VERSION ""

NS_ :

BS_:

BU_: PowertrainControlModule AtmosphericSensor SafetyRestraintSystem2 Aftertreatment_2_GasOutlet Aftertreatment_2_GasIntake DieselParticulateFilterControl Turbocharger SafetyRestraintSystem1 CabDisplay2 Aftertreatment_1_GasOutlet Aftertreatment_1_GasIntake OnBoardDataLogger OffBoardDiagnosticTool2 OffBoardDiagnosticTool1 FileServer ParkingBrakeController SeatController2 FanDriveController SteeringColumnUnit CommunicationUnitRadio CommunicationUnitSatellite CommunicationUnitCellular PropulsionBatteryCharger ChassisController2 ChassisController1 EngineValveControl AuxiliaryHeater2 AuxiliaryHeater1 ClutchUnit RampControl InformationSystem1 SuspensionSystemController2 OilSensor VehicleDynamicStability ExhaustEmissionController TransmissionDisplay2 TransmissionDisplay1 ClimateControl2 WaterPumpController RearAxleSteeringController LightingOperatorControl SeatController1 IgnitionController2 IgnitionController1 TirePressureController CabController2 CabController1 PneumaticSystemController SuspensionSystemController1 HydraulicPumpController EnduranceBrakingSystem RetarderExhaustEngine2 OnBoardDiagnosticUnit HeadwayController RetarderExhaustEngine1 CabDisplay1 ManagementComputer VirtualTerminal OffVehicleGateway PowerTakeOffFront HitchControl AuxiliaryValveControl BodyController TractorTrailerBridge1 StarterSystem ElectricalSystem VehicleSecurity VehicleNavigation AerodynamicControl ElectricalChargingSystem ClimateControl1 TripRecorder InstrumentCluster SuspensionDriveAxle2 SuspensionDriveAxle1 SuspensionSteerAxle SteeringController FuelSystem CruiseControl RetarderDriveline RetarderEngine BrakesDriveAxle2 BrakesDriveAxle1 BrakesSystemController BrakesSteerAxle AxleDrive2 AxleDrive1 AxleSteering PowerTakeOff ShiftConsoleSecondary ShiftConsolePrimary Transmission2 Transmission1 Engine2 Engine1

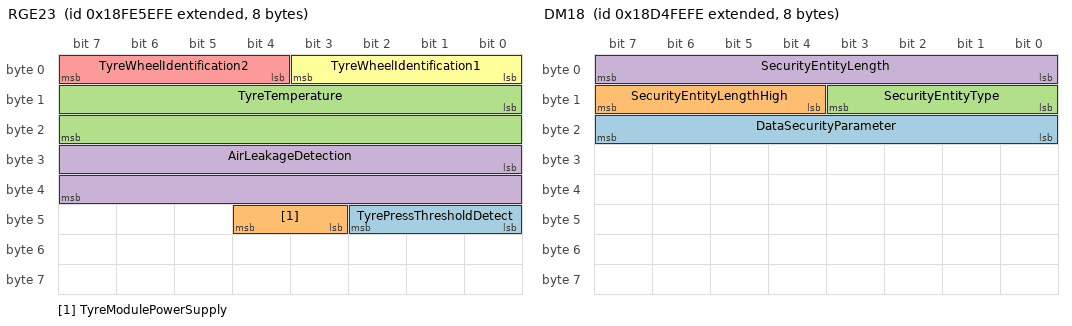
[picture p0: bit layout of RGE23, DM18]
BO_ 2566807294 RGE23: 8 Vector__XXX
 SG_ TyrePressThresholdDetect : 40|3@1+ (1,0) [0|7] "" Vector__XXX
 SG_ TyreModulePowerSupply : 43|2@1+ (1,0) [0|1] "" Vector__XXX
 SG_ TyreTemperature : 8|16@1+ (0.03125,-273) [-273|1735] "캜" Vector__XXX
 SG_ AirLeakageDetection : 24|16@1+ (0.1,0) [0|6425.5] "Pa/s" Vector__XXX
 SG_ TyreWheelIdentification2 : 4|4@1+ (1,0) [0|15] "" Vector__XXX
 SG_ TyreWheelIdentification1 : 0|4@1+ (1,0) [0|15] "" Vector__XXX

BO_ 2566764798 DM26: 8 Vector__XXX
 SG_ NMHCConvertingCatalystCompleted : 60|1@1+ (1,0) [0|1] "" Vector__XXX
 SG_ NMHCConvertingCatalystEnabled : 44|1@1+ (1,0) [0|1] "" Vector__XXX
 SG_ NOxConvertingCatalstAdsrbrCmpltd : 59|1@1+ (1,0) [0|1] "" Vector__XXX
 SG_ NOxConvertingCatalystAdsorberEna : 43|1@1+ (1,0) [0|1] "" Vector__XXX
 SG_ DieselParticulateFilterCompleted : 58|1@1+ (1,0) [0|1] "" Vector__XXX
 SG_ DieselParticulateFilterEnabled : 42|1@1+ (1,0) [0|1] "" Vector__XXX
 SG_ BoostPressureControlSystemComple : 57|1@1+ (1,0) [0|1] "" Vector__XXX
 SG_ BoostPressureControlSystemEnable : 41|1@1- (1,0) [0|0] "" Vector__XXX
 SG_ MisfireMonitoringComplete : 28|1@1+ (1,0) [0|1] "" Vector__XXX
 SG_ MisfireMonitoringEnabled : 24|1@1+ (1,0) [0|0] "" Vector__XXX
 SG_ FuelSystemMonitoringEnabled : 25|1@1+ (1,0) [0|1] "" Vector__XXX
 SG_ ComprehensiveComptMonComplete : 30|1@1+ (1,0) [0|1] "" Vector__XXX
 SG_ ComprehensiveCompMonEnabled : 26|1@1+ (1,0) [0|1] "" Vector__XXX
 SG_ SecondAirSystemMonComplete : 51|1@1+ (1,0) [0|1] "" Vector__XXX
 SG_ SecondAirSystemMonEnabled : 35|1@1+ (1,0) [0|1] "" Vector__XXX
 SG_ OxygenSensorMonComplete : 53|1@1+ (1,0) [0|1] "" Vector__XXX
 SG_ OxygenSensorMonEnabled : 37|1@1+ (1,0) [0|1] "" Vector__XXX
 SG_ OxygenSensorHeaterMonComplete : 54|1@1+ (1,0) [0|1] "" Vector__XXX
 SG_ OxygenSensorHeaterMonEnabled : 38|1@1+ (1,0) [0|1] "" Vector__XXX
 SG_ HeatedCatalystMonComplete : 49|1@1+ (1,0) [0|1] "" Vector__XXX
 SG_ HeatedCatalystMonEnabled : 33|1@1+ (1,0) [0|1] "" Vector__XXX
 SG_ EvaporativeSystemMonComplete : 50|1@1+ (1,0) [0|1] "" Vector__XXX
 SG_ EvaporativeSystemMonEnabled : 34|1@1+ (1,0) [0|1] "" Vector__XXX
 SG_ EGRSystemMonitoringComplete : 55|1@1+ (1,0) [0|1] "" Vector__XXX
 SG_ EGRSystemMonitoringEnabled : 39|1@1+ (1,0) [0|1] "" Vector__XXX
 SG_ ColdStartAidSystemMonComplete : 56|1@1+ (1,0) [0|1] "" Vector__XXX
 SG_ ColdStartAidSystemMonEnabled : 40|1@1+ (1,0) [0|1] "" Vector__XXX
 SG_ CatalystMonComplete : 48|1@1+ (1,0) [0|1] "" Vector__XXX
 SG_ CatalystMonEnabled : 32|1@1+ (1,0) [0|1] "" Vector__XXX
 SG_ ACSystemRefrigerantMonComplete : 52|1@1+ (1,0) [0|1] "" Vector__XXX
 SG_ ACSystemRefrigerantMonEnabled : 36|1@1+ (1,0) [0|1] "" Vector__XXX
 SG_ FuelSystemMonitoringComplete : 29|1@1+ (1,0) [0|1] "" Vector__XXX
 SG_ NumOfWarmUpsSinceDTCsCleared : 16|8@1+ (1,0) [0|250] "" Vector__XXX
 SG_ TimeSinceEngineStart : 0|16@1+ (1,0) [0|64255] "s" Vector__XXX

BO_ 2564095742 DM18: 8 Vector__XXX
 SG_ DataSecurityParameter : 16|8@1+ (1,0) [0|0] "" Vector__XXX
 SG_ SecurityEntityLengthHigh : 12|4@1+ (1,0) [0|255] "Byte" Vector__XXX
 SG_ SecurityEntityType : 8|4@1+ (1,0) [0|15] "" Vector__XXX
 SG_ SecurityEntityLength : 0|8@1+ (1,0) [0|4095] "" Vector__XXX

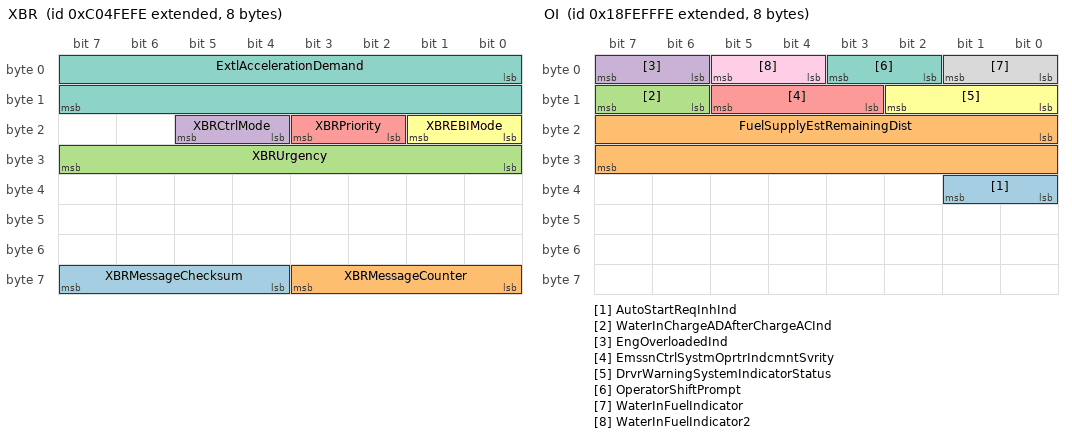
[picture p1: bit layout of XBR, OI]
BO_ 2349137662 XBR: 8 Vector__XXX
 SG_ XBRMessageChecksum : 60|4@1+ (1,0) [0|15] "" Vector__XXX
 SG_ XBRMessageCounter : 56|4@1+ (1,0) [0|15] "" Vector__XXX
 SG_ XBRUrgency : 24|8@1+ (0.4,0) [0|100] "%" Vector__XXX
 SG_ XBRCtrlMode : 20|2@1+ (1,0) [0|3] "" Vector__XXX
 SG_ XBRPriority : 18|2@1+ (1,0) [0|3] "" Vector__XXX
 SG_ XBREBIMode : 16|2@1+ (1,0) [0|3] "" Vector__XXX
 SG_ ExtlAccelerationDemand : 0|16@1+ (0.00048828125,-15.687) [-10|10] "m/s�" Vector__XXX

BO_ 2566848510 OI: 8 Vector__XXX
 SG_ AutoStartReqInhInd : 32|2@1+ (1,0) [0|3] "" Vector__XXX
 SG_ FuelSupplyEstRemainingDist : 16|16@1+ (1,0) [0|64255] "km" Vector__XXX
 SG_ WaterInChargeADAfterChargeACInd : 14|2@1+ (1,0) [0|3] "" Vector__XXX
 SG_ EngOverloadedInd : 6|2@1+ (1,0) [0|3] "" Vector__XXX
 SG_ EmssnCtrlSystmOprtrIndcmntSvrity : 11|3@1+ (1,0) [0|7] "" Vector__XXX
 SG_ DrvrWarningSystemIndicatorStatus : 8|3@1+ (1,0) [0|7] "" Vector__XXX
 SG_ OperatorShiftPrompt : 2|2@1+ (1,0) [0|3] "" Vector__XXX
 SG_ WaterInFuelIndicator : 0|2@1+ (1,0) [0|3] "" Vector__XXX
 SG_ WaterInFuelIndicator2 : 4|2@1+ (1,0) [0|3] "" Vector__XXX

BO_ 2566843134 VW: 8 Vector__XXX
 SG_ AxleLocation M : 0|8@1+ (1,0) [0|255] "" Vector__XXX
 SG_ CargoWeight_30 m48 : 40|16@1+ (2,0) [0|128510] "kg" Vector__XXX
 SG_ CargoWeight_20 m32 : 40|16@1+ (2,0) [0|128510] "kg" Vector__XXX
 SG_ CargoWeight_10 m16 : 40|16@1+ (2,0) [0|128510] "kg" Vector__XXX
 SG_ CargoWeight_00 m0 : 40|16@1+ (2,0) [0|128510] "kg" Vector__XXX
 SG_ TrailerWeight_30 m48 : 24|16@1+ (2,0) [0|128510] "kg" Vector__XXX
 SG_ TrailerWeight_20 m32 : 24|16@1+ (2,0) [0|128510] "kg" Vector__XXX
 SG_ TrailerWeight_10 m16 : 24|16@1+ (2,0) [0|128510] "kg" Vector__XXX
 SG_ TrailerWeight_00 m0 : 24|16@1+ (2,0) [0|128510] "kg" Vector__XXX
 SG_ AxleWeight_30 m48 : 8|16@1+ (0.5,0) [0|32127.5] "kg" Vector__XXX
 SG_ AxleWeight_20 m32 : 8|16@1+ (0.5,0) [0|32127.5] "kg" Vector__XXX
 SG_ AxleWeight_10 m16 : 8|16@1+ (0.5,0) [0|32127.5] "kg" Vector__XXX
 SG_ AxleWeight_00 m0 : 8|16@1+ (0.5,0) [0|32127.5] "kg" Vector__XXX

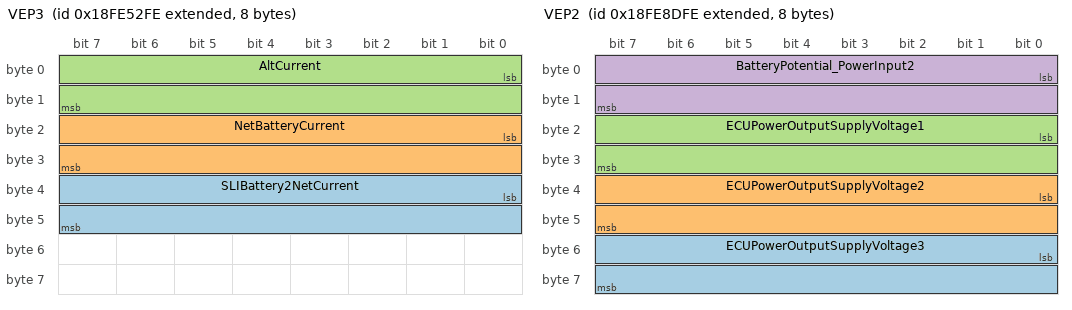
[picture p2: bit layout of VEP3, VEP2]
BO_ 2566804222 VEP3: 8 Vector__XXX
 SG_ SLIBattery2NetCurrent : 32|16@1+ (0.05,-1600) [-1600|1612.75] "A" Vector__XXX
 SG_ NetBatteryCurrent : 16|16@1+ (0.05,-1600) [-1600|1612.75] "A" Vector__XXX
 SG_ AltCurrent : 0|16@1+ (0.05,-1600) [-1600|1612.75] "A" Vector__XXX

BO_ 2566819326 VEP2: 8 Vector__XXX
 SG_ ECUPowerOutputSupplyVoltage3 : 48|16@1+ (0.05,0) [0|3212.75] "V" Vector__XXX
 SG_ ECUPowerOutputSupplyVoltage2 : 32|16@1+ (0.05,0) [0|3212.75] "V" Vector__XXX
 SG_ ECUPowerOutputSupplyVoltage1 : 16|16@1+ (0.05,0) [0|3212.75] "V" Vector__XXX
 SG_ BatteryPotential_PowerInput2 : 0|16@1+ (0.05,0) [0|3212.75] "V" Vector__XXX

BO_ 2566845438 VP1: 8 Vector__XXX
 SG_ Longitude : 32|32@1+ (1E-007,-210) [-210|211.1081215] "deg" Vector__XXX
 SG_ Latitude : 0|32@1+ (1E-007,-210) [-210|211.1081215] "deg" Vector__XXX

BO_ 2566843646 VI: 8 Vector__XXX
 SG_ VehicleIdentificationNumber : 0|8@1+ (1,0) [0|255] "" Vector__XXX

BO_ 2566842366 VH: 8 Vector__XXX
 SG_ TotalPowerTakeoffHours : 32|32@1+ (0.05,0) [0|210554060.75] "h" Vector__XXX
 SG_ TotalVehicleHours : 0|32@1+ (0.05,0) [0|210554060.75] "h" Vector__XXX

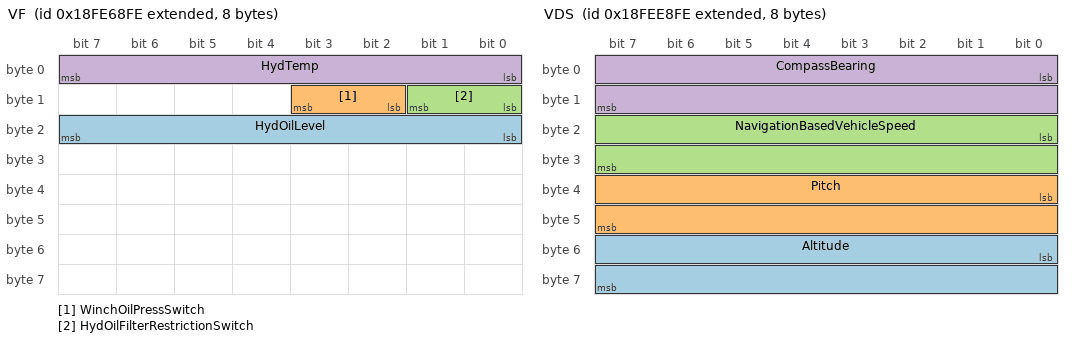
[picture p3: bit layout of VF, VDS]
BO_ 2566809854 VF: 8 Vector__XXX
 SG_ HydOilLevel : 16|8@1+ (0.4,0) [0|100] "%" Vector__XXX
 SG_ WinchOilPressSwitch : 10|2@1+ (1,0) [0|3] "" Vector__XXX
 SG_ HydOilFilterRestrictionSwitch : 8|2@1+ (1,0) [0|3] "" Vector__XXX
 SG_ HydTemp : 0|8@1+ (1,-40) [-40|210] "캜" Vector__XXX

BO_ 2566842622 VDS: 8 Vector__XXX
 SG_ Altitude : 48|16@1+ (0.125,-2500) [-2500|5531.875] "m" Vector__XXX
 SG_ Pitch : 32|16@1+ (0.0078125,-200) [-200|301.992] "deg" Vector__XXX
 SG_ NavigationBasedVehicleSpeed : 16|16@1+ (0.00390625,0) [0|250.996] "km/h" Vector__XXX
 SG_ CompassBearing : 0|16@1+ (0.0078125,0) [0|501.99] "deg" Vector__XXX

BO_ 2566832638 VDHR: 8 Vector__XXX
 SG_ HighResolutionTripDistance : 32|32@1+ (5,0) [0|21055406075] "m" Vector__XXX
 SG_ HghRsolutionTotalVehicleDistance : 0|32@1+ (5,0) [0|21055406075] "m" Vector__XXX

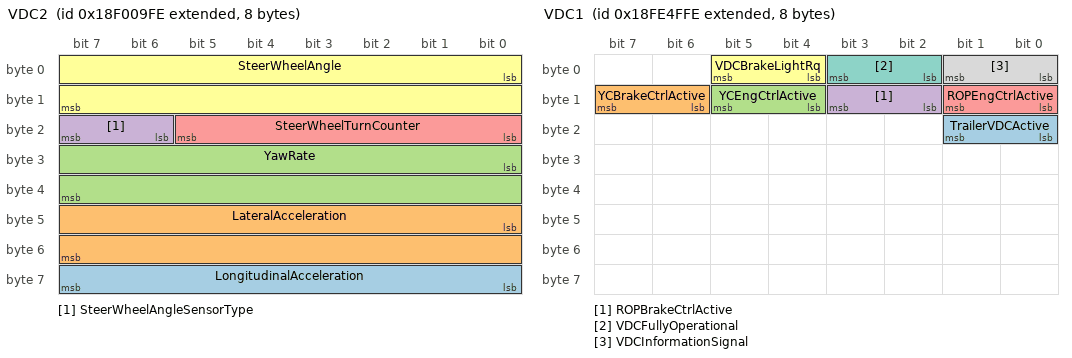
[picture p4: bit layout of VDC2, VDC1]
BO_ 2565868030 VDC2: 8 Vector__XXX
 SG_ LongitudinalAcceleration : 56|8@1+ (0.1,-12.5) [-12.5|12.5] "m/s�" Vector__XXX
 SG_ LateralAcceleration : 40|16@1+ (0.00048828125,-15.687) [-15.687|15.687] "m/s�" Vector__XXX
 SG_ YawRate : 24|16@1+ (0.0001220703125,-3.92) [-3.92|3.92] "rad/s" Vector__XXX
 SG_ SteerWheelAngleSensorType : 22|2@1+ (1,0) [0|3] "" Vector__XXX
 SG_ SteerWheelTurnCounter : 16|6@1+ (1,-32) [-10|10] "turns" Vector__XXX
 SG_ SteerWheelAngle : 0|16@1+ (0.0009765625,-31.374) [-31.374|31.374] "rad" Vector__XXX

BO_ 2566803454 VDC1: 8 Vector__XXX
 SG_ TrailerVDCActive : 16|2@1+ (1,0) [0|3] "" Vector__XXX
 SG_ YCBrakeCtrlActive : 14|2@1+ (1,0) [0|3] "" Vector__XXX
 SG_ YCEngCtrlActive : 12|2@1+ (1,0) [0|3] "" Vector__XXX
 SG_ ROPBrakeCtrlActive : 10|2@1+ (1,0) [0|3] "" Vector__XXX
 SG_ ROPEngCtrlActive : 8|2@1+ (1,0) [0|3] "" Vector__XXX
 SG_ VDCBrakeLightRq : 4|2@1+ (1,0) [0|3] "" Vector__XXX
 SG_ VDCFullyOperational : 2|2@1+ (1,0) [0|3] "" Vector__XXX
 SG_ VDCInformationSignal : 0|2@1+ (1,0) [0|3] "" Vector__XXX

BO_ 2566840574 VD: 8 Vector__XXX
 SG_ TotalVehicleDistance : 32|32@1+ (0.125,0) [0|526385151.875] "km" Vector__XXX
 SG_ TripDistance : 0|32@1+ (0.125,0) [0|526385151.875] "km" Vector__XXX

BO_ 2633938686 TVI: 8 Vector__XXX
 SG_ TripCruiseDistance : 16|32@1+ (0.125,0) [0|526385151.875] "km" Vector__XXX
 SG_ TripMaxVehicleSpeed : 0|16@1+ (0.00390625,0) [0|250.996] "km/h" Vector__XXX

BO_ 2633937150 TTI2: 20 Vector__XXX
 SG_ TripAirCompressorOnTime : 128|32@1+ (0.05,0) [0|210554060.75] "h" Vector__XXX
 SG_ TripIdleTime : 96|32@1+ (0.05,0) [0|210554060.75] "h" Vector__XXX
 SG_ TripEngRunningTime : 64|32@1+ (0.05,0) [0|210554060.75] "h" Vector__XXX
 SG_ TripCruiseTime : 0|32@1+ (0.05,0) [0|210554060.75] "h" Vector__XXX
 SG_ TripPTOGovernorTime : 32|32@1+ (0.05,0) [0|210554060.75] "h" Vector__XXX

BO_ 2633938174 TTI1: 16 Vector__XXX
 SG_ TripTimeInDerateByEng : 96|32@1+ (0.05,0) [0|210554060.75] "h" Vector__XXX
 SG_ TripTimeInGearDown : 64|32@1+ (0.05,0) [0|210554060.75] "h" Vector__XXX
 SG_ TripTimeInTopGear : 32|32@1+ (0.05,0) [0|210554060.75] "h" Vector__XXX
 SG_ TripTimeInVSL : 0|32@1+ (0.05,0) [0|210554060.75] "h" Vector__XXX

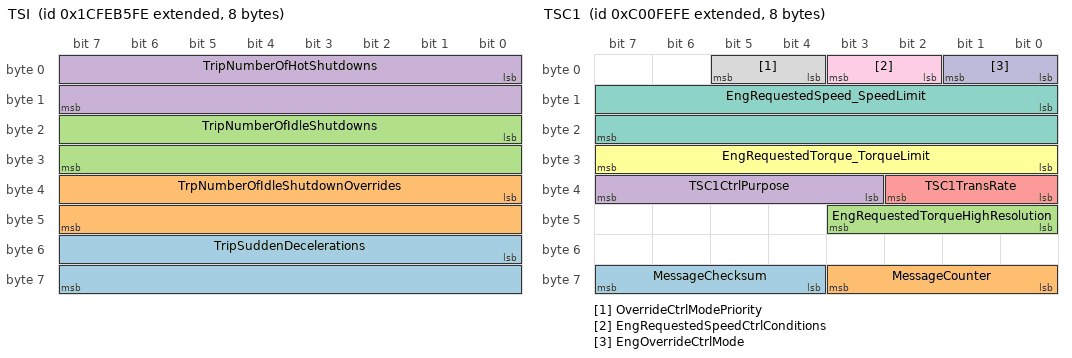
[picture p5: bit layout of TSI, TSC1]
BO_ 2633938430 TSI: 8 Vector__XXX
 SG_ TripSuddenDecelerations : 48|16@1+ (1,0) [0|64255] "" Vector__XXX
 SG_ TrpNumberOfIdleShutdownOverrides : 32|16@1+ (1,0) [0|64255] "" Vector__XXX
 SG_ TripNumberOfIdleShutdowns : 16|16@1+ (1,0) [0|64255] "" Vector__XXX
 SG_ TripNumberOfHotShutdowns : 0|16@1+ (1,0) [0|64255] "" Vector__XXX

BO_ 2348875518 TSC1: 8 Vector__XXX
 SG_ MessageChecksum : 60|4@1+ (1,0) [0|15] "" Vector__XXX
 SG_ MessageCounter : 56|4@1+ (1,0) [0|15] "" Vector__XXX
 SG_ EngRequestedTorqueHighResolution : 40|4@1+ (0.125,0) [0|0.875] "%" Vector__XXX
 SG_ TSC1CtrlPurpose : 35|5@1+ (1,0) [0|31] "" Vector__XXX
 SG_ TSC1TransRate : 32|3@1+ (1,0) [0|7] "" Vector__XXX
 SG_ EngRequestedTorque_TorqueLimit : 24|8@1+ (1,-125) [-125|125] "%" Vector__XXX
 SG_ EngRequestedSpeed_SpeedLimit : 8|16@1+ (0.125,0) [0|8031.875] "rpm" Vector__XXX
 SG_ OverrideCtrlModePriority : 4|2@1+ (1,0) [0|3] "" Vector__XXX
 SG_ EngRequestedSpeedCtrlConditions : 2|2@1+ (1,0) [0|3] "" Vector__XXX
 SG_ EngOverrideCtrlMode : 0|2@1+ (1,0) [0|3] "" Vector__XXX

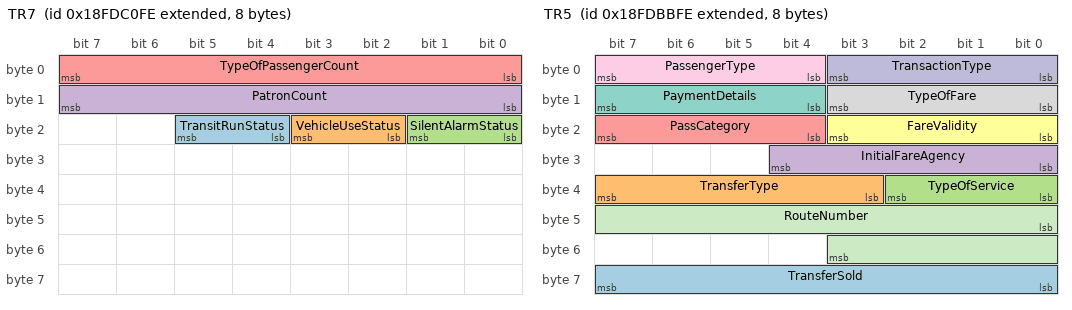
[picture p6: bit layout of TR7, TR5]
BO_ 2566766846 TR7: 8 Vector__XXX
 SG_ TransitRunStatus : 20|2@1+ (1,0) [0|3] "" Vector__XXX
 SG_ VehicleUseStatus : 18|2@1+ (1,0) [0|3] "" Vector__XXX
 SG_ SilentAlarmStatus : 16|2@1+ (1,0) [0|3] "" Vector__XXX
 SG_ PatronCount : 8|8@1+ (1,0) [0|250] "" Vector__XXX
 SG_ TypeOfPassengerCount : 0|8@1+ (1,0) [0|255] "" Vector__XXX

BO_ 2566765310 TR6: 8 Vector__XXX
 SG_ FareboxAlarmIdentifier : 8|7@1+ (1,0) [0|127] "" Vector__XXX
 SG_ FareboxEmergencyStatus : 0|2@1+ (1,0) [0|3] "" Vector__XXX

BO_ 2566765566 TR5: 8 Vector__XXX
 SG_ TransferSold : 56|8@1+ (1,0) [0|255] "" Vector__XXX
 SG_ TransferType : 35|5@1+ (1,0) [0|31] "" Vector__XXX
 SG_ TypeOfService : 32|3@1+ (1,0) [0|7] "" Vector__XXX
 SG_ InitialFareAgency : 24|5@1+ (1,0) [1|31] "" Vector__XXX
 SG_ PassCategory : 20|4@1+ (1,0) [0|15] "" Vector__XXX
 SG_ FareValidity : 16|4@1+ (1,0) [0|15] "" Vector__XXX
 SG_ PaymentDetails : 12|4@1+ (1,0) [0|15] "" Vector__XXX
 SG_ TypeOfFare : 8|4@1+ (1,0) [0|15] "" Vector__XXX
 SG_ PassengerType : 4|4@1+ (1,0) [0|15] "" Vector__XXX
 SG_ TransactionType : 0|4@1+ (1,0) [0|15] "" Vector__XXX
 SG_ RouteNumber : 40|12@1+ (1,0) [0|4095] "" Vector__XXX

BO_ 2566765822 TR4: 15 Vector__XXX
 SG_ DriversFareboxSecurityCode : 104|16@1+ (1,0) [0|65535] "" Vector__XXX
 SG_ AssignedBlock : 88|16@1+ (1,0) [0|65535] "" Vector__XXX
 SG_ AssignedRun : 72|16@1+ (1,0) [0|65535] "" Vector__XXX
 SG_ AssignedRoute : 56|16@1+ (1,0) [0|65535] "" Vector__XXX
 SG_ PatternNumber : 40|16@1+ (1,0) [0|65535] "" Vector__XXX
 SG_ TripNumber : 24|16@1+ (1,0) [0|65535] "" Vector__XXX
 SG_ FarePresets : 16|8@1+ (1,0) [0|255] "" Vector__XXX
 SG_ TripDirection : 8|4@1+ (1,0) [0|15] "" Vector__XXX
 SG_ TripStatus : 2|3@1+ (1,0) [0|7] "" Vector__XXX
 SG_ FareboxServiceStatus : 0|2@1+ (1,0) [0|3] "" Vector__XXX

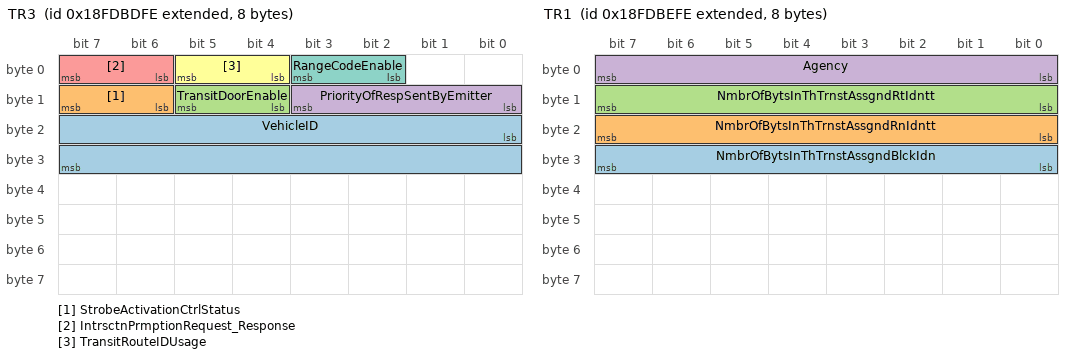
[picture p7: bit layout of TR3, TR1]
BO_ 2566766078 TR3: 8 Vector__XXX
 SG_ VehicleID : 16|16@1+ (1,0) [0|65534] "" Vector__XXX
 SG_ StrobeActivationCtrlStatus : 14|2@1+ (1,0) [0|3] "" Vector__XXX
 SG_ TransitDoorEnable : 12|2@1+ (1,0) [0|3] "" Vector__XXX
 SG_ PriorityOfRespSentByEmitter : 8|4@1+ (1,0) [0|15] "" Vector__XXX
 SG_ IntrsctnPrmptionRequest_Response : 6|2@1+ (1,0) [0|3] "" Vector__XXX
 SG_ TransitRouteIDUsage : 4|2@1+ (1,0) [0|3] "" Vector__XXX
 SG_ RangeCodeEnable : 2|2@1+ (1,0) [0|3] "" Vector__XXX

BO_ 2566766590 TR2: 8 Vector__XXX
 SG_ NmbrOfBytsInThMlpstIdntification : 0|8@1+ (1,0) [0|100] "bytes" Vector__XXX

BO_ 2566766334 TR1: 8 Vector__XXX
 SG_ NmbrOfBytsInThTrnstAssgndBlckIdn : 24|8@1+ (1,0) [1|100] "bytes" Vector__XXX
 SG_ NmbrOfBytsInThTrnstAssgndRnIdntt : 16|8@1+ (1,0) [1|100] "bytes" Vector__XXX
 SG_ NmbrOfBytsInThTrnstAssgndRtIdntt : 8|8@1+ (1,0) [1|100] "bytes" Vector__XXX
 SG_ Agency : 0|8@1+ (1,0) [0|255] "" Vector__XXX

BO_ 2561605374 TPRS: 8 Vector__XXX
 SG_ TireLocation M : 0|8@1+ (1,0) [0|255] "" Vector__XXX
 SG_ ReferenceTirePressSetting_33 m51 : 8|8@1+ (8,0) [0|2000] "kPa" Vector__XXX
 SG_ ReferenceTirePressSetting_32 m50 : 8|8@1+ (8,0) [0|2000] "kPa" Vector__XXX
 SG_ ReferenceTirePressSetting_31 m49 : 8|8@1+ (8,0) [0|2000] "kPa" Vector__XXX
 SG_ ReferenceTirePressSetting_30 m48 : 8|8@1+ (8,0) [0|2000] "kPa" Vector__XXX
 SG_ ReferenceTirePressSetting_23 m35 : 8|8@1+ (8,0) [0|2000] "kPa" Vector__XXX
 SG_ ReferenceTirePressSetting_22 m34 : 8|8@1+ (8,0) [0|2000] "kPa" Vector__XXX
 SG_ ReferenceTirePressSetting_21 m33 : 8|8@1+ (8,0) [0|2000] "kPa" Vector__XXX
 SG_ ReferenceTirePressSetting_20 m32 : 8|8@1+ (8,0) [0|2000] "kPa" Vector__XXX
 SG_ ReferenceTirePressSetting_13 m19 : 8|8@1+ (8,0) [0|2000] "kPa" Vector__XXX
 SG_ ReferenceTirePressSetting_12 m18 : 8|8@1+ (8,0) [0|2000] "kPa" Vector__XXX
 SG_ ReferenceTirePressSetting_11 m17 : 8|8@1+ (8,0) [0|2000] "kPa" Vector__XXX
 SG_ ReferenceTirePressSetting_10 m16 : 8|8@1+ (8,0) [0|2000] "kPa" Vector__XXX
 SG_ ReferenceTirePressSetting_01 m1 : 8|8@1+ (8,0) [0|2000] "kPa" Vector__XXX
 SG_ ReferenceTirePressSetting_00 m0 : 8|8@1+ (8,0) [0|2000] "kPa" Vector__XXX

BO_ 2566765054 TPRI: 8 Vector__XXX
 SG_ ReferenceTirePress_33 m51 : 8|8@1+ (8,0) [0|2000] "kPa" Vector__XXX
 SG_ ReferenceTirePress_32 m50 : 8|8@1+ (8,0) [0|2000] "kPa" Vector__XXX
 SG_ ReferenceTirePress_31 m49 : 8|8@1+ (8,0) [0|2000] "kPa" Vector__XXX
 SG_ ReferenceTirePress_30 m48 : 8|8@1+ (8,0) [0|2000] "kPa" Vector__XXX
 SG_ ReferenceTirePress_23 m35 : 8|8@1+ (8,0) [0|2000] "kPa" Vector__XXX
 SG_ ReferenceTirePress_22 m34 : 8|8@1+ (8,0) [0|2000] "kPa" Vector__XXX
 SG_ ReferenceTirePress_21 m33 : 8|8@1+ (8,0) [0|2000] "kPa" Vector__XXX
 SG_ ReferenceTirePress_20 m32 : 8|8@1+ (8,0) [0|2000] "kPa" Vector__XXX
 SG_ ReferenceTirePress_13 m19 : 8|8@1+ (8,0) [0|2000] "kPa" Vector__XXX
 SG_ ReferenceTirePress_12 m18 : 8|8@1+ (8,0) [0|2000] "kPa" Vector__XXX
 SG_ ReferenceTirePress_11 m17 : 8|8@1+ (8,0) [0|2000] "kPa" Vector__XXX
 SG_ ReferenceTirePress_10 m16 : 8|8@1+ (8,0) [0|2000] "kPa" Vector__XXX
 SG_ ReferenceTirePress_01 m1 : 8|8@1+ (8,0) [0|2000] "kPa" Vector__XXX
 SG_ ReferenceTirePress_00 m0 : 8|8@1+ (8,0) [0|2000] "kPa" Vector__XXX
 SG_ TireLocation M : 0|8@1+ (1,0) [0|255] "" Vector__XXX

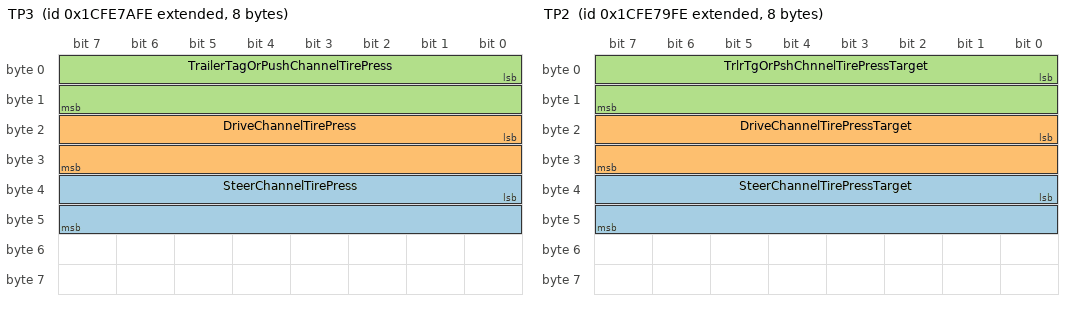
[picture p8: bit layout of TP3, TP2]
BO_ 2633923326 TP3: 8 Vector__XXX
 SG_ SteerChannelTirePress : 32|16@1+ (0.5,0) [0|32127.5] "kPa" Vector__XXX
 SG_ DriveChannelTirePress : 16|16@1+ (0.5,0) [0|32127.5] "kPa" Vector__XXX
 SG_ TrailerTagOrPushChannelTirePress : 0|16@1+ (0.5,0) [0|32127.5] "kPa" Vector__XXX

BO_ 2633923070 TP2: 8 Vector__XXX
 SG_ SteerChannelTirePressTarget : 32|16@1+ (0.5,0) [0|32127.5] "kPa" Vector__XXX
 SG_ DriveChannelTirePressTarget : 16|16@1+ (0.5,0) [0|32127.5] "kPa" Vector__XXX
 SG_ TrlrTgOrPshChnnelTirePressTarget : 0|16@1+ (0.5,0) [0|32127.5] "kPa" Vector__XXX

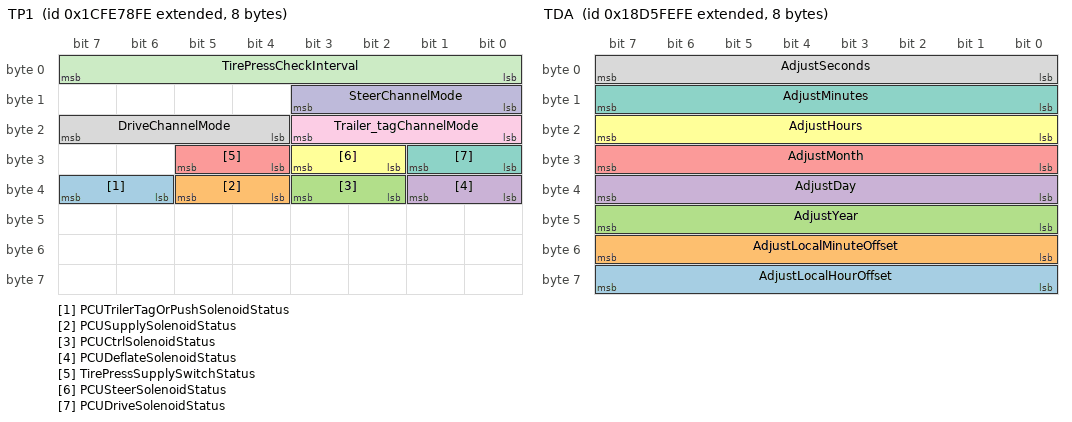
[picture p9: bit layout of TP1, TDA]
BO_ 2633922814 TP1: 8 Vector__XXX
 SG_ PCUTrilerTagOrPushSolenoidStatus : 38|2@1+ (1,0) [0|3] "" Vector__XXX
 SG_ PCUSupplySolenoidStatus : 36|2@1+ (1,0) [0|3] "" Vector__XXX
 SG_ PCUCtrlSolenoidStatus : 34|2@1+ (1,0) [0|3] "" Vector__XXX
 SG_ PCUDeflateSolenoidStatus : 32|2@1+ (1,0) [0|3] "" Vector__XXX
 SG_ TirePressSupplySwitchStatus : 28|2@1+ (1,0) [0|3] "" Vector__XXX
 SG_ PCUSteerSolenoidStatus : 26|2@1+ (1,0) [0|3] "" Vector__XXX
 SG_ PCUDriveSolenoidStatus : 24|2@1+ (1,0) [0|3] "" Vector__XXX
 SG_ DriveChannelMode : 20|4@1+ (1,0) [0|15] "" Vector__XXX
 SG_ Trailer_tagChannelMode : 16|4@1+ (1,0) [0|15] "" Vector__XXX
 SG_ SteerChannelMode : 8|4@1+ (1,0) [0|15] "" Vector__XXX
 SG_ TirePressCheckInterval : 0|8@1+ (1,0) [0|250] "min" Vector__XXX

BO_ 2566845694 TIRE1: 8 Vector__XXX
 SG_ ExTirePressSupport : 38|2@1+ (1,0) [0|3] "" Vector__XXX
 SG_ TirePressThresholdDetection_13 m19 : 61|3@1+ (1,0) [0|7] "" Vector__XXX
 SG_ TirePressThresholdDetection_12 m18 : 61|3@1+ (1,0) [0|7] "" Vector__XXX
 SG_ TirePressThresholdDetection_11 m17 : 61|3@1+ (1,0) [0|7] "" Vector__XXX
 SG_ TirePressThresholdDetection_10 m16 : 61|3@1+ (1,0) [0|7] "" Vector__XXX
 SG_ TirePressThresholdDetection_01 m1 : 61|3@1+ (1,0) [0|7] "" Vector__XXX
 SG_ TirePress_33 m51 : 8|8@1+ (4,0) [0|1000] "kPa" Vector__XXX
 SG_ TirePress_32 m50 : 8|8@1+ (4,0) [0|1000] "kPa" Vector__XXX
 SG_ TirePress_31 m49 : 8|8@1+ (4,0) [0|1000] "kPa" Vector__XXX
 SG_ TirePress_30 m48 : 8|8@1+ (4,0) [0|1000] "kPa" Vector__XXX
 SG_ TirePress_23 m35 : 8|8@1+ (4,0) [0|1000] "kPa" Vector__XXX
 SG_ TirePress_22 m34 : 8|8@1+ (4,0) [0|1000] "kPa" Vector__XXX
 SG_ TirePress_21 m33 : 8|8@1+ (4,0) [0|1000] "kPa" Vector__XXX
 SG_ TirePress_20 m32 : 8|8@1+ (4,0) [0|1000] "kPa" Vector__XXX
 SG_ TirePress_13 m19 : 8|8@1+ (4,0) [0|1000] "kPa" Vector__XXX
 SG_ TirePress_12 m18 : 8|8@1+ (4,0) [0|1000] "kPa" Vector__XXX
 SG_ TirePress_11 m17 : 8|8@1+ (4,0) [0|1000] "kPa" Vector__XXX
 SG_ TirePress_10 m16 : 8|8@1+ (4,0) [0|1000] "kPa" Vector__XXX
 SG_ TireAirLeakageRate_33 m51 : 40|16@1+ (0.1,0) [0|6425.5] "Pa/s" Vector__XXX
 SG_ TireAirLeakageRate_32 m50 : 40|16@1+ (0.1,0) [0|6425.5] "Pa/s" Vector__XXX
 SG_ TireAirLeakageRate_31 m49 : 40|16@1+ (0.1,0) [0|6425.5] "Pa/s" Vector__XXX
 SG_ TireAirLeakageRate_30 m48 : 40|16@1+ (0.1,0) [0|6425.5] "Pa/s" Vector__XXX
 SG_ TireAirLeakageRate_23 m35 : 40|16@1+ (0.1,0) [0|6425.5] "Pa/s" Vector__XXX
 SG_ TireAirLeakageRate_22 m34 : 40|16@1+ (0.1,0) [0|6425.5] "Pa/s" Vector__XXX
 SG_ TireAirLeakageRate_21 m33 : 40|16@1+ (0.1,0) [0|6425.5] "Pa/s" Vector__XXX
 SG_ TireAirLeakageRate_20 m32 : 40|16@1+ (0.1,0) [0|6425.5] "Pa/s" Vector__XXX
 SG_ TireAirLeakageRate_13 m19 : 40|16@1+ (0.1,0) [0|6425.5] "Pa/s" Vector__XXX
 SG_ TireAirLeakageRate_12 m18 : 40|16@1+ (0.1,0) [0|6425.5] "Pa/s" Vector__XXX
 SG_ TireAirLeakageRate_11 m17 : 40|16@1+ (0.1,0) [0|6425.5] "Pa/s" Vector__XXX
 SG_ TireAirLeakageRate_10 m16 : 40|16@1+ (0.1,0) [0|6425.5] "Pa/s" Vector__XXX
 SG_ TireAirLeakageRate_01 m1 : 40|16@1+ (0.1,0) [0|6425.5] "Pa/s" Vector__XXX
 SG_ TireAirLeakageRate_00 m0 : 40|16@1+ (0.1,0) [0|6425.5] "Pa/s" Vector__XXX
 SG_ CTIWheelSensorStatus_33 m51 : 32|2@1+ (1,0) [0|3] "" Vector__XXX
 SG_ CTIWheelSensorStatus_32 m50 : 32|2@1+ (1,0) [0|3] "" Vector__XXX
 SG_ CTIWheelSensorStatus_31 m49 : 32|2@1+ (1,0) [0|3] "" Vector__XXX
 SG_ CTIWheelSensorStatus_30 m48 : 32|2@1+ (1,0) [0|3] "" Vector__XXX
 SG_ CTIWheelSensorStatus_23 m35 : 32|2@1+ (1,0) [0|3] "" Vector__XXX
 SG_ CTIWheelSensorStatus_22 m34 : 32|2@1+ (1,0) [0|3] "" Vector__XXX
 SG_ CTIWheelSensorStatus_21 m33 : 32|2@1+ (1,0) [0|3] "" Vector__XXX
 SG_ CTIWheelSensorStatus_20 m32 : 32|2@1+ (1,0) [0|3] "" Vector__XXX
 SG_ CTIWheelSensorStatus_13 m19 : 32|2@1+ (1,0) [0|3] "" Vector__XXX
 SG_ CTIWheelSensorStatus_12 m18 : 32|2@1+ (1,0) [0|3] "" Vector__XXX
 SG_ CTIWheelSensorStatus_11 m17 : 32|2@1+ (1,0) [0|3] "" Vector__XXX
 SG_ CTIWheelSensorStatus_10 m16 : 32|2@1+ (1,0) [0|3] "" Vector__XXX
 SG_ CTIWheelSensorStatus_01 m1 : 32|2@1+ (1,0) [0|3] "" Vector__XXX
 SG_ CTIWheelEndElectricalFault_33 m51 : 36|2@1+ (1,0) [0|3] "" Vector__XXX
 SG_ CTIWheelEndElectricalFault_32 m50 : 36|2@1+ (1,0) [0|3] "" Vector__XXX
 SG_ CTIWheelEndElectricalFault_31 m49 : 36|2@1+ (1,0) [0|3] "" Vector__XXX
 SG_ CTIWheelEndElectricalFault_30 m48 : 36|2@1+ (1,0) [0|3] "" Vector__XXX
 SG_ CTIWheelEndElectricalFault_23 m35 : 36|2@1+ (1,0) [0|3] "" Vector__XXX
 SG_ CTIWheelEndElectricalFault_22 m34 : 36|2@1+ (1,0) [0|3] "" Vector__XXX
 SG_ CTIWheelEndElectricalFault_21 m33 : 36|2@1+ (1,0) [0|3] "" Vector__XXX
 SG_ CTIWheelEndElectricalFault_20 m32 : 36|2@1+ (1,0) [0|3] "" Vector__XXX
 SG_ CTIWheelEndElectricalFault_13 m19 : 36|2@1+ (1,0) [0|3] "" Vector__XXX
 SG_ CTIWheelEndElectricalFault_12 m18 : 36|2@1+ (1,0) [0|3] "" Vector__XXX
 SG_ CTIWheelEndElectricalFault_11 m17 : 36|2@1+ (1,0) [0|3] "" Vector__XXX
 SG_ CTIWheelEndElectricalFault_10 m16 : 36|2@1+ (1,0) [0|3] "" Vector__XXX
 SG_ CTIWheelEndElectricalFault_01 m1 : 36|2@1+ (1,0) [0|3] "" Vector__XXX
 SG_ CTITireStatus_33 m51 : 34|2@1+ (1,0) [0|3] "" Vector__XXX
 SG_ CTITireStatus_32 m50 : 34|2@1+ (1,0) [0|3] "" Vector__XXX
 SG_ CTITireStatus_31 m49 : 34|2@1+ (1,0) [0|3] "" Vector__XXX
 SG_ CTITireStatus_30 m48 : 34|2@1+ (1,0) [0|3] "" Vector__XXX
 SG_ CTITireStatus_23 m35 : 34|2@1+ (1,0) [0|3] "" Vector__XXX
 SG_ CTITireStatus_22 m34 : 34|2@1+ (1,0) [0|3] "" Vector__XXX
 SG_ CTITireStatus_21 m33 : 34|2@1+ (1,0) [0|3] "" Vector__XXX
 SG_ CTITireStatus_20 m32 : 34|2@1+ (1,0) [0|3] "" Vector__XXX
 SG_ CTITireStatus_13 m19 : 34|2@1+ (1,0) [0|3] "" Vector__XXX
 SG_ CTITireStatus_12 m18 : 34|2@1+ (1,0) [0|3] "" Vector__XXX
 SG_ CTITireStatus_11 m17 : 34|2@1+ (1,0) [0|3] "" Vector__XXX
 SG_ CTITireStatus_10 m16 : 34|2@1+ (1,0) [0|3] "" Vector__XXX
 SG_ CTITireStatus_01 m1 : 34|2@1+ (1,0) [0|3] "" Vector__XXX
 SG_ TireTemp_11 m17 : 16|16@1+ (0.03125,-273) [-273|1735] "캜" Vector__XXX
 SG_ TireTemp_33 m51 : 16|16@1+ (0.03125,-273) [-273|1735] "캜" Vector__XXX
 SG_ TireTemp_32 m50 : 16|16@1+ (0.03125,-273) [-273|1735] "캜" Vector__XXX
 SG_ TireTemp_31 m49 : 16|16@1+ (0.03125,-273) [-273|1735] "캜" Vector__XXX
 SG_ TireTemp_30 m48 : 16|16@1+ (0.03125,-273) [-273|1735] "캜" Vector__XXX
 SG_ TireTemp_23 m35 : 16|16@1+ (0.03125,-273) [-273|1735] "캜" Vector__XXX
 SG_ TireTemp_22 m34 : 16|16@1+ (0.03125,-273) [-273|1735] "캜" Vector__XXX
 SG_ TireTemp_21 m33 : 16|16@1+ (0.03125,-273) [-273|1735] "캜" Vector__XXX
 SG_ TireTemp_20 m32 : 16|16@1+ (0.03125,-273) [-273|1735] "캜" Vector__XXX
 SG_ TireTemp_13 m19 : 16|16@1+ (0.03125,-273) [-273|1735] "캜" Vector__XXX
 SG_ TireTemp_12 m18 : 16|16@1+ (0.03125,-273) [-273|1735] "캜" Vector__XXX
 SG_ TireTemp_10 m16 : 16|16@1+ (0.03125,-273) [-273|1735] "캜" Vector__XXX
 SG_ TireTemp_01 m1 : 16|16@1+ (0.03125,-273) [-273|1735] "캜" Vector__XXX
 SG_ TireTemp_00 m0 : 16|16@1+ (0.03125,-273) [-273|1735] "캜" Vector__XXX
 SG_ TirePressThresholdDetection_33 m51 : 61|3@1+ (1,0) [0|7] "" Vector__XXX
 SG_ TirePressThresholdDetection_32 m50 : 61|3@1+ (1,0) [0|7] "" Vector__XXX
 SG_ TirePressThresholdDetection_31 m49 : 61|3@1+ (1,0) [0|7] "" Vector__XXX
 SG_ TirePressThresholdDetection_30 m48 : 61|3@1+ (1,0) [0|7] "" Vector__XXX
 SG_ TirePressThresholdDetection_23 m35 : 61|3@1+ (1,0) [0|7] "" Vector__XXX
 SG_ TirePressThresholdDetection_22 m34 : 61|3@1+ (1,0) [0|7] "" Vector__XXX
 SG_ TirePressThresholdDetection_21 m33 : 61|3@1+ (1,0) [0|7] "" Vector__XXX
 SG_ TirePressThresholdDetection_20 m32 : 61|3@1+ (1,0) [0|7] "" Vector__XXX
 SG_ TirePressThresholdDetection_00 m0 : 61|3@1+ (1,0) [0|7] "" Vector__XXX
 SG_ TirePress_01 m1 : 8|8@1+ (4,0) [0|1000] "kPa" Vector__XXX
 SG_ TirePress_00 m0 : 8|8@1+ (4,0) [0|1000] "kPa" Vector__XXX
 SG_ CTIWheelSensorStatus_00 m0 : 32|2@1+ (1,0) [0|3] "" Vector__XXX
 SG_ CTIWheelEndElectricalFault_00 m0 : 36|2@1+ (1,0) [0|3] "" Vector__XXX
 SG_ CTITireStatus_00 m0 : 34|2@1+ (1,0) [0|3] "" Vector__XXX
 SG_ TireLocation M : 0|8@1+ (1,0) [0|255] "" Vector__XXX

BO_ 2633939966 TFI: 16 Vector__XXX
 SG_ TripFanOnTimeDueToTheA_CSystem : 96|32@1+ (0.05,0) [0|210554060.75] "h" Vector__XXX
 SG_ TripFanOnTimeDueToAManualSwitch : 64|32@1+ (0.05,0) [0|210554060.75] "h" Vector__XXX
 SG_ TripFanOnTimeDueToTheEngSystem : 32|32@1+ (0.05,0) [0|210554060.75] "h" Vector__XXX
 SG_ TripFanOnTime : 0|32@1+ (0.05,0) [0|210554060.75] "h" Vector__XXX

BO_ 2633939710 TDI: 12 Vector__XXX
 SG_ TripDistanceInTopGear : 64|32@1+ (0.125,0) [0|526385151.875] "km" Vector__XXX
 SG_ TripGearDownDistance : 32|32@1+ (0.125,0) [0|526385151.875] "km" Vector__XXX
 SG_ TripDistanceOnVSL : 0|32@1+ (0.125,0) [0|526385151.875] "km" Vector__XXX

BO_ 2564161278 TDA: 8 Vector__XXX
 SG_ AdjustLocalHourOffset : 56|8@1+ (1,-125) [-24|23] "h" Vector__XXX
 SG_ AdjustLocalMinuteOffset : 48|8@1+ (1,-125) [-59|59] "min" Vector__XXX
 SG_ AdjustYear : 40|8@1+ (1,1985) [1985|2235] "years" Vector__XXX
 SG_ AdjustDay : 32|8@1+ (0.25,0) [0.25|31.75] "days" Vector__XXX
 SG_ AdjustMonth : 24|8@1+ (1,0) [1|12] "months" Vector__XXX
 SG_ AdjustHours : 16|8@1+ (1,0) [0|23] "h" Vector__XXX
 SG_ AdjustMinutes : 8|8@1+ (1,0) [0|59] "min" Vector__XXX
 SG_ AdjustSeconds : 0|8@1+ (0.25,0) [0|59.75] "s" Vector__XXX

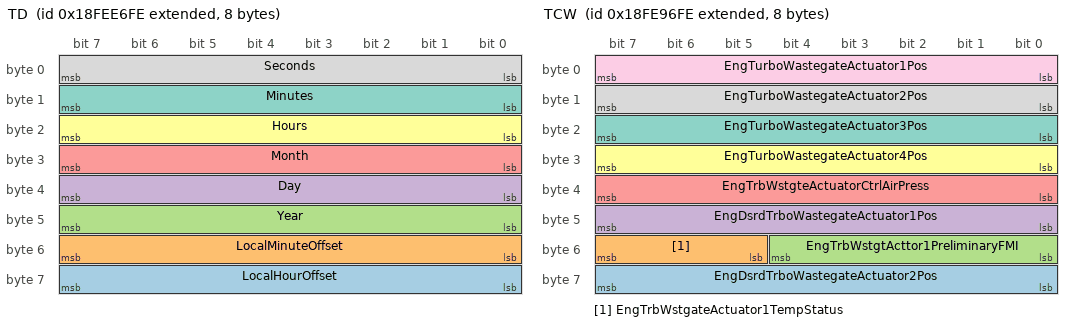
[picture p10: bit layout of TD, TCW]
BO_ 2566842110 TD: 8 Vector__XXX
 SG_ LocalHourOffset : 56|8@1+ (1,-125) [-23|23] "h" Vector__XXX
 SG_ LocalMinuteOffset : 48|8@1+ (1,-125) [-59|59] "min" Vector__XXX
 SG_ Year : 40|8@1+ (1,1985) [1985|2235] "years" Vector__XXX
 SG_ Day : 32|8@1+ (0.25,0) [0.25|31.75] "days" Vector__XXX
 SG_ Month : 24|8@1+ (1,0) [1|12] "months" Vector__XXX
 SG_ Hours : 16|8@1+ (1,0) [0|23] "h" Vector__XXX
 SG_ Minutes : 8|8@1+ (1,0) [0|59] "min" Vector__XXX
 SG_ Seconds : 0|8@1+ (0.25,0) [0|59.75] "s" Vector__XXX

BO_ 2566821630 TCW: 8 Vector__XXX
 SG_ EngDsrdTrboWastegateActuator2Pos : 56|8@1+ (0.4,0) [0|100] "%" Vector__XXX
 SG_ EngTrbWstgateActuator1TempStatus : 53|3@1+ (1,0) [0|7] "" Vector__XXX
 SG_ EngTrbWstgtActtor1PreliminaryFMI : 48|5@1+ (1,0) [0|31] "" Vector__XXX
 SG_ EngDsrdTrboWastegateActuator1Pos : 40|8@1+ (0.4,0) [0|100] "%" Vector__XXX
 SG_ EngTrbWstgteActuatorCtrlAirPress : 32|8@1+ (4,0) [0|1000] "kPa" Vector__XXX
 SG_ EngTurboWastegateActuator4Pos : 24|8@1+ (0.4,0) [0|100] "%" Vector__XXX
 SG_ EngTurboWastegateActuator3Pos : 16|8@1+ (0.4,0) [0|100] "%" Vector__XXX
 SG_ EngTurboWastegateActuator2Pos : 8|8@1+ (0.4,0) [0|100] "%" Vector__XXX
 SG_ EngTurboWastegateActuator1Pos : 0|8@1+ (0.4,0) [0|100] "%" Vector__XXX

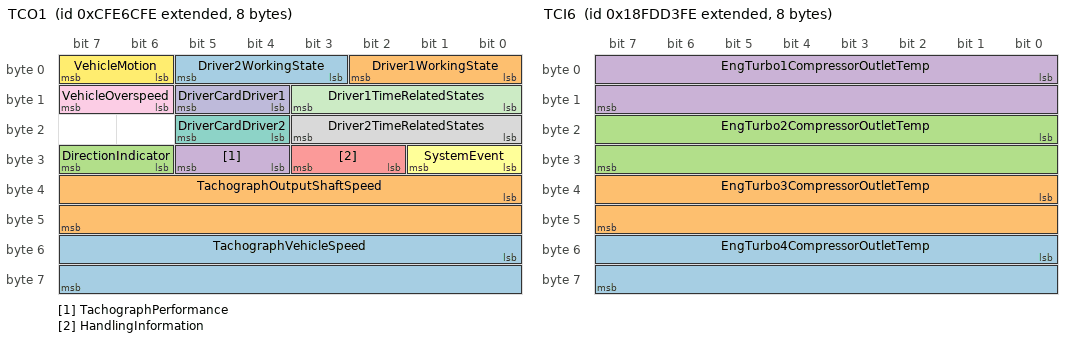
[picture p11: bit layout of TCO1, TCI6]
BO_ 2365484286 TCO1: 8 Vector__XXX
 SG_ TachographVehicleSpeed : 48|16@1+ (0.00390625,0) [0|250.996] "km/h" Vector__XXX
 SG_ TachographOutputShaftSpeed : 32|16@1+ (0.125,0) [0|8031.875] "rpm" Vector__XXX
 SG_ DirectionIndicator : 30|2@1+ (1,0) [0|3] "" Vector__XXX
 SG_ TachographPerformance : 28|2@1+ (1,0) [0|3] "" Vector__XXX
 SG_ HandlingInformation : 26|2@1+ (1,0) [0|3] "" Vector__XXX
 SG_ SystemEvent : 24|2@1+ (1,0) [0|3] "" Vector__XXX
 SG_ DriverCardDriver2 : 20|2@1+ (1,0) [0|3] "" Vector__XXX
 SG_ Driver2TimeRelatedStates : 16|4@1+ (1,0) [0|15] "" Vector__XXX
 SG_ VehicleOverspeed : 14|2@1+ (1,0) [0|3] "" Vector__XXX
 SG_ DriverCardDriver1 : 12|2@1+ (1,0) [0|3] "" Vector__XXX
 SG_ Driver1TimeRelatedStates : 8|4@1+ (1,0) [0|15] "" Vector__XXX
 SG_ VehicleMotion : 6|2@1+ (1,0) [0|3] "" Vector__XXX
 SG_ Driver2WorkingState : 3|3@1+ (1,0) [0|7] "" Vector__XXX
 SG_ Driver1WorkingState : 0|3@1+ (1,0) [0|7] "" Vector__XXX

BO_ 2566771710 TCI6: 8 Vector__XXX
 SG_ EngTurbo4CompressorOutletTemp : 48|16@1+ (0.03125,-273) [-273|1734.96875] "캜" Vector__XXX
 SG_ EngTurbo3CompressorOutletTemp : 32|16@1+ (0.03125,-273) [-273|1734.96875] "캜" Vector__XXX
 SG_ EngTurbo2CompressorOutletTemp : 16|16@1+ (0.03125,-273) [-273|1734.96875] "캜" Vector__XXX
 SG_ EngTurbo1CompressorOutletTemp : 0|16@1+ (0.03125,-273) [-273|1734.96875] "캜" Vector__XXX

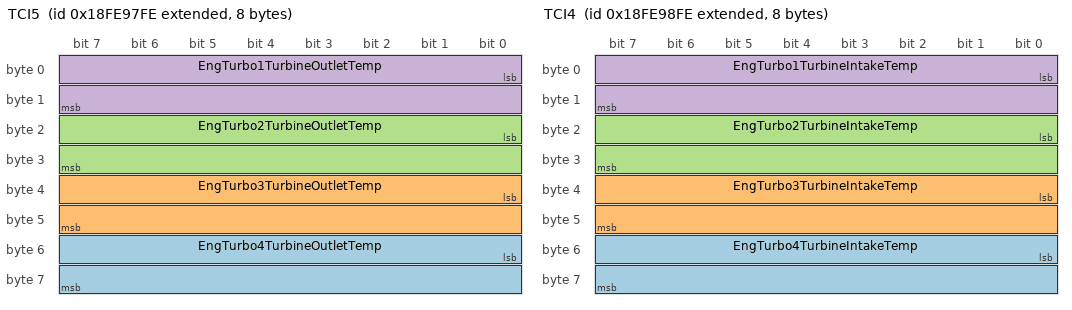
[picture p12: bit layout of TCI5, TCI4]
BO_ 2566821886 TCI5: 8 Vector__XXX
 SG_ EngTurbo4TurbineOutletTemp : 48|16@1+ (0.03125,-273) [-273|1734.96875] "캜" Vector__XXX
 SG_ EngTurbo3TurbineOutletTemp : 32|16@1+ (0.03125,-273) [-273|1734.96875] "캜" Vector__XXX
 SG_ EngTurbo2TurbineOutletTemp : 16|16@1+ (0.03125,-273) [-273|1734.96875] "캜" Vector__XXX
 SG_ EngTurbo1TurbineOutletTemp : 0|16@1+ (0.03125,-273) [-273|1734.96875] "캜" Vector__XXX

BO_ 2566822142 TCI4: 8 Vector__XXX
 SG_ EngTurbo4TurbineIntakeTemp : 48|16@1+ (0.03125,-273) [-273|1734.96875] "캜" Vector__XXX
 SG_ EngTurbo3TurbineIntakeTemp : 32|16@1+ (0.03125,-273) [-273|1734.96875] "캜" Vector__XXX
 SG_ EngTurbo2TurbineIntakeTemp : 16|16@1+ (0.03125,-273) [-273|1734.96875] "캜" Vector__XXX
 SG_ EngTurbo1TurbineIntakeTemp : 0|16@1+ (0.03125,-273) [-273|1734.96875] "캜" Vector__XXX

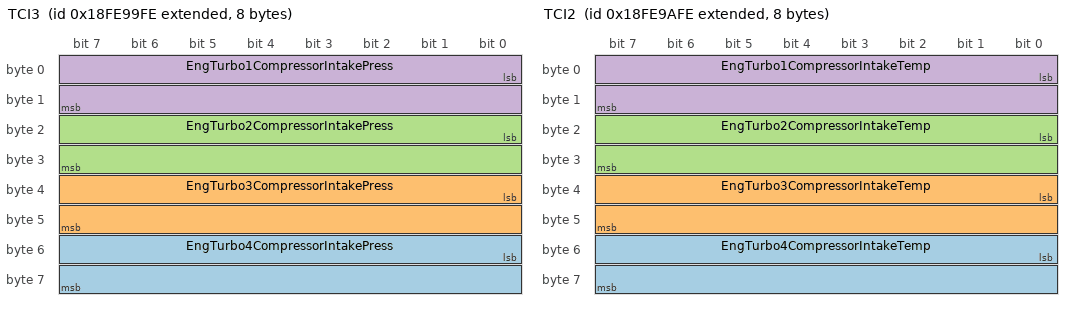
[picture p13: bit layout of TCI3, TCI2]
BO_ 2566822398 TCI3: 8 Vector__XXX
 SG_ EngTurbo4CompressorIntakePress : 48|16@1+ (0.0078125,-250) [-250|251.99] "kPa" Vector__XXX
 SG_ EngTurbo3CompressorIntakePress : 32|16@1+ (0.0078125,-250) [-250|251.99] "kPa" Vector__XXX
 SG_ EngTurbo2CompressorIntakePress : 16|16@1+ (0.0078125,-250) [-250|251.99] "kPa" Vector__XXX
 SG_ EngTurbo1CompressorIntakePress : 0|16@1+ (0.0078125,-250) [-250|251.99] "kPa" Vector__XXX

BO_ 2566822654 TCI2: 8 Vector__XXX
 SG_ EngTurbo4CompressorIntakeTemp : 48|16@1+ (0.03125,-273) [-273|1734.96875] "캜" Vector__XXX
 SG_ EngTurbo3CompressorIntakeTemp : 32|16@1+ (0.03125,-273) [-273|1734.96875] "캜" Vector__XXX
 SG_ EngTurbo2CompressorIntakeTemp : 16|16@1+ (0.03125,-273) [-273|1734.96875] "캜" Vector__XXX
 SG_ EngTurbo1CompressorIntakeTemp : 0|16@1+ (0.03125,-273) [-273|1734.96875] "캜" Vector__XXX

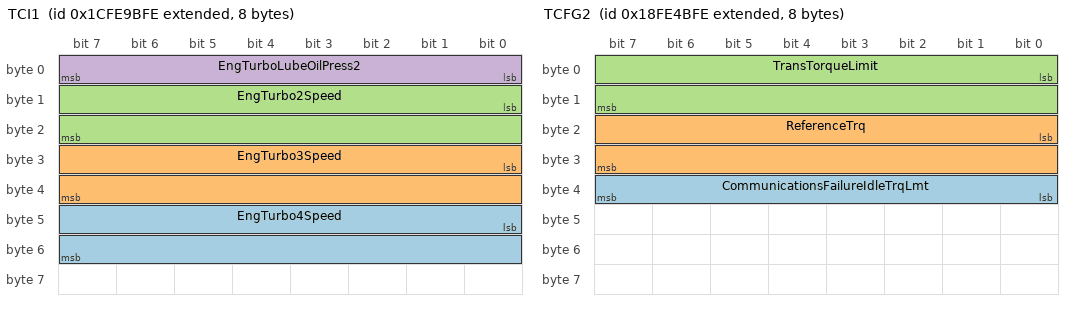
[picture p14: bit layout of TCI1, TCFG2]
BO_ 2633931774 TCI1: 8 Vector__XXX
 SG_ EngTurbo4Speed : 40|16@1+ (4,0) [0|257020] "rpm" Vector__XXX
 SG_ EngTurbo3Speed : 24|16@1+ (4,0) [0|257020] "rpm" Vector__XXX
 SG_ EngTurbo2Speed : 8|16@1+ (4,0) [0|257020] "rpm" Vector__XXX
 SG_ EngTurboLubeOilPress2 : 0|8@1+ (4,0) [0|1000] "kPa" Vector__XXX

BO_ 2566802430 TCFG2: 8 Vector__XXX
 SG_ CommunicationsFailureIdleTrqLmt : 32|8@1+ (1,-125) [0|125] "%" Vector__XXX
 SG_ ReferenceTrq : 16|16@1+ (1,0) [0|64255] "Nm" Vector__XXX
 SG_ TransTorqueLimit : 0|16@1+ (1,0) [0|64255] "Nm" Vector__XXX

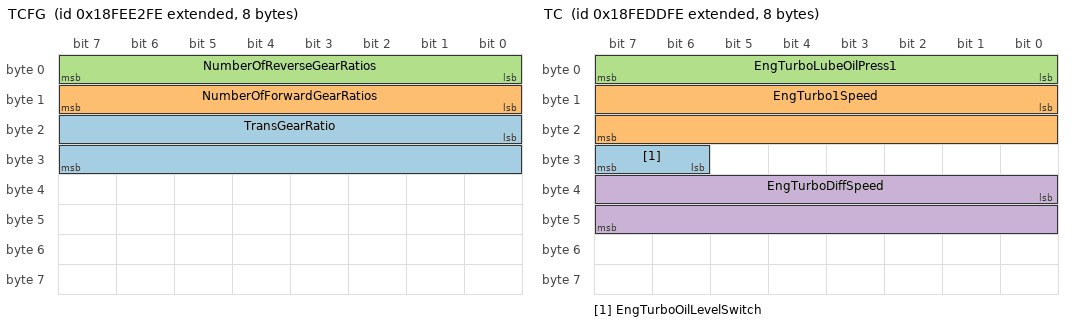
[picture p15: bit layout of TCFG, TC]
BO_ 2566841086 TCFG: 8 Vector__XXX
 SG_ TransGearRatio : 16|16@1+ (0.001,0) [0|64.255] "" Vector__XXX
 SG_ NumberOfForwardGearRatios : 8|8@1+ (1,0) [0|125] "" Vector__XXX
 SG_ NumberOfReverseGearRatios : 0|8@1+ (1,0) [0|125] "" Vector__XXX

BO_ 2348941054 TC1: 8 Vector__XXX
 SG_ AutoNeutralReq : 48|2@1+ (1,0) [0|3] "" Vector__XXX
 SG_ TransMode8 : 62|2@1+ (1,0) [0|3] "" Vector__XXX
 SG_ TransMode7 : 60|2@1+ (1,0) [0|3] "" Vector__XXX
 SG_ TransMode6 : 58|2@1+ (1,0) [0|3] "" Vector__XXX
 SG_ TransMode5 : 56|2@1+ (1,0) [0|3] "" Vector__XXX
 SG_ TrnsShftSlectorDisplayModeSwitch : 54|2@1+ (1,0) [0|3] "" Vector__XXX
 SG_ TransRequestedLaunchGear : 50|4@1+ (1,0) [0|15] "" Vector__XXX
 SG_ TransMode4 : 46|2@1+ (1,0) [0|3] "" Vector__XXX
 SG_ TransMode3 : 44|2@1+ (1,0) [0|3] "" Vector__XXX
 SG_ TransMode2 : 42|2@1+ (1,0) [0|3] "" Vector__XXX
 SG_ TransMode1 : 40|2@1+ (1,0) [0|3] "" Vector__XXX
 SG_ TransLoadReductionInhibitRq : 38|2@1+ (1,0) [0|3] "" Vector__XXX
 SG_ DisengageDiffLockRqCentralRear : 36|2@1+ (1,0) [0|3] "" Vector__XXX
 SG_ DisengageDiffLockRqCentralFront : 34|2@1+ (1,0) [0|3] "" Vector__XXX
 SG_ DisengageDiffLockRqCentral : 32|2@1+ (1,0) [0|3] "" Vector__XXX
 SG_ DisengageDiffLockRqRearAxle2 : 30|2@1+ (1,0) [0|3] "" Vector__XXX
 SG_ DisengageDiffLockRqRearAxle1 : 28|2@1+ (1,0) [0|3] "" Vector__XXX
 SG_ DisengageDiffLockRqFrontAxle2 : 26|2@1+ (1,0) [0|3] "" Vector__XXX
 SG_ DisengageDiffLockRqFrontAxle1 : 24|2@1+ (1,0) [0|3] "" Vector__XXX
 SG_ TransRequestedGear : 16|8@1+ (1,-125) [-64|64] "" Vector__XXX
 SG_ RequestedPercentClutchSlip : 8|8@1+ (0.4,0) [0|100] "%" Vector__XXX
 SG_ TransReverseGearShiftInhibitRq : 6|2@1+ (1,0) [0|3] "" Vector__XXX
 SG_ DisengageDrivelineRq : 4|2@1+ (1,0) [0|3] "" Vector__XXX
 SG_ TrnsTrqeConverterLockupDisableRq : 2|2@1+ (1,0) [0|3] "" Vector__XXX
 SG_ TransGearShiftInhibitRq : 0|2@1+ (1,0) [0|3] "" Vector__XXX

BO_ 2566839806 TC: 8 Vector__XXX
 SG_ EngTurboOilLevelSwitch : 30|2@1+ (1,0) [0|3] "" Vector__XXX
 SG_ EngTurbo1Speed : 8|16@1+ (4,0) [0|257020] "rpm" Vector__XXX
 SG_ EngTurboLubeOilPress1 : 0|8@1+ (4,0) [0|1000] "kPa" Vector__XXX
 SG_ EngTurboDiffSpeed : 32|16@1+ (4,0) [0|257020] "rpm" Vector__XXX

BO_ 2633911806 TAVG: 8 Vector__XXX
 SG_ EngTotalAverageFuelEconomy : 16|16@1+ (0.001953125,0) [0|125.498046875] "km/L" Vector__XXX
 SG_ EngTotalAverageFuelRate : 0|16@1+ (0.05,0) [0|3212.75] "l/h" Vector__XXX

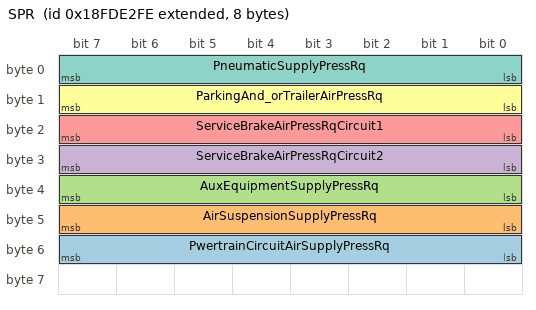
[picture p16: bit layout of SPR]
BO_ 2566775550 SPR: 8 Vector__XXX
 SG_ PwertrainCircuitAirSupplyPressRq : 48|8@1+ (8,0) [0|2000] "kPa" Vector__XXX
 SG_ AirSuspensionSupplyPressRq : 40|8@1+ (8,0) [0|2000] "kPa" Vector__XXX
 SG_ AuxEquipmentSupplyPressRq : 32|8@1+ (8,0) [0|2000] "kPa" Vector__XXX
 SG_ ServiceBrakeAirPressRqCircuit2 : 24|8@1+ (8,0) [0|2000] "kPa" Vector__XXX
 SG_ ServiceBrakeAirPressRqCircuit1 : 16|8@1+ (8,0) [0|2000] "kPa" Vector__XXX
 SG_ ParkingAnd_orTrailerAirPressRq : 8|8@1+ (8,0) [0|2000] "kPa" Vector__XXX
 SG_ PneumaticSupplyPressRq : 0|8@1+ (8,0) [0|2000] "kPa" Vector__XXX

BO_ 2566819838 SP2: 8 Vector__XXX
 SG_ EngExtlShutdownAirSupplyPress : 0|16@1+ (0.5,0) [0|32127.5] "kPa" Vector__XXX

BO_ 2566839038 SOFT: 8 Vector__XXX
 SG_ NmbrOfSftwreIdentificationFields : 0|8@1+ (1,0) [0|125] "steps" Vector__XXX
 SG_ SoftwareIdentification : 8|8@1+ (1,0) [0|255] "" Vector__XXX

BO_ 2566841598 SHUTDN: 8 Vector__XXX
 SG_ EngOilPressSw : 62|2@1+ (1,0) [0|3] "" Vector__XXX
 SG_ ClntLvlEngPrtctionShutdownStatus : 60|2@1+ (1,0) [0|3] "" Vector__XXX
 SG_ PTOShutdownHasShutdownEng : 58|2@1+ (1,0) [0|3] "" Vector__XXX
 SG_ EngAirShutoffStatus : 56|2@1+ (1,0) [0|3] "" Vector__XXX
 SG_ EngOverspeedTest : 54|2@1+ (1,0) [0|3] "" Vector__XXX
 SG_ EngAirShutoffCmdStatus : 52|2@1+ (1,0) [0|3] "" Vector__XXX
 SG_ EngAlarmOutputCmdStatus : 50|2@1+ (1,0) [0|3] "" Vector__XXX
 SG_ EngAlarmAcknowledge : 48|2@1+ (1,0) [0|3] "" Vector__XXX
 SG_ EngProtectionSystemConfig : 46|2@1+ (1,0) [0|3] "" Vector__XXX
 SG_ EngProtectionSystemTimerState : 38|2@1+ (1,0) [0|3] "" Vector__XXX
 SG_ EngProtectionSystemTimerOverride : 36|2@1+ (1,0) [0|3] "" Vector__XXX
 SG_ EngPrtctnSystmApprachingShutdown : 34|2@1+ (1,0) [0|3] "" Vector__XXX
 SG_ EngPrtectionSystemHasShutdownEng : 32|2@1+ (1,0) [0|3] "" Vector__XXX
 SG_ EngWaitToStartLamp : 24|2@1+ (1,0) [0|3] "" Vector__XXX
 SG_ RefrigerantHighPressSwitch : 20|2@1+ (1,0) [0|3] "" Vector__XXX
 SG_ RefrigerantLowPressSwitch : 18|2@1+ (1,0) [0|3] "" Vector__XXX
 SG_ A_CHighPressFanSwitch : 16|2@1+ (1,0) [0|3] "" Vector__XXX
 SG_ EngIdleShutdownTimerFunction : 14|2@1+ (1,0) [0|3] "" Vector__XXX
 SG_ EngIdleShutdownTimerState : 6|2@1+ (1,0) [0|3] "" Vector__XXX
 SG_ EngIdleShutdownTimerOverride : 4|2@1+ (1,0) [0|3] "" Vector__XXX
 SG_ EngIdleShutdownDriverAlertMode : 2|2@1+ (1,0) [0|3] "" Vector__XXX
 SG_ EngIdleShutdownHasShutdownEng : 0|2@1+ (1,0) [0|3] "" Vector__XXX

CM_ BO_ 2566807294 "Running Gear Equipment #2/3
Message to transmit data of the towed vehicle to the towing vehicle. See ISO 11992-2.";
CM_ SG_ 2566807294 TyrePressThresholdDetect "Signal indicating the pressure level of the tyre.";
CM_ SG_ 2566807294 TyreModulePowerSupply "Signal indicating the power supply of the tyre module is sufficient to achieve the specified performance of the module.";
CM_ SG_ 2566807294 TyreTemperature "The temperature measured by the tyre module.";
CM_ SG_ 2566807294 AirLeakageDetection "The pressure loss of a tyre.";
CM_ SG_ 2566807294 TyreWheelIdentification2 "First part of the identification number of the tyre or whee (number of axles).";
CM_ SG_ 2566807294 TyreWheelIdentification1 "First part of the identification number of the tyre or whee (position on each axle).";
CM_ BO_ 2566764798 "Diagnostic Readiness 3
This message conveys information useful in determining whether the OBD System has a defect or not.";
CM_ SG_ 2566764798 NumOfWarmUpsSinceDTCsCleared "Number of warm-up cycles since all DTCs were cleared (via an external test equipment or possibly, a battery disconnect).  A warm-up is defined in the OBD regulations to be sufficient vehicle operation such that coolant temperature rises by at least ...";
CM_ SG_ 2566764798 TimeSinceEngineStart "RUNTM shall increment while the engine is running.  It shall freeze if the engine stalls.  RUNTM shall be reset to zero during every control module power-up and when entering the key-on, engine off position.  RUNTM is limited to 65,535 seconds and ...";
CM_ BO_ 2564095742 "Data Security
The data security parameter group is used to send security entities of a given type and length. These entities are data produced by or used for applications of cryptography and supporting procedures to ensure data security.";
CM_ SG_ 2564095742 DataSecurityParameter "This Parameter is used to send the data for the Data Security message. There are presently four different items defined. The Data Security Parameter shall be sent least significant byte first.";
CM_ SG_ 2564095742 SecurityEntityType "This 4-bit parameter that indicates whether the data in the following Security Entity parameter is to be used as a Long Seed, Long Key, Session Key, or Certificate.";
CM_ SG_ 2564095742 SecurityEntityLength "This 12-bit parameter contains the length, in bytes, of the Data Security Parameter.";
CM_ BO_ 2349137662 "External Brake Request
Used for brake control by an external device. The receiver is the brake system controlling the axle and/or wheel brakes. This system has to process the demanded acceleration.  Note: This PGN shall not be used for external ...";
CM_ SG_ 2349137662 XBRMessageChecksum "The XBR message checksum is used to verify the signal path from the demanding device to the brake controller on electronic brake systems.  The support of this parameter is mandatory if PGN 1024 is supported as there is no means to indicate 뱊ot ...";
CM_ SG_ 2349137662 XBRMessageCounter "The XBR message counter is to verify the signal path from the demanding device to the brake controller on electronic brake systems..  The support of this parameter is mandatory.
Note:  The initial value of the 4 bit message counter for the first ...";
CM_ SG_ 2349137662 XBRUrgency "The idea of the urgency value is to adjust the endurance brake integration behavior in the EBS system according to the traffic situation.
On low urgency values (0%, e.g. downhill cruise control or preceding vehicle far ahead) the brake system shall ...";
CM_ SG_ 2349137662 XBRCtrlMode "The XBR Control Mode is used as an input to the brake system and defines how the external acceleration demand has to be realized.
00 - Override disabled - Disable any existing control commanded by the source of this command.
01 - Acceleration ...";
CM_ SG_ 2349137662 XBRPriority "The XBR Priority is used as an input to the brake system to manage the priority of overlapping external and internal requests.
00 - Highest priority - used for emergency situations, e.g. for future Collision Avoidance System.  This mode overrides ...";
CM_ SG_ 2349137662 XBREBIMode "The XBR EBI (Endurance Brake Integration) Mode is used as an input for the brake system to prescribe the use of endurance brakes like retarders or engine brakes.
00 - No Endurance Brake Integration allowed
The demanded acceleration must be ...";
CM_ SG_ 2349137662 ExtlAccelerationDemand "Parameter provided to the brake system from external sources. This is the acceleration which the brake system is expected to realize. It is specified as an absolute acceleration in reference to the road.  Positive values lead to increasing vehicle ...";
CM_ BO_ 2566848510 "Operator indicators";
CM_ SG_ 2566848510 AutoStartReqInhInd "State signal indicating an engine request for the Automatic Start Request Inhibit Indicator to be active or inactive. The start inhibit indicator can be of lamp or text form, located on (but not limited to) the shift console, instrument cluster, or ...";
CM_ SG_ 2566848510 FuelSupplyEstRemainingDist "Estimated remaining distance based on existing fuel supply.";
CM_ SG_ 2566848510 WaterInChargeADAfterChargeACInd "Signal which indicates the presence of water in charge air duct after charge air cooler.

00 - No
01 - Yes
10 - Error
11 - Not available";
CM_ SG_ 2566848510 EngOverloadedInd "Signal which indicates that the engine is overloaded.

00 - No
01 - Yes
10 - Error
11 - Not available";
CM_ SG_ 2566848510 EmssnCtrlSystmOprtrIndcmntSvrity "Severity status of the operator inducement system for anomalies with the emission control system, such as tampering, low diesel exhaust fluid (reagent) quality, diesel exhaust fluid (reagent) tank level, or EGR system errors.  Higher numerical ...";
CM_ SG_ 2566848510 DrvrWarningSystemIndicatorStatus "The desired illumination of the Euro VI defined driver warning system indicator for relevant malfunctions and diesel exhaust fluid (reagent) tank low level.  Used for Euro VI implementations.  See Euro VI implementing regulation Annex XIII, Section ...";
CM_ SG_ 2566848510 OperatorShiftPrompt "Command to activate an indicator that advises the operator to shift to a different gear.  Typically this would be used as part of a fuel economy improvement or drivability aid.
00 - indicator(s) inactive
01 - upshift indicator active
10 - ...";
CM_ SG_ 2566848510 WaterInFuelIndicator "Signal which indicates the presence of water in the fuel.

00 - No
01 - Yes
10 - Error
11 - Not available";
CM_ SG_ 2566848510 WaterInFuelIndicator2 "A second indicator of the presense of water in the fuel.  See also SPN 97.

00 - No
01 - Yes
10 - Error
11 - Not available";
CM_ BO_ 2566843134 "Vehicle Weight
NOTE뻉equest has to be responded to with as many messages as necessary to transmit all available information.";
CM_ SG_ 2566843134 AxleLocation "To identify to which of several similar devices (such as tires or fuel tanks) the information applies.
The low order 4 bits represent a position number, counting left to right when facing in the direction of normal vehicle travel (forward).
The ...";
CM_ SG_ 2566843134 CargoWeight_30 "The mass of freight carried.";
CM_ SG_ 2566843134 CargoWeight_20 "The mass of freight carried.";
CM_ SG_ 2566843134 CargoWeight_10 "The mass of freight carried.";
CM_ SG_ 2566843134 CargoWeight_00 "The mass of freight carried.";
CM_ SG_ 2566843134 TrailerWeight_30 "Total mass of freight-carrying vehicle designed to be pulled by truck, including the weight of the contents.";
CM_ SG_ 2566843134 TrailerWeight_20 "Total mass of freight-carrying vehicle designed to be pulled by truck, including the weight of the contents.";
CM_ SG_ 2566843134 TrailerWeight_10 "Total mass of freight-carrying vehicle designed to be pulled by truck, including the weight of the contents.";
CM_ SG_ 2566843134 TrailerWeight_00 "Total mass of freight-carrying vehicle designed to be pulled by truck, including the weight of the contents.";
CM_ SG_ 2566843134 AxleWeight_30 "Total mass imposed by the tires on the road surface at the specified axle.";
CM_ SG_ 2566843134 AxleWeight_20 "Total mass imposed by the tires on the road surface at the specified axle.";
CM_ SG_ 2566843134 AxleWeight_10 "Total mass imposed by the tires on the road surface at the specified axle.";
CM_ SG_ 2566843134 AxleWeight_00 "Total mass imposed by the tires on the road surface at the specified axle.";
CM_ BO_ 2566804222 "Vehicle Electrical Power 3
This contains high resolution/range parameters reported from the alternator or power generation components.";
CM_ SG_ 2566804222 SLIBattery2NetCurrent "Net flow of electrical current into/out of the second battery or second set of batteries used for starting the engine, for lighting, and for ignition (SLI).";
CM_ SG_ 2566804222 NetBatteryCurrent "Net flow of electrical current into/out of the first battery or first set of batteries used for starting the engine, for lighting, and for ignition (SLI).  If more than one battery is included in the first set of batteries and the net current for ...";
CM_ SG_ 2566804222 AltCurrent "This parameter indicates the amount of electrical current output from the alternator of the main vehicle.  Alternator Current (SPN 115) has a lower range and resolution.";
CM_ BO_ 2566819326 "Vehicle Electrical Power 2
Voltage data for the main vehicle Power Distribution system.";
CM_ SG_ 2566819326 ECUPowerOutputSupplyVoltage3 "The third power output from an ECU.";
CM_ SG_ 2566819326 ECUPowerOutputSupplyVoltage2 "The second power output from an ECU.";
CM_ SG_ 2566819326 ECUPowerOutputSupplyVoltage1 "The first power output from an ECU.";
CM_ SG_ 2566819326 BatteryPotential_PowerInput2 "This parameter measures the second source of battery potential as measured at the input of the ECU/actuator etc. coming from one or more batteries, irrespective of the distance between the component and the battery.  This SPN is also used when ECUs ...";
CM_ BO_ 2566845438 "Vehicle Position 1";
CM_ SG_ 2566845438 Longitude "Longitude position of the vehicle.";
CM_ SG_ 2566845438 Latitude "Latitude position of the vehicle.";
CM_ BO_ 2566843646 "Vehicle Identification
Byte: 1-n Vehicle Identification Number
Delimiter (ASCII �*�)";
CM_ SG_ 2566843646 VehicleIdentificationNumber "Vehicle Identification Number (VIN) as assigned by the vehicle manufacturer.

NOTE The ASCII character �*� is reserved as a delimiter.";
CM_ BO_ 2566842366 "Vehicle Hours";
CM_ SG_ 2566842366 TotalPowerTakeoffHours "Accumulated time of operation of power takeoff device.";
CM_ SG_ 2566842366 TotalVehicleHours "Accumulated time of operation of vehicle.";
CM_ BO_ 2566809854 "Vehicle Fluids";
CM_ SG_ 2566809854 HydOilLevel "This parameter indicates the level of the hydraulic fluid in tank as a ratio of current volume to total tank volume.  This parameter is intended for reporting the hydraulic fluid level in the system tank or reservoir.  This hydraulic fluid is for ...";
CM_ SG_ 2566809854 WinchOilPressSwitch "State of switch used to determine if Winch Oil Pressure is above desired minimum

00 NOT OK- Oil pressure is too low
01 OK - Oil pressure is above minimum
10 Error - Switch state cannot be determined
11 Not Available";
CM_ SG_ 2566809854 HydOilFilterRestrictionSwitch "This switch indicates whether hydraulic oil filter is clogged. This is not the transmission oil filter restriction switch, which is SPN 3359.

00 No restriction
01 Restriction exists on oil filter
10 Error
11 Not Available";
CM_ SG_ 2566809854 HydTemp "Temperature of hydraulic fluid.";
CM_ BO_ 2566842622 "Vehicle Direction/Speed";
CM_ SG_ 2566842622 Altitude "Altitude of the vehicle referenced to sea level at standard atmospheric pressure and temperature.";
CM_ SG_ 2566842622 Pitch "Pitch (rotation about the y-axis) of the vehicle as calculated by the navigation device(s).  The pitch angle for an angle of ascent is reported with a positive value. This parameter is defined according to a Z-Down axis system and the sign of the ...";
CM_ SG_ 2566842622 NavigationBasedVehicleSpeed "Speed of the vehicle as calculated from a device such as a Global Positioning System (GPS).";
CM_ SG_ 2566842622 CompassBearing "Present compass bearing of vehicle.";
CM_ BO_ 2566832638 "High Resolution Vehicle Distance";
CM_ SG_ 2566832638 HighResolutionTripDistance "Distance traveled during all or part of a journey.

NOTE - See SPN 244 for alternate resolution.";
CM_ SG_ 2566832638 HghRsolutionTotalVehicleDistance "Accumulated distance traveled by the vehicle during its operation.

NOTE - See SPN 245 for alternate resolution.";
CM_ BO_ 2565868030 "Vehicle Dynamic Stability Control 2
Contains information which relates to the vehicle's movement.";
CM_ SG_ 2565868030 LongitudinalAcceleration "Indicates the longitudinal acceleration of the vehicle. A positive longitudinal acceleration signal results when the vehicle speed increases, regardless of driving the vehicle forward or backward.  This parameter is applicable to vehicle speed ...";
CM_ SG_ 2565868030 LateralAcceleration "Indicates a lateral acceleration of the vehicle (the component of vehicle acceleration vector along the Y-axis). A positive lateral acceleration signal results when the vehicle is accelerated to the left.  This parameter is defined according to a ...";
CM_ SG_ 2565868030 YawRate "Indicates the rate of rotation about the vertical axis (i.e. the z-axis).  A positive yaw rate signal results when the vehicle turns counter-clockwise.   This parameter is defined according to a Z-Up axis system and the sign of the value is in ...";
CM_ SG_ 2565868030 SteerWheelAngleSensorType "Indicates whether the steering wheel angle sensor is capable of absolute measuring of the number of steering wheel turns or not (relative measuring to position at ignition on).
00 Relative measuring principle
01 Absolute measuring principle
10 ...";
CM_ SG_ 2565868030 SteerWheelTurnCounter "Indicates number of steering wheel turns, absolute position or relative position at ignition on. Positive values indicate left turns.";
CM_ SG_ 2565868030 SteerWheelAngle "The main operator`s steering wheel angle (on the steering column, not the actual wheel angle).  The vehicle being steered to the left (counterclockwise) results in a positive steering wheel angle.  This is the yaw angle of the steering wheel with ...";
CM_ BO_ 2566803454 "Vehicle Dynamic Stability Control 1
Contains information which relates to the VDC system status.";
CM_ SG_ 2566803454 TrailerVDCActive "The trailer-VDC (Vehicle Dynamic Control) is an electronic vehicle stability function within the (semi) trailer braking system. It acts to stabilize the (semi) trailer during dynamic maneuvers. VDC includes Roll Over Prevention (ROP) and/or Yaw ...";
CM_ SG_ 2566803454 YCBrakeCtrlActive "State signal which indicates that Yaw Control (YC) has activated brake control. Active means that YC actually controls wheel brake pressure at one or more wheels of the vehicle or vehicle combination. Within the physical limits, YC attempts to ...";
CM_ SG_ 2566803454 YCEngCtrlActive "State Signal which indicates that the Yaw Control (YC) has commanded engine control to be active. Within the physical limits, YC attempts to prevent yawing of the vehicle. Active means that YC actually tries to control the engine. This state signal ...";
CM_ SG_ 2566803454 ROPBrakeCtrlActive "State signal which indicates that Roll over Prevention (ROP) has activated brake control. Active means that ROP actually controls wheel brake pressure at one or more wheels of the vehicle or vehicle combination. Within the physical limits, ROP ...";
CM_ SG_ 2566803454 ROPEngCtrlActive "State Signal which indicates that the Roll Over Prevention (ROP) has commanded engine control to be active. Within the physical limits, ROP attempts to prevent rolling over of the vehicle. Active means that ROP actually tries to control the engine ...";
CM_ SG_ 2566803454 VDCBrakeLightRq "Indicates whether VDC requests to turn the vehicle brake lights on

00 Turn brake light not on
01 Turn brake light on
10 Reserved
11 Don't care/Take no action";
CM_ SG_ 2566803454 VDCFullyOperational "Signal that indicates whether VDC is fully operational or whether its functionality is reduced by a permanent or temporary (e.g. low voltage) defect, by intended action (e.g. disabled by a switch or during special diagnostic procedures), not ...";
CM_ SG_ 2566803454 VDCInformationSignal "This parameter commands the VDC information signal, for example a dash lamp.

00 Off
01 On
10 Reserved
11 Don't care/Take no action";
CM_ BO_ 2566840574 "Vehicle Distance";
CM_ SG_ 2566840574 TotalVehicleDistance "Accumulated distance traveled by vehicle during its operation.

NOTE See SPN 917 for alternate resolution.";
CM_ SG_ 2566840574 TripDistance "Distance traveled during all or part of a journey.

NOTE See SPN 918 for alternate resolution.";
CM_ BO_ 2633938686 "Trip Vehicle Speed/Cruise Distance Information";
CM_ SG_ 2633938686 TripCruiseDistance "Total distance that the engine has operated in the cruise hold state, excluding time in accelerator override, since the last trip reset.";
CM_ SG_ 2633938686 TripMaxVehicleSpeed "Maximum vehicle speed achieved while the engine speed is greater than zero and the accelerator pedal position (APS) is at a value greater than 0%, since the last trip reset.";
CM_ BO_ 2633937150 "Trip Time Information 2";
CM_ SG_ 2633937150 TripAirCompressorOnTime "Total time that the air compressor is on and compressing air since the last trip reset.";
CM_ SG_ 2633937150 TripIdleTime "Total time accumulated while the engine speed is greater than zero, both the PTO and remote PTO governors are inactive, and the vehicle speed is less than 2 km/h, since the last trip reset.
In marine applications, this parameter is defined as the ...";
CM_ SG_ 2633937150 TripEngRunningTime "Total time accumulated while the engine speed is greater than zero since the last trip reset.  Note that time with the ignition switch on but engine speed at zero is not included.";
CM_ SG_ 2633937150 TripCruiseTime "Total time accumulated while the engine is in the cruise hold state, excluding time in accelerator override, since the last trip reset.";
CM_ SG_ 2633937150 TripPTOGovernorTime "Total time accumulated while the engine is in the PTO or remote PTO governor hold state since the last trip reset.";
CM_ BO_ 2633938174 "Trip Time Information 1";
CM_ SG_ 2633938174 TripTimeInDerateByEng "Total time accumulated when the engine final fueling has been derated due to an engine protection algorithm, since the last reset.";
CM_ SG_ 2633938174 TripTimeInGearDown "Total time accumulated when the vehicle has operated in one gear down from the top gear for a calibrated minimum time, since the last trip reset.";
CM_ SG_ 2633938174 TripTimeInTopGear "Total time accumulated when the vehicle has operated in top gear for a calibrated minimum time, since the last trip reset.";
CM_ SG_ 2633938174 TripTimeInVSL "Total time accumulated when the engine has operated on the vehicle speed limiter (VSL) while not in the cruise hold state, since the last trip reset.  The engine torque mode is equal to road speed governor during this operation.";
CM_ BO_ 2633938430 "Trip Shutdown Information";
CM_ SG_ 2633938430 TripSuddenDecelerations "Total number of decelerations whenever the vehicle deceleration is more than XYZ km/h/sec (where XYZ is a calibratible threshold), since the last trip reset.  A lengthy deceleration shall be counted as one sudden deceleration.";
CM_ SG_ 2633938430 TrpNumberOfIdleShutdownOverrides "Total number of times an operator disables idle shutdown to prevent an engine shutdown, since the last trip reset.";
CM_ SG_ 2633938430 TripNumberOfIdleShutdowns "Total number of times the engine has been shutdown due to idling too long (at normal idle or fast idle) since the last trip reset.";
CM_ SG_ 2633938430 TripNumberOfHotShutdowns "Total number of hot shutdowns since the last trip reset.  A hot shutdown is based on operation at high load or high engine speed or for long operating periods without allowing the engine to cool sufficiently.";
CM_ BO_ 2348875518 "Torque/Speed Control 1
NOTE - Retarder may be disabled by commanding a torque limit of 0%.  Use of the limit mode allows the use of the retarder only up to the limit specified in the request.  This can be used to permit retarding of up to 50%, for ...";
CM_ SG_ 2348875518 MessageChecksum "The message checksum is used to verify the signal path from the transmitting device to the receiving device.
The message checksum is calculated using the first 7 data bytes, the message counter and the bytes of the message identifier. It is ...";
CM_ SG_ 2348875518 MessageCounter "The message counter is used to detect situations where the transmitting ECU malfunction repeats the same frame all the time.  The receiver of the information may use the counter parameter to detect this situation.  The transmitting device will ...";
CM_ SG_ 2348875518 EngRequestedTorqueHighResolution "This parameter displays an additional torque in percent of the reference engine torque.
When the MSB is set to 1, this parameter is not available.  When the MSB is set to 0, bits 1 to 3 indicate the desired torque with resolution of 0.125%/bit  ...";
CM_ SG_ 2348875518 TSC1CtrlPurpose "State signal which indicates which control mode the sending device is using to generate the TSC1 command.  Note that the modes are not in prioritized order. Not all modes may be relevant for a given device. Some devices may not implement all ...";
CM_ SG_ 2348875518 TSC1TransRate "This parameter indicates the transmission rate at which the sending device will transmit the TSC1 message.  The engine shall adjust its timeout for TSC1 messages accordingly. Variable TSC1 transmission rates shall only apply to messages sent to the ...";
CM_ SG_ 2348875518 EngRequestedTorque_TorqueLimit "Parameter provided to the engine or retarder in the torque/speed control message for controlling or limiting the output torque.
Requested torque to the engine is measured in indicated torque as a percentage of reference engine torque (see the ...";
CM_ SG_ 2348875518 EngRequestedSpeed_SpeedLimit "Parameter provided to the engine from external sources in the torque/speed control message.  This is the engine speed which the engine is expected to operate at if the speed control mode is active or the engine speed which the engine is not expected ...";
CM_ SG_ 2348875518 OverrideCtrlModePriority "This field is used as an input to the engine or retarder to determine the priority of the Override Control Mode received in the Torque/Speed Control message (see PGN 0).  The default is 11 (Low priority).  It is not required to use the same priority ...";
CM_ SG_ 2348875518 EngRequestedSpeedCtrlConditions "This mode tells the engine control system the governor characteristics that are desired during speed control.  The four characteristics defined are:
00 Transient Optimized for driveline disengaged and non-lockup conditions
01 Stability Optimized ...";
CM_ SG_ 2348875518 EngOverrideCtrlMode "The override control mode defines which sort of command is used:
00b - Override disabled - Disable any existing control commanded by the source of this command.
01b - Speed control - Govern speed to the included 밺esired speed� value.
10b - ...";
CM_ BO_ 2566766846 "Passenger Counter
Used to notify the transit link devices of real-time boarding and exiting passengers or to indicate the total number of passengers on vehicle referenced to the last transit stop.
Also transmits information on the use status of ...";
CM_ SG_ 2566766846 TransitRunStatus "Status of the run switch for the vehicle.

00 - Off
01- On
10 - Error condition
11 - Not available";
CM_ SG_ 2566766846 VehicleUseStatus "Used to indicate the proper or unauthorized use of the vehicle. The administrative control device or any device issuing the vehicle use status PID should be sensitive to the run switch status (SPN 3046) and any other locally defined criteria for ...";
CM_ SG_ 2566766846 SilentAlarmStatus "Used to report silent alarm push button status.

00 - Off
01 - On
10 - Error condition
11 - Not available";
CM_ SG_ 2566766846 PatronCount "Count of the number of passengers on a transit vehicle.  If the type of passenger count (SPN 3043) is 0, the patron count indicates the number of patrons currently on vehicle after the door has closed.  If the type of passenger count is 1 to 4,
the ...";
CM_ SG_ 2566766846 TypeOfPassengerCount "Used to notify transit link devices of the type of passenger counting system used in the vehicle.  Some passenger counting systems indicate real-time boarding and exiting data for other devices to accumulate. Other types of passenger counters report ...";
CM_ BO_ 2566765310 "Farebox Status
Used to report alarms of the fare collection unit.";
CM_ SG_ 2566765310 FareboxAlarmIdentifier "Indicates the nature of the farebox alarm condition.
0000000 = Voltage dropout
0000001 = Voltage restored
0000010 = Probe started
0000011 = Probe completed
0000100 = Cashbox removed
0000101 = Cashbox restored
0000110 = Cashbox door timeout
 ...";
CM_ SG_ 2566765310 FareboxEmergencyStatus "Indicates if a farebox emergency condition exists.

00 = Non-emergency condition
01 = Emergency condition
10 = Error Condition
11 = Not available";
CM_ BO_ 2566765566 "Farebox Point of Sale
Used to report stop level point of sale detail.";
CM_ SG_ 2566765566 TransferSold "Indicates that a transfer was sold or issued on this transaction including its type and/or restrictions. The final definitions of the transfer issued information shall be agreed by the operating agency and the farebox manufacturer.
Note:  A ...";
CM_ SG_ 2566765566 TransferType "The kind of transfer used

00000 = North
00001 = South
00010 = East
00011 = West
00100 = In
00101 = Out
00110-11111 = Agency defined";
CM_ SG_ 2566765566 TypeOfService "The type of service provided

000 = Local service
001 = Express service
010-111 = Agency defined";
CM_ SG_ 2566765566 InitialFareAgency "Identifies where the initial fare is paid

Note:  The definition of the agency numbering plan shall be agreed by the operating agency and the farebox manufacturer.  The value of 0 is reserved, the usable range is 1 to 31.";
CM_ SG_ 2566765566 PassCategory "Agency defined value indicating the category of the passenger associated with this fare";
CM_ SG_ 2566765566 FareValidity "Agency defined value indicating validity of this fare";
CM_ SG_ 2566765566 PaymentDetails "Payment details.

0000 = Not an upgrade
0001 = Cash
0010 = Token
0011 = Ticket
0100 = Pass
0101 = Card
0110-1010 = Reserved for assignment
1011-1111 = Agency defined";
CM_ SG_ 2566765566 TypeOfFare "Type of Fare

0000 = Cash/No detail
0001 = Token A
0010 = Token B
0011 = Ticket A
0100 = Ticket B
0101 = Pass A
0110 = Pass B
0111-1010 = Reserved for assignment
1011-1111 = Agency defined";
CM_ SG_ 2566765566 PassengerType "Enumerated value representing the type/class of passenger, as defined by the agency.";
CM_ SG_ 2566765566 TransactionType "Enumerated value representing the type of transaction completed

0000 = Cash
0001 = Token
0010 = Ticket
0011 = Pass
0100 = Card
0101 = Permit
0110 = Transfer
0111 = Free
1000-1011 = Reserved for assignment
1100-1111 = Agency defined";
CM_ SG_ 2566765566 RouteNumber "The route number issuing the transfer.";
CM_ BO_ 2566765822 "Farebox Service Detail
Used to identify service, assignments, and fare preset detail of the fare collection unit.";
CM_ SG_ 2566765822 DriversFareboxSecurityCode "Security code for the farebox, numerical only.

Note:  0 = Farebox is in reporting status
           1 - 65535 = security code";
CM_ SG_ 2566765822 AssignedBlock "The agency defined block number for this trip";
CM_ SG_ 2566765822 AssignedRun "The agency defined run number for this trip";
CM_ SG_ 2566765822 AssignedRoute "The identity number assigned to this route.

Note:  This is the numerical value for the route as opposed to the \"Transit Assigned Route Identity\" (SPN 3074) which is variable length ASCII or the \"Route number\" (SPN 3169) which is 12 bit numeric.";
CM_ SG_ 2566765822 PatternNumber "The agency defined pattern number for this trip";
CM_ SG_ 2566765822 TripNumber "The identity number assigned to this trip.";
CM_ SG_ 2566765822 FarePresets "Fare Presets

00000000 to 00001111 = Agency defined
00010000 to 11111111 = Reserved for assignment";
CM_ SG_ 2566765822 TripDirection "The general direction of travel for this trip.

0000 = North
0001 = South
0010 = East
0011 = West
0100 = In
0101 = Out
0110-1111 = Agency defined";
CM_ SG_ 2566765822 TripStatus "Trip Status

000 = Undefined
001 = Trip start
010 = Trip end
011 = Undefined
100 = Undefined
101 = Layover start
110 = Layover end
111 = Undefined";
CM_ SG_ 2566765822 FareboxServiceStatus "Indicates if the farebox is in or out of service.

00 = Farebox out of service
01 = Farebox in service
10 = Error Condition
11 = Not available";
CM_ BO_ 2566766078 "Signal Preemption
Status and configuration of the device used for intersection preemption.";
CM_ SG_ 2566766078 VehicleID "Numerical designation of the vehicle.   65535 is used to represent the vehicle ID is not available.";
CM_ SG_ 2566766078 StrobeActivationCtrlStatus "Strobe activation control status

00 - Deactivate strobe
01 - Activate strobe
10 - Error condition
11 - Not available

Note: Strobe will flash if not overridden by transit door status, strobe is working, and emitter is in the normal mode.";
CM_ SG_ 2566766078 TransitDoorEnable "Transit door enable

00 - Ignore transit door status
01 - Transit door status will override strobe activation
10 - Error condition
11 - Not available";
CM_ SG_ 2566766078 PriorityOfRespSentByEmitter "Priority of response sent by emitter
0000               - Reserved
0001               - Low priority
0010               - Probe priority
0011               - High priority
0100 to 1000 - Reserved
1001               - Priority set by hardware ...";
CM_ SG_ 2566766078 IntrsctnPrmptionRequest_Response "Status of the intersection signal preemption

00 - Message is a request directed to the emitter
01 - Message is a response from the emitter
10 - Error condition
11 - Not available";
CM_ SG_ 2566766078 TransitRouteIDUsage "Transit route ID usage

00 - Transit route ID not used for interleaved data
01 - Transit route ID used for interleaved data (if range code not enabled)
10 - Error condition
11 - Not available";
CM_ SG_ 2566766078 RangeCodeEnable "Range code enable

00 - Range code not used for interleaved data
01 - Range code used for interleaved data
10 - Error condition
11 - Not available";
CM_ BO_ 2566766590 "Transit Milepost
Identification of a transit route milepost";
CM_ SG_ 2566766590 NmbrOfBytsInThMlpstIdntification "Number of bytes in the Milepost Identification.  This parameter identifies the length, in bytes, of the data in SPN 509 (Milepost Identification).";
CM_ BO_ 2566766334 "Transit Route
The current route assigned to this transit vehicle. The transit route information may be entered into different devices by different authorities (fare collection, radio log, unit control panel, etc.).";
CM_ SG_ 2566766334 NmbrOfBytsInThTrnstAssgndBlckIdn "Number of bytes in the Transit Assigned Block Identity.  This parameter identifies the length, in bytes, of the data in SPN 3076 (Transit Assigned Block Identity).";
CM_ SG_ 2566766334 NmbrOfBytsInThTrnstAssgndRnIdntt "Number of bytes in the Transit Assigned Run Identity.  This parameter identifies the length, in bytes, of the data in SPN 3075 (Transit Assigned Run Identity).";
CM_ SG_ 2566766334 NmbrOfBytsInThTrnstAssgndRtIdntt "Number of bytes in the Transit Assigned Route Identity.  This parameter identifies the length, in bytes, of the data in SPN 3074 (Transit Assigned Route Identity).";
CM_ SG_ 2566766334 Agency "The identity of the agency involved in this transaction";
CM_ BO_ 2561605374 "Tire Pressure Reference Setting
For setting the tire pressure reference values.

This message is the setpoint for the PGN 64953 Tire Pressure reference information message.";
CM_ SG_ 2561605374 TireLocation "Identifies which tire is associated with the parametric data in this PGN.
The low order 4 bits represent a position number, counting left to right when facing in the direction of normal vehicle travel (forward).
The high order 4 bits represent a ...";
CM_ BO_ 2566765054 "Tire Pressure Reference Information
Information on actual tire pressure reference value for monitoring.
NOTE뻄essage has to repeated as necessary to transmit all available information.  This method of location identification requires individual ...";
CM_ SG_ 2566765054 TireLocation "Identifies which tire is associated with the parametric data in this PGN.
The low order 4 bits represent a position number, counting left to right when facing in the direction of normal vehicle travel (forward).
The high order 4 bits represent a ...";
CM_ BO_ 2633923326 "Tire Pressure Control Unit Current Pressures";
CM_ SG_ 2633923326 SteerChannelTirePress "The latest gage pressure reading of the steer group of tires, as opposed to the pressure in each tire.";
CM_ SG_ 2633923326 DriveChannelTirePress "The latest gage pressure reading of the drive group of tires, as opposed to the pressure in each tire.";
CM_ SG_ 2633923326 TrailerTagOrPushChannelTirePress "The latest gage pressure reading of the trailer, tag, or push group of tires, as opposed to the pressure in each tire.";
CM_ BO_ 2633923070 "Tire Pressure Control Unit Target Pressures";
CM_ SG_ 2633923070 SteerChannelTirePressTarget "The tire pressure control system뭩 target gage pressure for the steer group of tires.";
CM_ SG_ 2633923070 DriveChannelTirePressTarget "The tire pressure control system뭩 target gage pressure for the drive group of tires.";
CM_ SG_ 2633923070 TrlrTgOrPshChnnelTirePressTarget "The tire pressure control system뭩 target gage pressure for the trailer, tag, or push group of tires.";
CM_ BO_ 2633922814 "Tire Pressure Control Unit Mode and Status";
CM_ SG_ 2633922814 PCUTrilerTagOrPushSolenoidStatus "Current state of the trailer, tag, or push solenoid used to implement a tire pressure control system in its pneumatic control unit (PCU).

00 - Off
01 - On
10 - Error
11 - Not available";
CM_ SG_ 2633922814 PCUSupplySolenoidStatus "Current state of the supply solenoid used to implement a tire pressure control system in its pneumatic control unit (PCU).

00 - Off
01 - On
10 - Error
11 - Not available";
CM_ SG_ 2633922814 PCUCtrlSolenoidStatus "Current state of the control solenoid used to implement a tire pressure control system in its pneumatic control unit (PCU).

00 - Off
01 - On
10 - Error
11 - Not available";
CM_ SG_ 2633922814 PCUDeflateSolenoidStatus "Current state of the deflate solenoid used to implement a tire pressure control system in its pneumatic control unit (PCU).

00 - Off
01 - On
10 - Error
11 - Not available";
CM_ SG_ 2633922814 TirePressSupplySwitchStatus "Current state of an open/closed type switch used to determine if adequate pressure exists for system implementation.

00 - Off
01 - On
10 - Error
11 - Not available";
CM_ SG_ 2633922814 PCUSteerSolenoidStatus "Current state of the steer solenoid used to implement a tire pressure control system in its pneumatic control unit (PCU).

00 - Off
01 - On
10 - Error
11 - Not available";
CM_ SG_ 2633922814 PCUDriveSolenoidStatus "Current state of the drive solenoid used to implement a tire pressure control system in its pneumatic control unit (PCU).

00 - Off
01 - On
10 - Error
11 - Not available";
CM_ SG_ 2633922814 DriveChannelMode "Indicates the functional mode of trailer/tag channel of the tire pressure control system.
0000 Maintain
0001 Inflate
0010 Deflate
0011 Confirm
0100 Inflate Wait - System will inflate when conditions allow
0101 Deflate Wait - System will ...";
CM_ SG_ 2633922814 Trailer_tagChannelMode "Indicates the functional mode of trailer/tag channel of the tire pressure control system.
0000 Maintain
0001 Inflate
0010 Deflate
0011 Confirm
0100 Inflate Wait - System will inflate when conditions allow
0101 Deflate Wait - System will ...";
CM_ SG_ 2633922814 SteerChannelMode "Indicates the functional mode of steer channel of the tire pressure control system.
0000 Maintain
0001 Inflate
0010 Deflate
0011 Confirm
0100 Inflate Wait - System will inflate when conditions allow
0101 Deflate Wait - System will deflate when ...";
CM_ SG_ 2633922814 TirePressCheckInterval "The interval at which the system will check the tire pressures (e.g., 5, 10, 15 min.).

NOTE - A value of 0 indicates continuous (real time) pressure readings.";
CM_ BO_ 2566845694 "Tire Condition Message 1
Tire Condition Message
NOTE � Multiple instances of this message will be required to transmit data for all tire locations.  When reporting data for multiple tire locations, each successive message, which provides data for ...";
CM_ SG_ 2566845694 ExTirePressSupport "Defines the choice of using the tire pressure (PGN 65268) or Extended Tire Pressure (PGN 64578). The state value '01' indicates the extended tire pressure SPN is used for the pressure data. Any other value indicates the extended tire pressure SPN is ...";
CM_ SG_ 2566845694 TirePressThresholdDetection_13 "Signal indicating the pressure level of the tire.";
CM_ SG_ 2566845694 TirePressThresholdDetection_12 "Signal indicating the pressure level of the tire.";
CM_ SG_ 2566845694 TirePressThresholdDetection_11 "Signal indicating the pressure level of the tire.";
CM_ SG_ 2566845694 TirePressThresholdDetection_10 "Signal indicating the pressure level of the tire.";
CM_ SG_ 2566845694 TirePressThresholdDetection_01 "Signal indicating the pressure level of the tire.";
CM_ SG_ 2566845694 TirePress_33 "Pressure at which air is contained in cavity formed by tire and rim.";
CM_ SG_ 2566845694 TirePress_32 "Pressure at which air is contained in cavity formed by tire and rim.";
CM_ SG_ 2566845694 TirePress_31 "Pressure at which air is contained in cavity formed by tire and rim.";
CM_ SG_ 2566845694 TirePress_30 "Pressure at which air is contained in cavity formed by tire and rim.";
CM_ SG_ 2566845694 TirePress_23 "Pressure at which air is contained in cavity formed by tire and rim.";
CM_ SG_ 2566845694 TirePress_22 "Pressure at which air is contained in cavity formed by tire and rim.";
CM_ SG_ 2566845694 TirePress_21 "Pressure at which air is contained in cavity formed by tire and rim.";
CM_ SG_ 2566845694 TirePress_20 "Pressure at which air is contained in cavity formed by tire and rim.";
CM_ SG_ 2566845694 TirePress_13 "Pressure at which air is contained in cavity formed by tire and rim.";
CM_ SG_ 2566845694 TirePress_12 "Pressure at which air is contained in cavity formed by tire and rim.";
CM_ SG_ 2566845694 TirePress_11 "Pressure at which air is contained in cavity formed by tire and rim.";
CM_ SG_ 2566845694 TirePress_10 "Pressure at which air is contained in cavity formed by tire and rim.";
CM_ SG_ 2566845694 TireAirLeakageRate_33 "The pressure loss rate of a tire.";
CM_ SG_ 2566845694 TireAirLeakageRate_32 "The pressure loss rate of a tire.";
CM_ SG_ 2566845694 TireAirLeakageRate_31 "The pressure loss rate of a tire.";
CM_ SG_ 2566845694 TireAirLeakageRate_30 "The pressure loss rate of a tire.";
CM_ SG_ 2566845694 TireAirLeakageRate_23 "The pressure loss rate of a tire.";
CM_ SG_ 2566845694 TireAirLeakageRate_22 "The pressure loss rate of a tire.";
CM_ SG_ 2566845694 TireAirLeakageRate_21 "The pressure loss rate of a tire.";
CM_ SG_ 2566845694 TireAirLeakageRate_20 "The pressure loss rate of a tire.";
CM_ SG_ 2566845694 TireAirLeakageRate_13 "The pressure loss rate of a tire.";
CM_ SG_ 2566845694 TireAirLeakageRate_12 "The pressure loss rate of a tire.";
CM_ SG_ 2566845694 TireAirLeakageRate_11 "The pressure loss rate of a tire.";
CM_ SG_ 2566845694 TireAirLeakageRate_10 "The pressure loss rate of a tire.";
CM_ SG_ 2566845694 TireAirLeakageRate_01 "The pressure loss rate of a tire.";
CM_ SG_ 2566845694 TireAirLeakageRate_00 "The pressure loss rate of a tire.";
CM_ SG_ 2566845694 CTIWheelSensorStatus_33 "Indicates whether the wheel is being monitored by the CTI controller.";
CM_ SG_ 2566845694 CTIWheelSensorStatus_32 "Indicates whether the wheel is being monitored by the CTI controller.";
CM_ SG_ 2566845694 CTIWheelSensorStatus_31 "Indicates whether the wheel is being monitored by the CTI controller.";
CM_ SG_ 2566845694 CTIWheelSensorStatus_30 "Indicates whether the wheel is being monitored by the CTI controller.";
CM_ SG_ 2566845694 CTIWheelSensorStatus_23 "Indicates whether the wheel is being monitored by the CTI controller.";
CM_ SG_ 2566845694 CTIWheelSensorStatus_22 "Indicates whether the wheel is being monitored by the CTI controller.";
CM_ SG_ 2566845694 CTIWheelSensorStatus_21 "Indicates whether the wheel is being monitored by the CTI controller.";
CM_ SG_ 2566845694 CTIWheelSensorStatus_20 "Indicates whether the wheel is being monitored by the CTI controller.";
CM_ SG_ 2566845694 CTIWheelSensorStatus_13 "Indicates whether the wheel is being monitored by the CTI controller.";
CM_ SG_ 2566845694 CTIWheelSensorStatus_12 "Indicates whether the wheel is being monitored by the CTI controller.";
CM_ SG_ 2566845694 CTIWheelSensorStatus_11 "Indicates whether the wheel is being monitored by the CTI controller.";
CM_ SG_ 2566845694 CTIWheelSensorStatus_10 "Indicates whether the wheel is being monitored by the CTI controller.";
CM_ SG_ 2566845694 CTIWheelSensorStatus_01 "Indicates whether the wheel is being monitored by the CTI controller.";
CM_ SG_ 2566845694 CTIWheelEndElectricalFault_33 "Indicates the status of electrical fault on CTI wheel interface.";
CM_ SG_ 2566845694 CTIWheelEndElectricalFault_32 "Indicates the status of electrical fault on CTI wheel interface.";
CM_ SG_ 2566845694 CTIWheelEndElectricalFault_31 "Indicates the status of electrical fault on CTI wheel interface.";
CM_ SG_ 2566845694 CTIWheelEndElectricalFault_30 "Indicates the status of electrical fault on CTI wheel interface.";
CM_ SG_ 2566845694 CTIWheelEndElectricalFault_23 "Indicates the status of electrical fault on CTI wheel interface.";
CM_ SG_ 2566845694 CTIWheelEndElectricalFault_22 "Indicates the status of electrical fault on CTI wheel interface.";
CM_ SG_ 2566845694 CTIWheelEndElectricalFault_21 "Indicates the status of electrical fault on CTI wheel interface.";
CM_ SG_ 2566845694 CTIWheelEndElectricalFault_20 "Indicates the status of electrical fault on CTI wheel interface.";
CM_ SG_ 2566845694 CTIWheelEndElectricalFault_13 "Indicates the status of electrical fault on CTI wheel interface.";
CM_ SG_ 2566845694 CTIWheelEndElectricalFault_12 "Indicates the status of electrical fault on CTI wheel interface.";
CM_ SG_ 2566845694 CTIWheelEndElectricalFault_11 "Indicates the status of electrical fault on CTI wheel interface.";
CM_ SG_ 2566845694 CTIWheelEndElectricalFault_10 "Indicates the status of electrical fault on CTI wheel interface.";
CM_ SG_ 2566845694 CTIWheelEndElectricalFault_01 "Indicates the status of electrical fault on CTI wheel interface.";
CM_ SG_ 2566845694 CTITireStatus_33 "Indicates the status of the tire.";
CM_ SG_ 2566845694 CTITireStatus_32 "Indicates the status of the tire.";
CM_ SG_ 2566845694 CTITireStatus_31 "Indicates the status of the tire.";
CM_ SG_ 2566845694 CTITireStatus_30 "Indicates the status of the tire.";
CM_ SG_ 2566845694 CTITireStatus_23 "Indicates the status of the tire.";
CM_ SG_ 2566845694 CTITireStatus_22 "Indicates the status of the tire.";
CM_ SG_ 2566845694 CTITireStatus_21 "Indicates the status of the tire.";
CM_ SG_ 2566845694 CTITireStatus_20 "Indicates the status of the tire.";
CM_ SG_ 2566845694 CTITireStatus_13 "Indicates the status of the tire.";
CM_ SG_ 2566845694 CTITireStatus_12 "Indicates the status of the tire.";
CM_ SG_ 2566845694 CTITireStatus_11 "Indicates the status of the tire.";
CM_ SG_ 2566845694 CTITireStatus_10 "Indicates the status of the tire.";
CM_ SG_ 2566845694 CTITireStatus_01 "Indicates the status of the tire.";
CM_ SG_ 2566845694 TireTemp_11 "Temperature at the surface of the tire sidewall.";
CM_ SG_ 2566845694 TireTemp_33 "Temperature at the surface of the tire sidewall.";
CM_ SG_ 2566845694 TireTemp_32 "Temperature at the surface of the tire sidewall.";
CM_ SG_ 2566845694 TireTemp_31 "Temperature at the surface of the tire sidewall.";
CM_ SG_ 2566845694 TireTemp_30 "Temperature at the surface of the tire sidewall.";
CM_ SG_ 2566845694 TireTemp_23 "Temperature at the surface of the tire sidewall.";
CM_ SG_ 2566845694 TireTemp_22 "Temperature at the surface of the tire sidewall.";
CM_ SG_ 2566845694 TireTemp_21 "Temperature at the surface of the tire sidewall.";
CM_ SG_ 2566845694 TireTemp_20 "Temperature at the surface of the tire sidewall.";
CM_ SG_ 2566845694 TireTemp_13 "Temperature at the surface of the tire sidewall.";
CM_ SG_ 2566845694 TireTemp_12 "Temperature at the surface of the tire sidewall.";
CM_ SG_ 2566845694 TireTemp_10 "Temperature at the surface of the tire sidewall.";
CM_ SG_ 2566845694 TireTemp_01 "Temperature at the surface of the tire sidewall.";
CM_ SG_ 2566845694 TireTemp_00 "Temperature at the surface of the tire sidewall.";
CM_ SG_ 2566845694 TirePressThresholdDetection_33 "Signal indicating the pressure level of the tire.";
CM_ SG_ 2566845694 TirePressThresholdDetection_32 "Signal indicating the pressure level of the tire.";
CM_ SG_ 2566845694 TirePressThresholdDetection_31 "Signal indicating the pressure level of the tire.";
CM_ SG_ 2566845694 TirePressThresholdDetection_30 "Signal indicating the pressure level of the tire.";
CM_ SG_ 2566845694 TirePressThresholdDetection_23 "Signal indicating the pressure level of the tire.";
CM_ SG_ 2566845694 TirePressThresholdDetection_22 "Signal indicating the pressure level of the tire.";
CM_ SG_ 2566845694 TirePressThresholdDetection_21 "Signal indicating the pressure level of the tire.";
CM_ SG_ 2566845694 TirePressThresholdDetection_20 "Signal indicating the pressure level of the tire.";
CM_ SG_ 2566845694 TirePressThresholdDetection_00 "Signal indicating the pressure level of the tire.";
CM_ SG_ 2566845694 TirePress_01 "Pressure at which air is contained in cavity formed by tire and rim.";
CM_ SG_ 2566845694 TirePress_00 "Pressure at which air is contained in cavity formed by tire and rim.";
CM_ SG_ 2566845694 CTIWheelSensorStatus_00 "Indicates whether the wheel is being monitored by the CTI controller.";
CM_ SG_ 2566845694 CTIWheelEndElectricalFault_00 "Indicates the status of electrical fault on CTI wheel interface.";
CM_ SG_ 2566845694 CTITireStatus_00 "Indicates the status of the tire.";
CM_ SG_ 2566845694 TireLocation "Identifies which tire is associated with the parametric data in this PGN.
The low order 4 bits represent a position number, counting left to right when facing in the direction of normal vehicle travel (forward).
The high order 4 bits represent a ...";
CM_ BO_ 2633939966 "Trip Fan Information";
CM_ SG_ 2633939966 TripFanOnTimeDueToTheA_CSystem "Total time the fan has been on due to the A/C system since the last trip reset.  For the time to be accumulated against the A/C system, it is necessary that it be the first to request the fan activation or it be the only system requesting fan ...";
CM_ SG_ 2633939966 TripFanOnTimeDueToAManualSwitch "Total time the fan has been on due to manual activation by the operator (i.e., excluding time on due to automatic triggers) since the last trip reset.  For the time to be accumulated against the manual switch, it is necessary that it be the first to ...";
CM_ SG_ 2633939966 TripFanOnTimeDueToTheEngSystem "Total time the fan has been on due to engine triggers (i.e., excluding time on due to an operator manual switch or A/C system) since the last trip reset.  For the time to be accumulated against the engine system, it is necessary that it be the first ...";
CM_ SG_ 2633939966 TripFanOnTime "Total time the fan has been on (due to an automatic trigger or manual trigger) since the last trip reset.  The fan could be requested to be on by the engine system, a manual switch, and/or the A/C system.  Whichever system requests the fan ...";
CM_ BO_ 2633939710 "Trip Distance Information";
CM_ SG_ 2633939710 TripDistanceInTopGear "Total distance accumulated while the vehicle has operated in top gear for a calibrated minimum time since the last trip reset.";
CM_ SG_ 2633939710 TripGearDownDistance "Total distance accumulated while the vehicle has operated in the gear which is one gear down from top gear and exceeds a calibrated minimum time (typically the time to shift the transmission) since the last trip reset.";
CM_ SG_ 2633939710 TripDistanceOnVSL "Total distance accumulated while the engine torque mode is road speed governing since the last trip reset.";
CM_ BO_ 2564161278 "Time/Date Adjust";
CM_ SG_ 2564161278 AdjustLocalHourOffset "The hour component for setting the offset between the UTC (Universal Time Coordinate) time and date and a the local time zone time and date.  This is the number of minutes to add to UTC, a.k.a. GMT, time and date to convert to the time and date in ...";
CM_ SG_ 2564161278 AdjustLocalMinuteOffset "The minute component for setting the offset between the UTC (Universal Time Coordinate) time and date and a the local time zone time and date.  This is the number of minutes to add to UTC, a.k.a. GMT, time and date to convert to the time and date in ...";
CM_ SG_ 2564161278 AdjustYear "The year component for setting the current calendar date.  This should be reported as the year component of the current date according to the calendar date standard indicated with the Local Hour Offset parameter (SPN 1602).  The calendar date should ...";
CM_ SG_ 2564161278 AdjustDay "The day component for setting the current calendar date.  This should be reported as the day component of the current date according to the calendar date standard indicated with the Local Hour Offset parameter (SPN 1602).  The calendar date should ...";
CM_ SG_ 2564161278 AdjustMonth "The month component for setting the current calendar date.  This should be reported as the month component of the current date according to the calendar date standard indicated with the Local Hour Offset parameter (SPN 1602).  The calendar date ...";
CM_ SG_ 2564161278 AdjustHours "The hours component for setting the current time of day.  This should be reported as the hours component of the current time according to the time of day standard indicated with the Local Hour Offset parameter (SPN 1602).  The time of day should be ...";
CM_ SG_ 2564161278 AdjustMinutes "The minutes component for setting the current time of day.  This should be reported as the minutes component of the current time according to the time of day standard indicated with the Local Hour Offset parameter (SPN 1602).  The time of day should ...";
CM_ SG_ 2564161278 AdjustSeconds "The seconds component for setting the current time of day.  This should be reported as the seconds component of the current time according to the time of day standard indicated with the Local Hour Offset parameter (SPN 1602).  The time of day should ...";
CM_ BO_ 2566842110 "Time/Date";
CM_ SG_ 2566842110 LocalHourOffset "The hour component of the offset between the UTC (Universal Time Coordinate) time and date and a local time zone time and date.  This is the number of hours to add to UTC, a.k.a. GMT, time and date to convert to the time and date in the local time ...";
CM_ SG_ 2566842110 LocalMinuteOffset "The minute component of the offset between the UTC time and date and a local time zone time and date.  This is the number of minutes to add to UTC (Universal Time Coordinate) time and date to convert to the time and date in the local time zone  ...";
CM_ SG_ 2566842110 Year "The year component of the current calendar date.  This should be reported as the year component of the current date at UTC (Universal Time Coordinate), a.k.a. GMT; however, it may be reported as the year component of the current date at a local time ...";
CM_ SG_ 2566842110 Day "The day component of the current calendar date.  This should be reported as the day component of the current date at UTC (Universal Time Coordinate), a.k.a. GMT; however, it may be reported as the day component of the current date at a local time ...";
CM_ SG_ 2566842110 Month "The month component of the current calendar date.  This should be reported as the month component of the current date at UTC (Universal Time Coordinate), a.k.a. GMT; however, it may be reported as the month component of the current date at a local ...";
CM_ SG_ 2566842110 Hours "The hour component of the current time of day.  This should be reported as the hour component of the current time at UTC (Universal Time Coordinate), a.k.a. GMT; however, it may be reported as the hour component of the current time at a local time ...";
CM_ SG_ 2566842110 Minutes "The minutes component of the current time of day.  This should be reported as the minutes component of the current time at UTC (Universal Time Coordinate), a.k.a. GMT; however, it may be reported as the minutes component of the current time at a ...";
CM_ SG_ 2566842110 Seconds "The seconds component of the current time of day.  This should be reported as the seconds component of the current time at UTC (Universal Time Coordinate), a.k.a. GMT; however, it may be reported as the seconds component of the current time at a ...";
CM_ BO_ 2566821630 "Turbocharger Wastegate";
CM_ SG_ 2566821630 EngDsrdTrboWastegateActuator2Pos "The Requested Valve position of the Turbocharger Wastegate Valve 2, commanded by the engine ECU. A value of 0% represents fully closed and a value of 100% represents fully open.

This is the position that the device is attempting to achieve.";
CM_ SG_ 2566821630 EngTrbWstgateActuator1TempStatus "Used to identify the status of the Engine Turbocharger Wastegate Actuator 1 drive circuitry temperature.  Temperature excursions may affect the torque output.
000 - High Most severe
001 - High Least severe
010 - In Range
011 - Low Least severe
 ...";
CM_ SG_ 2566821630 EngTrbWstgtActtor1PreliminaryFMI "Used to identify the applicable J1939-73 FMI detected in the Engine Turbocharger Wastegate Actuator 1 by the manufacturers software.  When there is multiple failures, the most severe is transmitted
A value of 31 is sent to indicate that no failure ...";
CM_ SG_ 2566821630 EngDsrdTrboWastegateActuator1Pos "The Requested Valve position of the Turbocharger Wastegate Valve 1, commanded by the engine ECU. A value of 0% represents fully closed and a value of 100% represents fully open.

This is the position that the device is attempting to achieve.";
CM_ SG_ 2566821630 EngTrbWstgteActuatorCtrlAirPress "Gage pressure of the air used to control the actuator which opens and closes the wastegate valve.";
CM_ SG_ 2566821630 EngTurboWastegateActuator4Pos "Position of the wastegate drive.  A value of 0% represents fully closed and a value of 100% represents fully open.";
CM_ SG_ 2566821630 EngTurboWastegateActuator3Pos "Position of the wastegate drive.  A value of 0% represents fully closed and a value of 100% represents fully open.";
CM_ SG_ 2566821630 EngTurboWastegateActuator2Pos "Position of the wastegate drive.  A value of 0% represents fully closed and a value of 100% represents fully open.";
CM_ SG_ 2566821630 EngTurboWastegateActuator1Pos "Position of the wastegate drive.  A value of 0% represents fully closed and a value of 100% represents fully open.";
CM_ BO_ 2365484286 "Tachograph";
CM_ SG_ 2365484286 TachographVehicleSpeed "Speed of the vehicle registered by the tachograph.";
CM_ SG_ 2365484286 TachographOutputShaftSpeed "Calculated speed of the transmission output shaft.";
CM_ SG_ 2365484286 DirectionIndicator "Indicates the direction of the vehicle.

00 - Forward
01 - Reverse
10 - Error
11 - Not available";
CM_ SG_ 2365484286 TachographPerformance "Indicates the tachograph performance; including electronic or mechanical analysis, instrument analysis, speed sensor analysis, mass storage analysis, and printer analysis.
00 - Normal performance
01 - Performance analysis
10 - Error
11 - Not ...";
CM_ SG_ 2365484286 HandlingInformation "Indicates that handling information is present.  Information could include 뱊o printer paper�, 뱊o driver card�, etc.

00 - No handling information
01 - Handling information
10 - Error
11 - Not available";
CM_ SG_ 2365484286 SystemEvent "Indicates that a tachograph event has occurred.  This may include power supply interruption, interruption of the speed sensor, incorrect data on the driver card, driving without a driver card, illegal removal of a driver card, insertion of a driver ...";
CM_ SG_ 2365484286 DriverCardDriver2 "Indicates the presence of a driver card

00 - Driver card not present
01 - Driver card present
10 - Error
11 - Not available";
CM_ SG_ 2365484286 Driver2TimeRelatedStates "Indicates if the driver approaches or exceeds working time limits (or other limits).
0000 Normal/No limits reached
0001 Limit #1 - 15 min before 4 � h
0010 Limit #2 - 4 � h reached
0011 Limit #3 - 15 min before 9 h
0100 Limit #4 - 9 h reached
 ...";
CM_ SG_ 2365484286 VehicleOverspeed "Indicates whether the vehicle is exceeding the legal speed limit set in the tachograph.

00 No overspeed
01 Overspeed
10 Error
11 Not available";
CM_ SG_ 2365484286 DriverCardDriver1 "Indicates the presence of a driver card

00 - Driver card not present
01 - Driver card present
10 - Error
11 - Not available";
CM_ SG_ 2365484286 Driver1TimeRelatedStates "Indicates if the driver approaches or exceeds working time limits (or other limits).
0000 Normal/No limits reached
0001 Limit #1 - 15 min before 4 � h
0010 Limit #2 - 4 � h reached
0011 Limit #3 - 15 min before 9 h
0100 Limit #4 - 9 h reached
 ...";
CM_ SG_ 2365484286 VehicleMotion "Indicates whether motion of the vehicle is detected or not.

00 Vehicle motion not detected
01 Vehicle motion detected
10 - Error
11 - Not available";
CM_ SG_ 2365484286 Driver2WorkingState "State of work of the driver.  

000 Rest - sleeping
001 Driver available - short break
010 Work - loading, unloading, working in an office
011 Drive - behind wheel 
100-101 Reserved
110 Error
111 Not available";
CM_ SG_ 2365484286 Driver1WorkingState "State of work of the driver.  

000 Rest - sleeping
001 Driver available - short break
010 Work - loading, unloading, working in an office
011 Drive - behind wheel 
100-101 Reserved
110 Error
111 Not available";
CM_ BO_ 2566771710 "Turbocharger Information 6";
CM_ SG_ 2566771710 EngTurbo4CompressorOutletTemp "Temperature of the air or air/fuel mixture exiting the turbocharger 4 compressor outlet.";
CM_ SG_ 2566771710 EngTurbo3CompressorOutletTemp "Temperature of the air or air/fuel mixture exiting the turbocharger 3 compressor outlet.";
CM_ SG_ 2566771710 EngTurbo2CompressorOutletTemp "Temperature of the air or air/fuel mixture exiting the turbocharger 2 compressor outlet.";
CM_ SG_ 2566771710 EngTurbo1CompressorOutletTemp "Temperature of the air or air/fuel mixture exiting the turbocharger 1 compressor outlet";
CM_ BO_ 2566821886 "Turbocharger Information 5";
CM_ SG_ 2566821886 EngTurbo4TurbineOutletTemp "Temperature of the combustion by-products exiting the turbine side of the turbocharger.";
CM_ SG_ 2566821886 EngTurbo3TurbineOutletTemp "Temperature of the combustion by-products exiting the turbine side of the turbocharger.";
CM_ SG_ 2566821886 EngTurbo2TurbineOutletTemp "Temperature of the combustion by-products exiting the turbine side of the turbocharger.";
CM_ SG_ 2566821886 EngTurbo1TurbineOutletTemp "Temperature of the combustion by-products exiting the turbine side of the turbocharger.";
CM_ BO_ 2566822142 "Turbocharger Information 4";
CM_ SG_ 2566822142 EngTurbo4TurbineIntakeTemp "Temperature of the combustion by-products entering the turbine side of the turbocharger.";
CM_ SG_ 2566822142 EngTurbo3TurbineIntakeTemp "Temperature of the combustion by-products entering the turbine side of the turbocharger.";
CM_ SG_ 2566822142 EngTurbo2TurbineIntakeTemp "Temperature of the combustion by-products entering the turbine side of the turbocharger.";
CM_ SG_ 2566822142 EngTurbo1TurbineIntakeTemp "Temperature of the combustion by-products entering the turbine side of the turbocharger.";
CM_ BO_ 2566822398 "Turbocharger Information 3";
CM_ SG_ 2566822398 EngTurbo4CompressorIntakePress "Gage pressure of the air entering the compressor side of the turbocharger.";
CM_ SG_ 2566822398 EngTurbo3CompressorIntakePress "Gage pressure of the air entering the compressor side of the turbocharger.";
CM_ SG_ 2566822398 EngTurbo2CompressorIntakePress "Gage pressure of the air entering the compressor side of the turbocharger.";
CM_ SG_ 2566822398 EngTurbo1CompressorIntakePress "Gage pressure of the air entering the compressor side of the turbocharger.";
CM_ BO_ 2566822654 "Turbocharger Information 2";
CM_ SG_ 2566822654 EngTurbo4CompressorIntakeTemp "Temperature of the air entering the compressor side of the turbocharger.";
CM_ SG_ 2566822654 EngTurbo3CompressorIntakeTemp "Temperature of the air entering the compressor side of the turbocharger.";
CM_ SG_ 2566822654 EngTurbo2CompressorIntakeTemp "Temperature of the air entering the compressor side of the turbocharger.";
CM_ SG_ 2566822654 EngTurbo1CompressorIntakeTemp "Temperature of the air entering the compressor side of the turbocharger.";
CM_ BO_ 2633931774 "Turbocharger Information 1";
CM_ SG_ 2633931774 EngTurbo4Speed "Rotational velocity of rotor in the turbocharger.";
CM_ SG_ 2633931774 EngTurbo3Speed "Rotational velocity of rotor in the turbocharger.";
CM_ SG_ 2633931774 EngTurbo2Speed "Rotational velocity of rotor in the turbocharger.";
CM_ SG_ 2633931774 EngTurboLubeOilPress2 "Gage pressure of oil in turbocharger lubrication system.";
CM_ BO_ 2566802430 "Transmission Configuration 2
Contains transmission configuration information.";
CM_ SG_ 2566802430 CommunicationsFailureIdleTrqLmt "This parameter is provided to the engine from the transmission as an idle governor torque limit to be invoked by the engine in the event that CAN communication with the transmission is lost.
The data is transmitted in indicated torque as a percent ...";
CM_ SG_ 2566802430 ReferenceTrq "This parameter is the 100% reference value for all defined transmission output torque parameters.  For a given vehicle application, it is only defined once and doesn't change.";
CM_ SG_ 2566802430 TransTorqueLimit "Parameter provided to the engine from the transmission as a torque limit to be invoked by the engine in the event that J1939 communication with the transmission is lost.
The intention is to protect transmissions that use a continuous torque limit ...";
CM_ BO_ 2566841086 "Transmission Configuration
Total message length depends on total number of forward and reverse gear ratios.
NOTE:  The first gear ratio transmitted in bytes 3,4 will be the highest reverse gear ratio.  Additional 2-byte gear ratios will follow:
 ...";
CM_ SG_ 2566841086 TransGearRatio "The transmission configuration describes the number of forward gears, the number of reverse gears, and the ratio of each gear with the following resolution.";
CM_ SG_ 2566841086 NumberOfForwardGearRatios "Number of forward gear ratios in the transmission, provided as part of the configuration.";
CM_ SG_ 2566841086 NumberOfReverseGearRatios "Number of reverse gear ratios in the transmission, provided as part of the transmission configuration.";
CM_ BO_ 2348941054 "Transmission Control 1
Messages that are requesting control over the receiving device are transmitted at high rate only during the time when the control is active, but may be optionally sent at a slow rate as a \"heartbeat.\"";
CM_ SG_ 2348941054 AutoNeutralReq "This parameter conveys a vehicle system desire to override the operator뭩 current shift selector request (e.g. Drive, Reverse) and shift the transmission into Neutral. 밠anual Return� indicates this parameter has the ability to initiate a ...";
CM_ SG_ 2348941054 TransMode8 "Indicates whether transmission mode 8 is enabled. Modes are manufacturer specific and are not necessarily mutually exclusive. See also SPN 4253.

00  Disable
01  Enable
10  Reserved
11  Take no action";
CM_ SG_ 2348941054 TransMode7 "Indicates whether transmission mode 7 is enabled. Modes are manufacturer specific and are not necessarily mutually exclusive. See also SPN 4252.

00  Disable
01  Enable
10  Reserved
11  Take no action";
CM_ SG_ 2348941054 TransMode6 "Indicates whether transmission mode 6 is enabled. Modes are manufacturer specific and are not necessarily mutually exclusive. See also SPN 4251.

00  Disable
01  Enable
10  Reserved
11  Take no action";
CM_ SG_ 2348941054 TransMode5 "Indicates whether transmission mode 5 is enabled. Modes are manufacturer specific and are not necessarily mutually exclusive. See also SPN 4250.

00  Disable
01  Enable
10  Reserved
11  Take no action";
CM_ SG_ 2348941054 TrnsShftSlectorDisplayModeSwitch "Status of the operator뭩 switch used to 몋oggle� through multiple display modes of a shift selector display.
When a shift selector display is capable of displaying more than just range information, this switch is toggled by the operator to move ...";
CM_ SG_ 2348941054 TransRequestedLaunchGear "Initial gear for the transmission to start out in when the vehicle is launched from a standing stop, as specified by the vehicle operator or vehicle system.  Automatic transmissions typically default to starting out in 1st gear.  However, in ...";
CM_ SG_ 2348941054 TransMode4 "Indicates whether transmission mode 4 is enabled.  Modes are manufacturer specific and are not necessarily mutually exclusive.  See also SPN 2539.

00 Disable
01 Enable
10 Reserved
11 Take no action";
CM_ SG_ 2348941054 TransMode3 "Indicates whether transmission mode 3 is enabled.  Modes are manufacturer specific and are not necessarily mutually exclusive.  See also SPN 2538.

00 Disable
01 Enable
10 Reserved
11 Take no action";
CM_ SG_ 2348941054 TransMode2 "Indicates whether transmission mode 2 is enabled.  Modes are manufacturer specific and are not necessarily mutually exclusive.  See also SPN 2537.

00 Disable
01 Enable
10 Reserved
11 Take no action";
CM_ SG_ 2348941054 TransMode1 "Indicates whether transmission mode 1 is enabled.  Modes are manufacturer specific and are not necessarily mutually exclusive.  See also SPN 2536.

00 Disable
01 Enable
10 Reserved
11 Take no action";
CM_ SG_ 2348941054 TransLoadReductionInhibitRq "Request signal to the transmission to inhibit activation of load reduction functions.
Automatic transmissions may incorporate functions designed to reduce engine load during certain operating conditions (vehicle standstill at bus stop, traffic ...";
CM_ SG_ 2348941054 DisengageDiffLockRqCentralRear "Command signal used to disengage the various differential locks, e.g., to allow an undistributed individual wheel control by ABS.  The differential locks are located as defined in Figure SPN564_A.
00 Engage differential lock
01 Disengage ...";
CM_ SG_ 2348941054 DisengageDiffLockRqCentralFront "Command signal used to disengage the various differential locks, e.g., to allow an undistributed individual wheel control by ABS.  The differential locks are located as defined in Figure SPN564_A.
00 Engage differential lock
01 Disengage ...";
CM_ SG_ 2348941054 DisengageDiffLockRqCentral "Command signal used to disengage the various differential locks, e.g., to allow an undistributed individual wheel control by ABS.  The differential locks are located as defined in Figure SPN564_A.
00 Engage differential lock
01 Disengage ...";
CM_ SG_ 2348941054 DisengageDiffLockRqRearAxle2 "Command signal used to disengage the various differential locks, e.g., to allow an undistributed individual wheel control by ABS.  The differential locks are located as defined in Figure SPN564_A.
00 Engage differential lock
01 Disengage ...";
CM_ SG_ 2348941054 DisengageDiffLockRqRearAxle1 "Command signal used to disengage the various differential locks, e.g., to allow an undistributed individual wheel control by ABS.  The differential locks are located as defined in Figure SPN564_A.
00 Engage differential lock
01 Disengage ...";
CM_ SG_ 2348941054 DisengageDiffLockRqFrontAxle2 "Command signal used to disengage the various differential locks, e.g., to allow an undistributed individual wheel control by ABS.  The differential locks are located as defined in Figure SPN564_A.
00 Engage differential lock
01 Disengage ...";
CM_ SG_ 2348941054 DisengageDiffLockRqFrontAxle1 "Command signal used to disengage the various differential locks, e.g., to allow an undistributed individual wheel control by ABS.  The differential locks are located as defined in Figure SPN564_A.
00 Engage differential lock
01 Disengage ...";
CM_ SG_ 2348941054 TransRequestedGear "Gear requested by the operator, ABS, or engine.
Negative values are reverse gears, positive values are forward gears, zero is neutral, parameter specific indicators are listed below.
Parameter specific values for this parameter are as follows:
 ...";
CM_ SG_ 2348941054 RequestedPercentClutchSlip "Parameter which represents the percent clutch slip requested by a device.";
CM_ SG_ 2348941054 TransReverseGearShiftInhibitRq "Allows devices external to the normal transmission shift selector system to request the transmission to inhibit shifts into any Reverse gear and force the transmission into Neutral if it is currently in Reverse or attempting to shift to Reverse ...";
CM_ SG_ 2348941054 DisengageDrivelineRq "Command signal used to simply disengage the driveline, e.g., to prevent engine drag torque from causing high wheel slip on slippery surfaces.
00 Allow driveline engagement
01 Disengage driveline
10 Reserved
11 Take no action
Note:  If this ...";
CM_ SG_ 2348941054 TrnsTrqeConverterLockupDisableRq "Command signal to override normal transmission control of the torque converter lockup clutch. This command may be used to control lockup as needed for different operating modes or environmental conditions. For example, the torque converter lockup ...";
CM_ SG_ 2348941054 TransGearShiftInhibitRq "Command signal to inhibit gear shifts.

00 Gear shifts are allowed  (disable function)
01 Gear shifts are inhibited  (enable function)
10 Reserved
11 Take no action  (leave function as is)";
CM_ BO_ 2566839806 "Turbocharger";
CM_ SG_ 2566839806 EngTurboOilLevelSwitch "Switch signal which indicates the presence of oil at the turbocharger

     00 = No oil present at turbocharger
     01 = Oil present at turbocharger
     10 = Error
     11 = Not available";
CM_ SG_ 2566839806 EngTurbo1Speed "Rotational velocity of rotor in the turbocharger.";
CM_ SG_ 2566839806 EngTurboLubeOilPress1 "Gage pressure of oil in turbocharger lubrication system.";
CM_ SG_ 2566839806 EngTurboDiffSpeed "The difference between turbocharger speeds on engine systems with 2 or more turbochargers. If there are are more than 2 turbochargers, it will be the difference between the fastest and the slowest turbocharger speed.";
CM_ BO_ 2633911806 "Total Averaged Information
Averages of information accumulated over the life of the engine";
CM_ SG_ 2633911806 EngTotalAverageFuelEconomy "Average fuel economy, equal to total vehicle distance divided by total fuel used, over the life of the engine";
CM_ SG_ 2633911806 EngTotalAverageFuelRate "Average fuel rate, equal to total fuel used divided by total engine hours, over the life of the engine";
CM_ BO_ 2566775550 "Supply Pressure Demand
Used for controlling the supply pressure.  Often used to raise the pressure of a supply pressure circuit in situations where more pneumatic energy is needed.

This message is the setpoint for the PGN 65198 message.";
CM_ SG_ 2566775550 PwertrainCircuitAirSupplyPressRq "Command signal to influence the air pressure in the powertrain circuit.  This parameter is the setpoint for the parameter SPN 6305.";
CM_ SG_ 2566775550 AirSuspensionSupplyPressRq "Command signal to influence the pneumatic pressure in the circuit for the electronically controlled air suspension system.   This parameter is the setpoint for the parameter SPN 1090.";
CM_ SG_ 2566775550 AuxEquipmentSupplyPressRq "Command signal to influence the pneumatic pressure in the auxiliary circuit.   This parameter is the setpoint for the parameter SPN 1089.";
CM_ SG_ 2566775550 ServiceBrakeAirPressRqCircuit2 "Command signal to influence the pneumatic pressure in the service brake circuit or reservoir #2.  This parameter is the setpoint for the parameter SPN 1088.";
CM_ SG_ 2566775550 ServiceBrakeAirPressRqCircuit1 "Command signal to influence the pneumatic pressure in the service brake circuit or reservoir #1.  This parameter is the setpoint for the parameter SPN 1087.";
CM_ SG_ 2566775550 ParkingAnd_orTrailerAirPressRq "Command signal to influence the pneumatic pressure in the circuit or reservoir for the parking brake and/or the trailer supply.  This parameter is the setpoint for the parameter SPN 1086.";
CM_ SG_ 2566775550 PneumaticSupplyPressRq "Command signal to influence the pneumatic pressure in the main reservoir.  This parameter is the setpoint for the parameter SPN 46.";
CM_ BO_ 2566819838 "Supply Pressure 2";
CM_ SG_ 2566819838 EngExtlShutdownAirSupplyPress "Pressure of the air used to shut off the fuel supply to the engine.";
CM_ BO_ 2566839038 "Software Identification
Byte: 1 Number of software identification fields
2-n Software identification(s)
Delimiter (ASCII �*�)
NOTE- The software identification field is variable in length and may contain up to 125 software identification ...";
CM_ SG_ 2566839038 NmbrOfSftwreIdentificationFields "Number of software identification designators represented in the software identification parameter group.";
CM_ SG_ 2566839038 SoftwareIdentification "Software identification of an electronic module.  As an example, this parameter may be represented with ASCII characters MMDDYYaa where MM is the month, DD is the day, YY is the year, and aa is the revision number.
NOTE The ASCII character �*� is ...";
CM_ BO_ 2566841598 "Shutdown";
CM_ SG_ 2566841598 EngOilPressSw "Measured engine oil pressure with respect to the pre-set threshold.

00 = OK (Engine Oil Pressure Above Min Threshold)
01 = Not OK (Engine Oil Pressure Below Min Threshold)
10 = Error (Switch State Cannot Be Determined)
11 = Not Available";
CM_ SG_ 2566841598 ClntLvlEngPrtctionShutdownStatus "Parameter which indicates the configuration of the coolant level engine protection shutdown.
00 - Disabled - calibration does not allow engine protection due to low coolant level or the override is currently active
01 - Enabled - calibration ...";
CM_ SG_ 2566841598 PTOShutdownHasShutdownEng "Status signal which identifies whether or not the engine has been shutdown by the PTO shutdown system.

00 - No
01 - Yes
10 - Error
11 - Not available";
CM_ SG_ 2566841598 EngAirShutoffStatus "State signal which indicates the actual measured position of the Air Shutoff.
00 - Air flow allowed to engine
01 - Air flow restricted
10 - Error
11 - Not Available
Note:   This parameter, in conjunction with SPN 2813 - \"Engine Air Shutoff ...";
CM_ SG_ 2566841598 EngOverspeedTest "The engine overspeed test signal as measured by the reporting ECM.  Engine Overspeed Test is a mechanism to simulate engine overspeed situations, while operating the engine within the engine's safe operating range.
State signal which indicates when ...";
CM_ SG_ 2566841598 EngAirShutoffCmdStatus "State signal which indicates when the Air Shutoff  driver output is being driven. Disabled means controller wants air flowing to the engine. Status of the airflow  shutoff as being commanded by the ECU.
00 Air Shutoff Disabled, not attempting to ...";
CM_ SG_ 2566841598 EngAlarmOutputCmdStatus "State signal which indicates when the Alarm driver output is being driven. Not active means the Controller has no alarm level conditions.
00 Engine Alarm Output Command Not Active
01 Engine Alarm Output Command Active
10 Reserved
11 Not ...";
CM_ SG_ 2566841598 EngAlarmAcknowledge "The Engine Alarm Acknowledge Input signal as measured by the reporting ECU.  The Engine Alarm Acknowledge is a mechanism for external acknowledgement of the SPN 2814,  Engine Alarm Output Command.
00 Engine Alarm Acknowledge  Not Active
01 Engine ...";
CM_ SG_ 2566841598 EngProtectionSystemConfig "Parameter which indicates the configuration of the engine shutdown system.

00 - Disabled in calibration
01 - Enabled in calibration
10 - Error
11 - Not available";
CM_ SG_ 2566841598 EngProtectionSystemTimerState "Status signal which indicates the current mode of the engine protection system timer system.  See Figure SPN1107_A.

00 - Inactive
01 - Active
10 - Error
11 - Not available";
CM_ SG_ 2566841598 EngProtectionSystemTimerOverride "Status signal which indicates the status of the override feature of the engine protection system timer. See Figure SPN1107_A.

00 - Inactive
01 - Active
10 - Error
11 - Not available";
CM_ SG_ 2566841598 EngPrtctnSystmApprachingShutdown "Status signal which indicates that engine shutdown is imminent.  This engine protection signal can be a result of different systems failing, i.e., engine overheating. See Figure SPN1107_A.
00 - Not approaching
01 - Approaching
10 - Error
11 - ...";
CM_ SG_ 2566841598 EngPrtectionSystemHasShutdownEng "Status signal which indicates whether or not the engine protection system has shutdown the engine.  See Figure SPN1107_A.

00 - No
01 - Yes
10 - Error
11 - Not available";
CM_ SG_ 2566841598 EngWaitToStartLamp "Lamp signal which indicates that the engine is too cold to start and the operator should wait until the signal becomes inactive (turns off).  See SPN 5416 for the lamp operating condition.

00 - Off
01 - On
10 - Error
11 - Not available";
CM_ SG_ 2566841598 RefrigerantHighPressSwitch "Switch signal which indicates the position of the high pressure switch in the coolant circuit of an air conditioning system.  When the switch is enabled, the pressure inside the circuit is too high and the compressor clutch may be disengaged.
00 - ...";
CM_ SG_ 2566841598 RefrigerantLowPressSwitch "Switch signal which indicates the position of the low pressure switch in the coolant circuit of an air conditioning system.  When the switch is enabled, the pressure inside the circuit is too low and the compressor clutch may be disengaged.
00 - ...";
CM_ SG_ 2566841598 A_CHighPressFanSwitch "Switch signal which indicates that the pressure in the coolant circuit of an air conditioning system is high and the fan may be engaged.

00 - Pressure normal
01 - Pressure high, fan may be engaged
10 - Error
11 - Not available";
CM_ SG_ 2566841598 EngIdleShutdownTimerFunction "Parameter which indicates the configuration of the idle shutdown timer system.

00 - Disabled in calibration
01 - Enabled in calibration
10 - Error
11 - Not available";
CM_ SG_ 2566841598 EngIdleShutdownTimerState "Status signal which indicates the current mode of operation of the idle shutdown timer system.  See Figure SPN590_A.

00 - Inactive
01 - Active
10 - Error
11 - Not available";
CM_ SG_ 2566841598 EngIdleShutdownTimerOverride "Status signal which indicates the status of the override feature of the idle shutdown timer system.  See Figure SPN590_A.

00 - Inactive
01 - Active
10 - Error
11 - Not available";
CM_ SG_ 2566841598 EngIdleShutdownDriverAlertMode "Status signal which indicates the status of the driver alert mode of the idle shutdown timer system.  While the driver alert mode is active, the idle shutdown timer may be overridden.  See Figure SPN590_A.
00 - Inactive
01 - Active
10 - Error
11 ...";
CM_ SG_ 2566841598 EngIdleShutdownHasShutdownEng "Status signal which identifies whether or not the engine has been shutdown by the idle shutdown timer system.  See Figure SPN590_A.

00 - No
01 - Yes
10 - Error
11 - Not available";
BA_DEF_ SG_  "SigType" ENUM  "Default","Range","RangeSigned","ASCII","Discrete","Control","ReferencePGN","DTC","StringDelimiter","StringLength","StringLengthControl","MessageCounter","MessageChecksum";
BA_DEF_ SG_  "GenSigStartValue" INT 0 2147483647;
BA_DEF_ SG_  "GenSigSendType" ENUM  "Cyclic","OnWrite","OnWriteWithRepetition","OnChange","OnChangeWithRepetition","IfActive","IfActiveWithRepetition","NoSigSendType";
BA_DEF_ SG_  "GenSigILSupport" ENUM  "No","Yes";
BA_DEF_ SG_  "GenSigEVName" STRING ;
BA_DEF_ SG_  "SPN" INT 0 524287;
BA_DEF_ BO_  "TpJ1939VarDlc" ENUM  "No","Yes";
BA_DEF_ BO_  "GenMsgStartDelayTime" INT 0 100000;
BA_DEF_ BO_  "GenMsgILSupport" ENUM  "No","Yes";
BA_DEF_ BO_  "GenMsgDelayTime" INT 0 1000;
BA_DEF_ BO_  "GenMsgRequestable" INT 0 1;
BA_DEF_ BO_  "GenMsgSendType" ENUM  "cyclic","NotUsed","NotUsed","NotUsed","NotUsed","NotUsed","NotUsed","IfActive","noMsgSendType";
BA_DEF_ BO_  "VFrameFormat" ENUM  "StandardCAN","ExtendedCAN","reserved","J1939PG";
BA_DEF_ BO_  "GenMsgCycleTime" INT 0 3600000;
BA_DEF_ SG_  "SystemSignalLongSymbol" STRING ;
BA_DEF_DEF_  "SigType" "Default";
BA_DEF_DEF_  "GenSigStartValue" 0;
BA_DEF_DEF_  "GenSigSendType" "NoSigSendType";
BA_DEF_DEF_  "GenSigILSupport" "Yes";
BA_DEF_DEF_  "GenSigEVName" "Env@Nodename_@Signame";
BA_DEF_DEF_  "SPN" 0;
BA_DEF_DEF_  "TpJ1939VarDlc" "No";
BA_DEF_DEF_  "GenMsgStartDelayTime" 0;
BA_DEF_DEF_  "GenMsgILSupport" "Yes";
BA_DEF_DEF_  "GenMsgDelayTime" 0;
BA_DEF_DEF_  "GenMsgRequestable" 1;
BA_DEF_DEF_  "GenMsgSendType" "noMsgSendType";
BA_DEF_DEF_  "VFrameFormat" "J1939PG";
BA_DEF_DEF_  "GenMsgCycleTime" 0;
BA_DEF_DEF_  "SystemSignalLongSymbol" "";
BA_ "GenMsgCycleTime" BO_ 2566807294 1000;
BA_ "GenMsgSendType" BO_ 2566807294 0;
BA_ "TpJ1939VarDlc" BO_ 2564095742 1;
BA_ "GenMsgCycleTime" BO_ 2349137662 20;
BA_ "GenMsgCycleTime" BO_ 2566848510 10000;
BA_ "GenMsgSendType" BO_ 2566848510 0;
BA_ "GenMsgDelayTime" BO_ 2566848510 1000;
BA_ "GenMsgCycleTime" BO_ 2566804222 100;
BA_ "GenMsgSendType" BO_ 2566804222 0;
BA_ "GenMsgCycleTime" BO_ 2566819326 1000;
BA_ "GenMsgSendType" BO_ 2566819326 0;
BA_ "GenMsgCycleTime" BO_ 2566845438 1000;
BA_ "GenMsgSendType" BO_ 2566845438 0;
BA_ "TpJ1939VarDlc" BO_ 2566843646 1;
BA_ "GenMsgCycleTime" BO_ 2566809854 1000;
BA_ "GenMsgSendType" BO_ 2566809854 0;
BA_ "GenMsgCycleTime" BO_ 2566842622 1000;
BA_ "GenMsgSendType" BO_ 2566842622 0;
BA_ "GenMsgCycleTime" BO_ 2566832638 1000;
BA_ "GenMsgSendType" BO_ 2566832638 0;
BA_ "GenMsgCycleTime" BO_ 2565868030 10;
BA_ "GenMsgSendType" BO_ 2565868030 0;
BA_ "GenMsgCycleTime" BO_ 2566803454 100;
BA_ "GenMsgSendType" BO_ 2566803454 0;
BA_ "GenMsgCycleTime" BO_ 2566840574 100;
BA_ "GenMsgSendType" BO_ 2566840574 0;
BA_ "GenMsgCycleTime" BO_ 2348875518 10;
BA_ "GenMsgSendType" BO_ 2348875518 0;
BA_ "GenMsgCycleTime" BO_ 2566845694 10000;
BA_ "GenMsgSendType" BO_ 2566845694 0;
BA_ "GenMsgCycleTime" BO_ 2566821630 100;
BA_ "GenMsgSendType" BO_ 2566821630 0;
BA_ "GenMsgCycleTime" BO_ 2365484286 50;
BA_ "GenMsgSendType" BO_ 2365484286 0;
BA_ "GenMsgCycleTime" BO_ 2566771710 1000;
BA_ "GenMsgSendType" BO_ 2566771710 0;
BA_ "GenMsgCycleTime" BO_ 2566821886 1000;
BA_ "GenMsgSendType" BO_ 2566821886 0;
BA_ "GenMsgCycleTime" BO_ 2566822142 1000;
BA_ "GenMsgSendType" BO_ 2566822142 0;
BA_ "GenMsgCycleTime" BO_ 2566822398 1000;
BA_ "GenMsgSendType" BO_ 2566822398 0;
BA_ "GenMsgCycleTime" BO_ 2566822654 1000;
BA_ "GenMsgSendType" BO_ 2566822654 0;
BA_ "GenMsgCycleTime" BO_ 2633931774 1000;
BA_ "GenMsgSendType" BO_ 2633931774 0;
BA_ "GenMsgCycleTime" BO_ 2566802430 5000;
BA_ "GenMsgSendType" BO_ 2566802430 0;
BA_ "GenMsgCycleTime" BO_ 2348941054 50;
BA_ "GenMsgSendType" BO_ 2348941054 0;
BA_ "GenMsgCycleTime" BO_ 2566839806 1000;
BA_ "GenMsgSendType" BO_ 2566839806 0;
BA_ "GenMsgCycleTime" BO_ 2566775550 1000;
BA_ "GenMsgCycleTime" BO_ 2566819838 1000;
BA_ "GenMsgSendType" BO_ 2566819838 0;
BA_ "TpJ1939VarDlc" BO_ 2566839038 1;
BA_ "GenMsgCycleTime" BO_ 2566841598 1000;
BA_ "GenMsgSendType" BO_ 2566841598 0;
BA_ "SigType" SG_ 2566807294 TyreModulePowerSupply 4;
BA_ "SystemSignalLongSymbol" SG_ 2566764798 NOxConvertingCatalystAdsorberEna "NOxConvertingCatalystAdsorberEnabled";
BA_ "SystemSignalLongSymbol" SG_ 2566764798 BoostPressureControlSystemComple "BoostPressureControlSystemCompleted";
BA_ "SystemSignalLongSymbol" SG_ 2566764798 BoostPressureControlSystemEnable "BoostPressureControlSystemEnabled";
BA_ "SPN" SG_ 2566764798 NumOfWarmUpsSinceDTCsCleared 3302;
BA_ "SigType" SG_ 2566764798 NumOfWarmUpsSinceDTCsCleared 1;
BA_ "SPN" SG_ 2566764798 TimeSinceEngineStart 3301;
BA_ "SigType" SG_ 2566764798 TimeSinceEngineStart 1;
BA_ "SPN" SG_ 2564095742 DataSecurityParameter 1597;
BA_ "SPN" SG_ 2564095742 SecurityEntityType 1479;
BA_ "SPN" SG_ 2564095742 SecurityEntityLength 1596;
BA_ "SPN" SG_ 2349137662 XBRMessageChecksum 3188;
BA_ "SigType" SG_ 2349137662 XBRMessageChecksum 12;
BA_ "SPN" SG_ 2349137662 XBRMessageCounter 3189;
BA_ "SigType" SG_ 2349137662 XBRMessageCounter 11;
BA_ "SPN" SG_ 2349137662 XBRUrgency 4099;
BA_ "SigType" SG_ 2349137662 XBRUrgency 1;
BA_ "SPN" SG_ 2349137662 XBRCtrlMode 2916;
BA_ "SigType" SG_ 2349137662 XBRCtrlMode 5;
BA_ "SPN" SG_ 2349137662 XBRPriority 2915;
BA_ "SigType" SG_ 2349137662 XBRPriority 5;
BA_ "SPN" SG_ 2349137662 XBREBIMode 2914;
BA_ "SigType" SG_ 2349137662 XBREBIMode 5;
BA_ "SPN" SG_ 2349137662 ExtlAccelerationDemand 2920;
BA_ "GenSigStartValue" SG_ 2349137662 ExtlAccelerationDemand 11647;
BA_ "SigType" SG_ 2349137662 ExtlAccelerationDemand 1;
BA_ "SPN" SG_ 2566848510 AutoStartReqInhInd 9373;
BA_ "SigType" SG_ 2566848510 AutoStartReqInhInd 5;
BA_ "SPN" SG_ 2566848510 FuelSupplyEstRemainingDist 8428;
BA_ "SigType" SG_ 2566848510 FuelSupplyEstRemainingDist 1;
BA_ "SPN" SG_ 2566848510 WaterInChargeADAfterChargeACInd 8611;
BA_ "SigType" SG_ 2566848510 WaterInChargeADAfterChargeACInd 4;
BA_ "SPN" SG_ 2566848510 EngOverloadedInd 8612;
BA_ "SigType" SG_ 2566848510 EngOverloadedInd 5;
BA_ "SPN" SG_ 2566848510 EmssnCtrlSystmOprtrIndcmntSvrity 5826;
BA_ "SPN" SG_ 2566848510 DrvrWarningSystemIndicatorStatus 5825;
BA_ "SPN" SG_ 2566848510 OperatorShiftPrompt 5675;
BA_ "SigType" SG_ 2566848510 OperatorShiftPrompt 5;
BA_ "SPN" SG_ 2566848510 WaterInFuelIndicator 97;
BA_ "SigType" SG_ 2566848510 WaterInFuelIndicator 4;
BA_ "SPN" SG_ 2566848510 WaterInFuelIndicator2 6301;
BA_ "SigType" SG_ 2566848510 WaterInFuelIndicator2 4;
BA_ "SPN" SG_ 2566843134 AxleLocation 928;
BA_ "SPN" SG_ 2566843134 CargoWeight_30 522230;
BA_ "SigType" SG_ 2566843134 CargoWeight_30 1;
BA_ "SPN" SG_ 2566843134 CargoWeight_20 522220;
BA_ "SigType" SG_ 2566843134 CargoWeight_20 1;
BA_ "SPN" SG_ 2566843134 CargoWeight_10 522210;
BA_ "SigType" SG_ 2566843134 CargoWeight_10 1;
BA_ "SPN" SG_ 2566843134 CargoWeight_00 522200;
BA_ "SigType" SG_ 2566843134 CargoWeight_00 1;
BA_ "SPN" SG_ 2566843134 TrailerWeight_30 522130;
BA_ "SigType" SG_ 2566843134 TrailerWeight_30 1;
BA_ "SPN" SG_ 2566843134 TrailerWeight_20 522120;
BA_ "SigType" SG_ 2566843134 TrailerWeight_20 1;
BA_ "SPN" SG_ 2566843134 TrailerWeight_10 522110;
BA_ "SigType" SG_ 2566843134 TrailerWeight_10 1;
BA_ "SPN" SG_ 2566843134 TrailerWeight_00 522100;
BA_ "SigType" SG_ 2566843134 TrailerWeight_00 1;
BA_ "SPN" SG_ 2566843134 AxleWeight_30 522030;
BA_ "SigType" SG_ 2566843134 AxleWeight_30 1;
BA_ "SPN" SG_ 2566843134 AxleWeight_20 522020;
BA_ "SigType" SG_ 2566843134 AxleWeight_20 1;
BA_ "SPN" SG_ 2566843134 AxleWeight_10 522010;
BA_ "SigType" SG_ 2566843134 AxleWeight_10 1;
BA_ "SPN" SG_ 2566843134 AxleWeight_00 522000;
BA_ "SigType" SG_ 2566843134 AxleWeight_00 1;
BA_ "SPN" SG_ 2566804222 SLIBattery2NetCurrent 7498;
BA_ "SigType" SG_ 2566804222 SLIBattery2NetCurrent 1;
BA_ "SPN" SG_ 2566804222 NetBatteryCurrent 2579;
BA_ "SigType" SG_ 2566804222 NetBatteryCurrent 1;
BA_ "SPN" SG_ 2566804222 AltCurrent 1795;
BA_ "SigType" SG_ 2566804222 AltCurrent 1;
BA_ "SPN" SG_ 2566819326 ECUPowerOutputSupplyVoltage3 3599;
BA_ "SigType" SG_ 2566819326 ECUPowerOutputSupplyVoltage3 1;
BA_ "SPN" SG_ 2566819326 ECUPowerOutputSupplyVoltage2 3598;
BA_ "SigType" SG_ 2566819326 ECUPowerOutputSupplyVoltage2 1;
BA_ "SPN" SG_ 2566819326 ECUPowerOutputSupplyVoltage1 3597;
BA_ "SigType" SG_ 2566819326 ECUPowerOutputSupplyVoltage1 1;
BA_ "SPN" SG_ 2566819326 BatteryPotential_PowerInput2 444;
BA_ "SigType" SG_ 2566819326 BatteryPotential_PowerInput2 1;
BA_ "SPN" SG_ 2566845438 Longitude 585;
BA_ "SigType" SG_ 2566845438 Longitude 1;
BA_ "SPN" SG_ 2566845438 Latitude 584;
BA_ "SigType" SG_ 2566845438 Latitude 1;
BA_ "SPN" SG_ 2566843646 VehicleIdentificationNumber 237;
BA_ "SigType" SG_ 2566843646 VehicleIdentificationNumber 8;
BA_ "SPN" SG_ 2566842366 TotalPowerTakeoffHours 248;
BA_ "SigType" SG_ 2566842366 TotalPowerTakeoffHours 1;
BA_ "SPN" SG_ 2566842366 TotalVehicleHours 246;
BA_ "SigType" SG_ 2566842366 TotalVehicleHours 1;
BA_ "SPN" SG_ 2566809854 HydOilLevel 2602;
BA_ "SigType" SG_ 2566809854 HydOilLevel 1;
BA_ "SPN" SG_ 2566809854 WinchOilPressSwitch 1857;
BA_ "SigType" SG_ 2566809854 WinchOilPressSwitch 4;
BA_ "SPN" SG_ 2566809854 HydOilFilterRestrictionSwitch 1713;
BA_ "SigType" SG_ 2566809854 HydOilFilterRestrictionSwitch 4;
BA_ "SPN" SG_ 2566809854 HydTemp 1638;
BA_ "SigType" SG_ 2566809854 HydTemp 1;
BA_ "SPN" SG_ 2566842622 Altitude 580;
BA_ "SigType" SG_ 2566842622 Altitude 1;
BA_ "SPN" SG_ 2566842622 Pitch 583;
BA_ "SigType" SG_ 2566842622 Pitch 1;
BA_ "SPN" SG_ 2566842622 NavigationBasedVehicleSpeed 517;
BA_ "SigType" SG_ 2566842622 NavigationBasedVehicleSpeed 1;
BA_ "SPN" SG_ 2566842622 CompassBearing 165;
BA_ "SigType" SG_ 2566842622 CompassBearing 1;
BA_ "SPN" SG_ 2566832638 HighResolutionTripDistance 918;
BA_ "SigType" SG_ 2566832638 HighResolutionTripDistance 1;
BA_ "SPN" SG_ 2566832638 HghRsolutionTotalVehicleDistance 917;
BA_ "SigType" SG_ 2566832638 HghRsolutionTotalVehicleDistance 1;
BA_ "SPN" SG_ 2565868030 LongitudinalAcceleration 1810;
BA_ "SigType" SG_ 2565868030 LongitudinalAcceleration 1;
BA_ "SPN" SG_ 2565868030 LateralAcceleration 1809;
BA_ "SigType" SG_ 2565868030 LateralAcceleration 1;
BA_ "SPN" SG_ 2565868030 YawRate 1808;
BA_ "SigType" SG_ 2565868030 YawRate 1;
BA_ "SPN" SG_ 2565868030 SteerWheelAngleSensorType 1812;
BA_ "SigType" SG_ 2565868030 SteerWheelAngleSensorType 5;
BA_ "SPN" SG_ 2565868030 SteerWheelTurnCounter 1811;
BA_ "GenSigStartValue" SG_ 2565868030 SteerWheelTurnCounter 22;
BA_ "SPN" SG_ 2565868030 SteerWheelAngle 1807;
BA_ "SigType" SG_ 2565868030 SteerWheelAngle 1;
BA_ "SPN" SG_ 2566803454 TrailerVDCActive 5624;
BA_ "SigType" SG_ 2566803454 TrailerVDCActive 5;
BA_ "SPN" SG_ 2566803454 YCBrakeCtrlActive 1819;
BA_ "SigType" SG_ 2566803454 YCBrakeCtrlActive 5;
BA_ "SPN" SG_ 2566803454 YCEngCtrlActive 1817;
BA_ "SigType" SG_ 2566803454 YCEngCtrlActive 5;
BA_ "SPN" SG_ 2566803454 ROPBrakeCtrlActive 1818;
BA_ "SigType" SG_ 2566803454 ROPBrakeCtrlActive 5;
BA_ "SPN" SG_ 2566803454 ROPEngCtrlActive 1816;
BA_ "SigType" SG_ 2566803454 ROPEngCtrlActive 5;
BA_ "SPN" SG_ 2566803454 VDCBrakeLightRq 1815;
BA_ "SigType" SG_ 2566803454 VDCBrakeLightRq 5;
BA_ "SPN" SG_ 2566803454 VDCFullyOperational 1814;
BA_ "SigType" SG_ 2566803454 VDCFullyOperational 5;
BA_ "SPN" SG_ 2566803454 VDCInformationSignal 1813;
BA_ "SigType" SG_ 2566803454 VDCInformationSignal 5;
BA_ "SPN" SG_ 2566840574 TotalVehicleDistance 245;
BA_ "SigType" SG_ 2566840574 TotalVehicleDistance 1;
BA_ "SPN" SG_ 2566840574 TripDistance 244;
BA_ "SigType" SG_ 2566840574 TripDistance 1;
BA_ "SPN" SG_ 2633938686 TripCruiseDistance 1019;
BA_ "SigType" SG_ 2633938686 TripCruiseDistance 1;
BA_ "SPN" SG_ 2633938686 TripMaxVehicleSpeed 1018;
BA_ "SigType" SG_ 2633938686 TripMaxVehicleSpeed 1;
BA_ "SPN" SG_ 2633937150 TripAirCompressorOnTime 1038;
BA_ "SigType" SG_ 2633937150 TripAirCompressorOnTime 1;
BA_ "SPN" SG_ 2633937150 TripIdleTime 1037;
BA_ "SigType" SG_ 2633937150 TripIdleTime 1;
BA_ "SPN" SG_ 2633937150 TripEngRunningTime 1036;
BA_ "SigType" SG_ 2633937150 TripEngRunningTime 1;
BA_ "SPN" SG_ 2633937150 TripCruiseTime 1034;
BA_ "SigType" SG_ 2633937150 TripCruiseTime 1;
BA_ "SPN" SG_ 2633937150 TripPTOGovernorTime 1035;
BA_ "SigType" SG_ 2633937150 TripPTOGovernorTime 1;
BA_ "SPN" SG_ 2633938174 TripTimeInDerateByEng 1027;
BA_ "SigType" SG_ 2633938174 TripTimeInDerateByEng 1;
BA_ "SPN" SG_ 2633938174 TripTimeInGearDown 1026;
BA_ "SigType" SG_ 2633938174 TripTimeInGearDown 1;
BA_ "SPN" SG_ 2633938174 TripTimeInTopGear 1025;
BA_ "SigType" SG_ 2633938174 TripTimeInTopGear 1;
BA_ "SPN" SG_ 2633938174 TripTimeInVSL 1024;
BA_ "SigType" SG_ 2633938174 TripTimeInVSL 1;
BA_ "SPN" SG_ 2633938430 TripSuddenDecelerations 1023;
BA_ "SigType" SG_ 2633938430 TripSuddenDecelerations 1;
BA_ "SPN" SG_ 2633938430 TrpNumberOfIdleShutdownOverrides 1022;
BA_ "SigType" SG_ 2633938430 TrpNumberOfIdleShutdownOverrides 1;
BA_ "SPN" SG_ 2633938430 TripNumberOfIdleShutdowns 1021;
BA_ "SigType" SG_ 2633938430 TripNumberOfIdleShutdowns 1;
BA_ "SPN" SG_ 2633938430 TripNumberOfHotShutdowns 1020;
BA_ "SigType" SG_ 2633938430 TripNumberOfHotShutdowns 1;
BA_ "SPN" SG_ 2348875518 MessageChecksum 4207;
BA_ "SigType" SG_ 2348875518 MessageChecksum 12;
BA_ "SPN" SG_ 2348875518 MessageCounter 4206;
BA_ "SigType" SG_ 2348875518 MessageCounter 11;
BA_ "SPN" SG_ 2348875518 EngRequestedTorqueHighResolution 4191;
BA_ "SPN" SG_ 2348875518 TSC1CtrlPurpose 3350;
BA_ "SPN" SG_ 2348875518 TSC1TransRate 3349;
BA_ "SPN" SG_ 2348875518 EngRequestedTorque_TorqueLimit 518;
BA_ "SigType" SG_ 2348875518 EngRequestedTorque_TorqueLimit 1;
BA_ "SPN" SG_ 2348875518 EngRequestedSpeed_SpeedLimit 898;
BA_ "SigType" SG_ 2348875518 EngRequestedSpeed_SpeedLimit 1;
BA_ "SPN" SG_ 2348875518 OverrideCtrlModePriority 897;
BA_ "SigType" SG_ 2348875518 OverrideCtrlModePriority 5;
BA_ "SPN" SG_ 2348875518 EngRequestedSpeedCtrlConditions 696;
BA_ "SigType" SG_ 2348875518 EngRequestedSpeedCtrlConditions 5;
BA_ "SPN" SG_ 2348875518 EngOverrideCtrlMode 695;
BA_ "SigType" SG_ 2348875518 EngOverrideCtrlMode 5;
BA_ "SPN" SG_ 2566766846 TransitRunStatus 3046;
BA_ "SigType" SG_ 2566766846 TransitRunStatus 5;
BA_ "SPN" SG_ 2566766846 VehicleUseStatus 3045;
BA_ "SigType" SG_ 2566766846 VehicleUseStatus 5;
BA_ "SPN" SG_ 2566766846 SilentAlarmStatus 3044;
BA_ "SigType" SG_ 2566766846 SilentAlarmStatus 5;
BA_ "SPN" SG_ 2566766846 PatronCount 3047;
BA_ "SigType" SG_ 2566766846 PatronCount 1;
BA_ "SPN" SG_ 2566766846 TypeOfPassengerCount 3043;
BA_ "SPN" SG_ 2566765310 FareboxAlarmIdentifier 3181;
BA_ "SPN" SG_ 2566765310 FareboxEmergencyStatus 3179;
BA_ "SigType" SG_ 2566765310 FareboxEmergencyStatus 4;
BA_ "SPN" SG_ 2566765566 TransferSold 3168;
BA_ "SPN" SG_ 2566765566 TransferType 3173;
BA_ "SPN" SG_ 2566765566 TypeOfService 3172;
BA_ "SPN" SG_ 2566765566 InitialFareAgency 3167;
BA_ "GenSigStartValue" SG_ 2566765566 InitialFareAgency 1;
BA_ "SPN" SG_ 2566765566 PassCategory 3166;
BA_ "SPN" SG_ 2566765566 FareValidity 3165;
BA_ "SPN" SG_ 2566765566 PaymentDetails 3177;
BA_ "SPN" SG_ 2566765566 TypeOfFare 3176;
BA_ "SPN" SG_ 2566765566 PassengerType 3171;
BA_ "SPN" SG_ 2566765566 TransactionType 3170;
BA_ "SPN" SG_ 2566765566 RouteNumber 3169;
BA_ "SPN" SG_ 2566765822 DriversFareboxSecurityCode 3164;
BA_ "SPN" SG_ 2566765822 AssignedBlock 3163;
BA_ "SPN" SG_ 2566765822 AssignedRun 3162;
BA_ "SPN" SG_ 2566765822 AssignedRoute 3160;
BA_ "SPN" SG_ 2566765822 PatternNumber 3161;
BA_ "SPN" SG_ 2566765822 TripNumber 3159;
BA_ "SPN" SG_ 2566765822 FarePresets 3175;
BA_ "SPN" SG_ 2566765822 TripDirection 3174;
BA_ "SPN" SG_ 2566765822 TripStatus 3180;
BA_ "SPN" SG_ 2566765822 FareboxServiceStatus 3178;
BA_ "SigType" SG_ 2566765822 FareboxServiceStatus 4;
BA_ "SPN" SG_ 2566766078 VehicleID 3085;
BA_ "SigType" SG_ 2566766078 VehicleID 1;
BA_ "SPN" SG_ 2566766078 StrobeActivationCtrlStatus 3082;
BA_ "SigType" SG_ 2566766078 StrobeActivationCtrlStatus 4;
BA_ "SPN" SG_ 2566766078 TransitDoorEnable 3083;
BA_ "SigType" SG_ 2566766078 TransitDoorEnable 4;
BA_ "SPN" SG_ 2566766078 PriorityOfRespSentByEmitter 3084;
BA_ "SPN" SG_ 2566766078 IntrsctnPrmptionRequest_Response 3079;
BA_ "SigType" SG_ 2566766078 IntrsctnPrmptionRequest_Response 4;
BA_ "SPN" SG_ 2566766078 TransitRouteIDUsage 3080;
BA_ "SigType" SG_ 2566766078 TransitRouteIDUsage 4;
BA_ "SPN" SG_ 2566766078 RangeCodeEnable 3081;
BA_ "SigType" SG_ 2566766078 RangeCodeEnable 4;
BA_ "SPN" SG_ 2566766590 NmbrOfBytsInThMlpstIdntification 3070;
BA_ "SigType" SG_ 2566766590 NmbrOfBytsInThMlpstIdntification 1;
BA_ "SPN" SG_ 2566766334 NmbrOfBytsInThTrnstAssgndBlckIdn 3073;
BA_ "GenSigStartValue" SG_ 2566766334 NmbrOfBytsInThTrnstAssgndBlckIdn 1;
BA_ "SigType" SG_ 2566766334 NmbrOfBytsInThTrnstAssgndBlckIdn 1;
BA_ "SPN" SG_ 2566766334 NmbrOfBytsInThTrnstAssgndRnIdntt 3072;
BA_ "GenSigStartValue" SG_ 2566766334 NmbrOfBytsInThTrnstAssgndRnIdntt 1;
BA_ "SigType" SG_ 2566766334 NmbrOfBytsInThTrnstAssgndRnIdntt 1;
BA_ "SPN" SG_ 2566766334 NmbrOfBytsInThTrnstAssgndRtIdntt 3071;
BA_ "GenSigStartValue" SG_ 2566766334 NmbrOfBytsInThTrnstAssgndRtIdntt 1;
BA_ "SigType" SG_ 2566766334 NmbrOfBytsInThTrnstAssgndRtIdntt 1;
BA_ "SPN" SG_ 2566766334 Agency 3078;
BA_ "SPN" SG_ 2561605374 TireLocation 3192;
BA_ "SPN" SG_ 2561605374 ReferenceTirePressSetting_33 521833;
BA_ "SigType" SG_ 2561605374 ReferenceTirePressSetting_33 1;
BA_ "SPN" SG_ 2561605374 ReferenceTirePressSetting_32 521832;
BA_ "SigType" SG_ 2561605374 ReferenceTirePressSetting_32 1;
BA_ "SPN" SG_ 2561605374 ReferenceTirePressSetting_31 521831;
BA_ "SigType" SG_ 2561605374 ReferenceTirePressSetting_31 1;
BA_ "SPN" SG_ 2561605374 ReferenceTirePressSetting_30 521830;
BA_ "SigType" SG_ 2561605374 ReferenceTirePressSetting_30 1;
BA_ "SPN" SG_ 2561605374 ReferenceTirePressSetting_23 521823;
BA_ "SigType" SG_ 2561605374 ReferenceTirePressSetting_23 1;
BA_ "SPN" SG_ 2561605374 ReferenceTirePressSetting_22 521822;
BA_ "SigType" SG_ 2561605374 ReferenceTirePressSetting_22 1;
BA_ "SPN" SG_ 2561605374 ReferenceTirePressSetting_21 521821;
BA_ "SigType" SG_ 2561605374 ReferenceTirePressSetting_21 1;
BA_ "SPN" SG_ 2561605374 ReferenceTirePressSetting_20 521820;
BA_ "SigType" SG_ 2561605374 ReferenceTirePressSetting_20 1;
BA_ "SPN" SG_ 2561605374 ReferenceTirePressSetting_13 521813;
BA_ "SigType" SG_ 2561605374 ReferenceTirePressSetting_13 1;
BA_ "SPN" SG_ 2561605374 ReferenceTirePressSetting_12 521812;
BA_ "SigType" SG_ 2561605374 ReferenceTirePressSetting_12 1;
BA_ "SPN" SG_ 2561605374 ReferenceTirePressSetting_11 521811;
BA_ "SigType" SG_ 2561605374 ReferenceTirePressSetting_11 1;
BA_ "SPN" SG_ 2561605374 ReferenceTirePressSetting_10 521810;
BA_ "SigType" SG_ 2561605374 ReferenceTirePressSetting_10 1;
BA_ "SPN" SG_ 2561605374 ReferenceTirePressSetting_01 521801;
BA_ "SigType" SG_ 2561605374 ReferenceTirePressSetting_01 1;
BA_ "SPN" SG_ 2561605374 ReferenceTirePressSetting_00 521800;
BA_ "SigType" SG_ 2561605374 ReferenceTirePressSetting_00 1;
BA_ "SPN" SG_ 2566765054 ReferenceTirePress_33 521933;
BA_ "SigType" SG_ 2566765054 ReferenceTirePress_33 1;
BA_ "SPN" SG_ 2566765054 ReferenceTirePress_32 521932;
BA_ "SigType" SG_ 2566765054 ReferenceTirePress_32 1;
BA_ "SPN" SG_ 2566765054 ReferenceTirePress_31 521931;
BA_ "SigType" SG_ 2566765054 ReferenceTirePress_31 1;
BA_ "SPN" SG_ 2566765054 ReferenceTirePress_30 521930;
BA_ "SigType" SG_ 2566765054 ReferenceTirePress_30 1;
BA_ "SPN" SG_ 2566765054 ReferenceTirePress_23 521923;
BA_ "SigType" SG_ 2566765054 ReferenceTirePress_23 1;
BA_ "SPN" SG_ 2566765054 ReferenceTirePress_22 521922;
BA_ "SigType" SG_ 2566765054 ReferenceTirePress_22 1;
BA_ "SPN" SG_ 2566765054 ReferenceTirePress_21 521921;
BA_ "SigType" SG_ 2566765054 ReferenceTirePress_21 1;
BA_ "SPN" SG_ 2566765054 ReferenceTirePress_20 521920;
BA_ "SigType" SG_ 2566765054 ReferenceTirePress_20 1;
BA_ "SPN" SG_ 2566765054 ReferenceTirePress_13 521913;
BA_ "SigType" SG_ 2566765054 ReferenceTirePress_13 1;
BA_ "SPN" SG_ 2566765054 ReferenceTirePress_12 521912;
BA_ "SigType" SG_ 2566765054 ReferenceTirePress_12 1;
BA_ "SPN" SG_ 2566765054 ReferenceTirePress_11 521911;
BA_ "SigType" SG_ 2566765054 ReferenceTirePress_11 1;
BA_ "SPN" SG_ 2566765054 ReferenceTirePress_10 521910;
BA_ "SigType" SG_ 2566765054 ReferenceTirePress_10 1;
BA_ "SPN" SG_ 2566765054 ReferenceTirePress_01 521901;
BA_ "SigType" SG_ 2566765054 ReferenceTirePress_01 1;
BA_ "SPN" SG_ 2566765054 ReferenceTirePress_00 521900;
BA_ "SigType" SG_ 2566765054 ReferenceTirePress_00 1;
BA_ "SPN" SG_ 2566765054 TireLocation 3190;
BA_ "SPN" SG_ 2633923326 SteerChannelTirePress 146;
BA_ "SigType" SG_ 2633923326 SteerChannelTirePress 1;
BA_ "SPN" SG_ 2633923326 DriveChannelTirePress 145;
BA_ "SigType" SG_ 2633923326 DriveChannelTirePress 1;
BA_ "SPN" SG_ 2633923326 TrailerTagOrPushChannelTirePress 144;
BA_ "SigType" SG_ 2633923326 TrailerTagOrPushChannelTirePress 1;
BA_ "SPN" SG_ 2633923070 SteerChannelTirePressTarget 143;
BA_ "SigType" SG_ 2633923070 SteerChannelTirePressTarget 1;
BA_ "SPN" SG_ 2633923070 DriveChannelTirePressTarget 142;
BA_ "SigType" SG_ 2633923070 DriveChannelTirePressTarget 1;
BA_ "SPN" SG_ 2633923070 TrlrTgOrPshChnnelTirePressTarget 141;
BA_ "SigType" SG_ 2633923070 TrlrTgOrPshChnnelTirePressTarget 1;
BA_ "SPN" SG_ 2633922814 PCUTrilerTagOrPushSolenoidStatus 1475;
BA_ "SigType" SG_ 2633922814 PCUTrilerTagOrPushSolenoidStatus 5;
BA_ "SPN" SG_ 2633922814 PCUSupplySolenoidStatus 1474;
BA_ "SigType" SG_ 2633922814 PCUSupplySolenoidStatus 5;
BA_ "SPN" SG_ 2633922814 PCUCtrlSolenoidStatus 1473;
BA_ "SigType" SG_ 2633922814 PCUCtrlSolenoidStatus 5;
BA_ "SPN" SG_ 2633922814 PCUDeflateSolenoidStatus 1472;
BA_ "SigType" SG_ 2633922814 PCUDeflateSolenoidStatus 5;
BA_ "SPN" SG_ 2633922814 TirePressSupplySwitchStatus 1471;
BA_ "SigType" SG_ 2633922814 TirePressSupplySwitchStatus 5;
BA_ "SPN" SG_ 2633922814 PCUSteerSolenoidStatus 1470;
BA_ "SigType" SG_ 2633922814 PCUSteerSolenoidStatus 5;
BA_ "SPN" SG_ 2633922814 PCUDriveSolenoidStatus 1469;
BA_ "SigType" SG_ 2633922814 PCUDriveSolenoidStatus 5;
BA_ "SPN" SG_ 2633922814 DriveChannelMode 1468;
BA_ "SPN" SG_ 2633922814 Trailer_tagChannelMode 1467;
BA_ "SPN" SG_ 2633922814 SteerChannelMode 1466;
BA_ "SPN" SG_ 2633922814 TirePressCheckInterval 39;
BA_ "SigType" SG_ 2633922814 TirePressCheckInterval 1;
BA_ "SPN" SG_ 2566845694 ExTirePressSupport 6990;
BA_ "SigType" SG_ 2566845694 ExTirePressSupport 4;
BA_ "SPN" SG_ 2566845694 TirePressThresholdDetection_13 521613;
BA_ "SPN" SG_ 2566845694 TirePressThresholdDetection_12 521612;
BA_ "SPN" SG_ 2566845694 TirePressThresholdDetection_11 521611;
BA_ "SPN" SG_ 2566845694 TirePressThresholdDetection_10 521610;
BA_ "SPN" SG_ 2566845694 TirePressThresholdDetection_01 521601;
BA_ "SPN" SG_ 2566845694 TirePress_33 521033;
BA_ "SigType" SG_ 2566845694 TirePress_33 1;
BA_ "SPN" SG_ 2566845694 TirePress_32 521032;
BA_ "SigType" SG_ 2566845694 TirePress_32 1;
BA_ "SPN" SG_ 2566845694 TirePress_31 521031;
BA_ "SigType" SG_ 2566845694 TirePress_31 1;
BA_ "SPN" SG_ 2566845694 TirePress_30 521030;
BA_ "SigType" SG_ 2566845694 TirePress_30 1;
BA_ "SPN" SG_ 2566845694 TirePress_23 521023;
BA_ "SigType" SG_ 2566845694 TirePress_23 1;
BA_ "SPN" SG_ 2566845694 TirePress_22 521022;
BA_ "SigType" SG_ 2566845694 TirePress_22 1;
BA_ "SPN" SG_ 2566845694 TirePress_21 521021;
BA_ "SigType" SG_ 2566845694 TirePress_21 1;
BA_ "SPN" SG_ 2566845694 TirePress_20 521020;
BA_ "SigType" SG_ 2566845694 TirePress_20 1;
BA_ "SPN" SG_ 2566845694 TirePress_13 521013;
BA_ "SigType" SG_ 2566845694 TirePress_13 1;
BA_ "SPN" SG_ 2566845694 TirePress_12 521012;
BA_ "SigType" SG_ 2566845694 TirePress_12 1;
BA_ "SPN" SG_ 2566845694 TirePress_11 521011;
BA_ "SigType" SG_ 2566845694 TirePress_11 1;
BA_ "SPN" SG_ 2566845694 TirePress_10 521010;
BA_ "SigType" SG_ 2566845694 TirePress_10 1;
BA_ "SPN" SG_ 2566845694 TireAirLeakageRate_33 521533;
BA_ "SigType" SG_ 2566845694 TireAirLeakageRate_33 1;
BA_ "SPN" SG_ 2566845694 TireAirLeakageRate_32 521532;
BA_ "SigType" SG_ 2566845694 TireAirLeakageRate_32 1;
BA_ "SPN" SG_ 2566845694 TireAirLeakageRate_31 521531;
BA_ "SigType" SG_ 2566845694 TireAirLeakageRate_31 1;
BA_ "SPN" SG_ 2566845694 TireAirLeakageRate_30 521530;
BA_ "SigType" SG_ 2566845694 TireAirLeakageRate_30 1;
BA_ "SPN" SG_ 2566845694 TireAirLeakageRate_23 521523;
BA_ "SigType" SG_ 2566845694 TireAirLeakageRate_23 1;
BA_ "SPN" SG_ 2566845694 TireAirLeakageRate_22 521522;
BA_ "SigType" SG_ 2566845694 TireAirLeakageRate_22 1;
BA_ "SPN" SG_ 2566845694 TireAirLeakageRate_21 521521;
BA_ "SigType" SG_ 2566845694 TireAirLeakageRate_21 1;
BA_ "SPN" SG_ 2566845694 TireAirLeakageRate_20 521520;
BA_ "SigType" SG_ 2566845694 TireAirLeakageRate_20 1;
BA_ "SPN" SG_ 2566845694 TireAirLeakageRate_13 521513;
BA_ "SigType" SG_ 2566845694 TireAirLeakageRate_13 1;
BA_ "SPN" SG_ 2566845694 TireAirLeakageRate_12 521512;
BA_ "SigType" SG_ 2566845694 TireAirLeakageRate_12 1;
BA_ "SPN" SG_ 2566845694 TireAirLeakageRate_11 521511;
BA_ "SigType" SG_ 2566845694 TireAirLeakageRate_11 1;
BA_ "SPN" SG_ 2566845694 TireAirLeakageRate_10 521510;
BA_ "SigType" SG_ 2566845694 TireAirLeakageRate_10 1;
BA_ "SPN" SG_ 2566845694 TireAirLeakageRate_01 521501;
BA_ "SigType" SG_ 2566845694 TireAirLeakageRate_01 1;
BA_ "SPN" SG_ 2566845694 TireAirLeakageRate_00 521500;
BA_ "SigType" SG_ 2566845694 TireAirLeakageRate_00 1;
BA_ "SPN" SG_ 2566845694 CTIWheelSensorStatus_33 521433;
BA_ "SigType" SG_ 2566845694 CTIWheelSensorStatus_33 4;
BA_ "SPN" SG_ 2566845694 CTIWheelSensorStatus_32 521432;
BA_ "SigType" SG_ 2566845694 CTIWheelSensorStatus_32 4;
BA_ "SPN" SG_ 2566845694 CTIWheelSensorStatus_31 521431;
BA_ "SigType" SG_ 2566845694 CTIWheelSensorStatus_31 4;
BA_ "SPN" SG_ 2566845694 CTIWheelSensorStatus_30 521430;
BA_ "SigType" SG_ 2566845694 CTIWheelSensorStatus_30 4;
BA_ "SPN" SG_ 2566845694 CTIWheelSensorStatus_23 521423;
BA_ "SigType" SG_ 2566845694 CTIWheelSensorStatus_23 4;
BA_ "SPN" SG_ 2566845694 CTIWheelSensorStatus_22 521422;
BA_ "SigType" SG_ 2566845694 CTIWheelSensorStatus_22 4;
BA_ "SPN" SG_ 2566845694 CTIWheelSensorStatus_21 521421;
BA_ "SigType" SG_ 2566845694 CTIWheelSensorStatus_21 4;
BA_ "SPN" SG_ 2566845694 CTIWheelSensorStatus_20 521420;
BA_ "SigType" SG_ 2566845694 CTIWheelSensorStatus_20 4;
BA_ "SPN" SG_ 2566845694 CTIWheelSensorStatus_13 521413;
BA_ "SigType" SG_ 2566845694 CTIWheelSensorStatus_13 4;
BA_ "SPN" SG_ 2566845694 CTIWheelSensorStatus_12 521412;
BA_ "SigType" SG_ 2566845694 CTIWheelSensorStatus_12 4;
BA_ "SPN" SG_ 2566845694 CTIWheelSensorStatus_11 521411;
BA_ "SigType" SG_ 2566845694 CTIWheelSensorStatus_11 4;
BA_ "SPN" SG_ 2566845694 CTIWheelSensorStatus_10 521410;
BA_ "SigType" SG_ 2566845694 CTIWheelSensorStatus_10 4;
BA_ "SPN" SG_ 2566845694 CTIWheelSensorStatus_01 521401;
BA_ "SigType" SG_ 2566845694 CTIWheelSensorStatus_01 4;
BA_ "SPN" SG_ 2566845694 CTIWheelEndElectricalFault_33 521233;
BA_ "SigType" SG_ 2566845694 CTIWheelEndElectricalFault_33 4;
BA_ "SPN" SG_ 2566845694 CTIWheelEndElectricalFault_32 521232;
BA_ "SigType" SG_ 2566845694 CTIWheelEndElectricalFault_32 4;
BA_ "SPN" SG_ 2566845694 CTIWheelEndElectricalFault_31 521231;
BA_ "SigType" SG_ 2566845694 CTIWheelEndElectricalFault_31 4;
BA_ "SPN" SG_ 2566845694 CTIWheelEndElectricalFault_30 521230;
BA_ "SigType" SG_ 2566845694 CTIWheelEndElectricalFault_30 4;
BA_ "SPN" SG_ 2566845694 CTIWheelEndElectricalFault_23 521223;
BA_ "SigType" SG_ 2566845694 CTIWheelEndElectricalFault_23 4;
BA_ "SPN" SG_ 2566845694 CTIWheelEndElectricalFault_22 521222;
BA_ "SigType" SG_ 2566845694 CTIWheelEndElectricalFault_22 4;
BA_ "SPN" SG_ 2566845694 CTIWheelEndElectricalFault_21 521221;
BA_ "SigType" SG_ 2566845694 CTIWheelEndElectricalFault_21 4;
BA_ "SPN" SG_ 2566845694 CTIWheelEndElectricalFault_20 521220;
BA_ "SigType" SG_ 2566845694 CTIWheelEndElectricalFault_20 4;
BA_ "SPN" SG_ 2566845694 CTIWheelEndElectricalFault_13 521213;
BA_ "SigType" SG_ 2566845694 CTIWheelEndElectricalFault_13 4;
BA_ "SPN" SG_ 2566845694 CTIWheelEndElectricalFault_12 521212;
BA_ "SigType" SG_ 2566845694 CTIWheelEndElectricalFault_12 4;
BA_ "SPN" SG_ 2566845694 CTIWheelEndElectricalFault_11 521211;
BA_ "SigType" SG_ 2566845694 CTIWheelEndElectricalFault_11 4;
BA_ "SPN" SG_ 2566845694 CTIWheelEndElectricalFault_10 521210;
BA_ "SigType" SG_ 2566845694 CTIWheelEndElectricalFault_10 4;
BA_ "SPN" SG_ 2566845694 CTIWheelEndElectricalFault_01 521201;
BA_ "SigType" SG_ 2566845694 CTIWheelEndElectricalFault_01 4;
BA_ "SPN" SG_ 2566845694 CTITireStatus_33 521333;
BA_ "SigType" SG_ 2566845694 CTITireStatus_33 4;
BA_ "SPN" SG_ 2566845694 CTITireStatus_32 521332;
BA_ "SigType" SG_ 2566845694 CTITireStatus_32 4;
BA_ "SPN" SG_ 2566845694 CTITireStatus_31 521331;
BA_ "SigType" SG_ 2566845694 CTITireStatus_31 4;
BA_ "SPN" SG_ 2566845694 CTITireStatus_30 521330;
BA_ "SigType" SG_ 2566845694 CTITireStatus_30 4;
BA_ "SPN" SG_ 2566845694 CTITireStatus_23 521323;
BA_ "SigType" SG_ 2566845694 CTITireStatus_23 4;
BA_ "SPN" SG_ 2566845694 CTITireStatus_22 521322;
BA_ "SigType" SG_ 2566845694 CTITireStatus_22 4;
BA_ "SPN" SG_ 2566845694 CTITireStatus_21 521321;
BA_ "SigType" SG_ 2566845694 CTITireStatus_21 4;
BA_ "SPN" SG_ 2566845694 CTITireStatus_20 521320;
BA_ "SigType" SG_ 2566845694 CTITireStatus_20 4;
BA_ "SPN" SG_ 2566845694 CTITireStatus_13 521313;
BA_ "SigType" SG_ 2566845694 CTITireStatus_13 4;
BA_ "SPN" SG_ 2566845694 CTITireStatus_12 521312;
BA_ "SigType" SG_ 2566845694 CTITireStatus_12 4;
BA_ "SPN" SG_ 2566845694 CTITireStatus_11 521311;
BA_ "SigType" SG_ 2566845694 CTITireStatus_11 4;
BA_ "SPN" SG_ 2566845694 CTITireStatus_10 521310;
BA_ "SigType" SG_ 2566845694 CTITireStatus_10 4;
BA_ "SPN" SG_ 2566845694 CTITireStatus_01 521301;
BA_ "SigType" SG_ 2566845694 CTITireStatus_01 4;
BA_ "SPN" SG_ 2566845694 TireTemp_11 521111;
BA_ "SigType" SG_ 2566845694 TireTemp_11 1;
BA_ "SPN" SG_ 2566845694 TireTemp_33 521133;
BA_ "SigType" SG_ 2566845694 TireTemp_33 1;
BA_ "SPN" SG_ 2566845694 TireTemp_32 521132;
BA_ "SigType" SG_ 2566845694 TireTemp_32 1;
BA_ "SPN" SG_ 2566845694 TireTemp_31 521131;
BA_ "SigType" SG_ 2566845694 TireTemp_31 1;
BA_ "SPN" SG_ 2566845694 TireTemp_30 521130;
BA_ "SigType" SG_ 2566845694 TireTemp_30 1;
BA_ "SPN" SG_ 2566845694 TireTemp_23 521123;
BA_ "SigType" SG_ 2566845694 TireTemp_23 1;
BA_ "SPN" SG_ 2566845694 TireTemp_22 521122;
BA_ "SigType" SG_ 2566845694 TireTemp_22 1;
BA_ "SPN" SG_ 2566845694 TireTemp_21 521121;
BA_ "SigType" SG_ 2566845694 TireTemp_21 1;
BA_ "SPN" SG_ 2566845694 TireTemp_20 521120;
BA_ "SigType" SG_ 2566845694 TireTemp_20 1;
BA_ "SPN" SG_ 2566845694 TireTemp_13 521113;
BA_ "SigType" SG_ 2566845694 TireTemp_13 1;
BA_ "SPN" SG_ 2566845694 TireTemp_12 521112;
BA_ "SigType" SG_ 2566845694 TireTemp_12 1;
BA_ "SPN" SG_ 2566845694 TireTemp_10 521110;
BA_ "SigType" SG_ 2566845694 TireTemp_10 1;
BA_ "SPN" SG_ 2566845694 TireTemp_01 521101;
BA_ "SigType" SG_ 2566845694 TireTemp_01 1;
BA_ "SPN" SG_ 2566845694 TireTemp_00 521100;
BA_ "SigType" SG_ 2566845694 TireTemp_00 1;
BA_ "SPN" SG_ 2566845694 TirePressThresholdDetection_33 521633;
BA_ "SPN" SG_ 2566845694 TirePressThresholdDetection_32 521632;
BA_ "SPN" SG_ 2566845694 TirePressThresholdDetection_31 521631;
BA_ "SPN" SG_ 2566845694 TirePressThresholdDetection_30 521630;
BA_ "SPN" SG_ 2566845694 TirePressThresholdDetection_23 521623;
BA_ "SPN" SG_ 2566845694 TirePressThresholdDetection_22 521622;
BA_ "SPN" SG_ 2566845694 TirePressThresholdDetection_21 521621;
BA_ "SPN" SG_ 2566845694 TirePressThresholdDetection_20 521620;
BA_ "SPN" SG_ 2566845694 TirePressThresholdDetection_00 521600;
BA_ "SPN" SG_ 2566845694 TirePress_01 521001;
BA_ "SigType" SG_ 2566845694 TirePress_01 1;
BA_ "SPN" SG_ 2566845694 TirePress_00 521000;
BA_ "SigType" SG_ 2566845694 TirePress_00 1;
BA_ "SPN" SG_ 2566845694 CTIWheelSensorStatus_00 521400;
BA_ "SigType" SG_ 2566845694 CTIWheelSensorStatus_00 4;
BA_ "SPN" SG_ 2566845694 CTIWheelEndElectricalFault_00 521200;
BA_ "SigType" SG_ 2566845694 CTIWheelEndElectricalFault_00 4;
BA_ "SPN" SG_ 2566845694 CTITireStatus_00 521300;
BA_ "SigType" SG_ 2566845694 CTITireStatus_00 4;
BA_ "SPN" SG_ 2566845694 TireLocation 929;
BA_ "SPN" SG_ 2633939966 TripFanOnTimeDueToTheA_CSystem 997;
BA_ "SigType" SG_ 2633939966 TripFanOnTimeDueToTheA_CSystem 1;
BA_ "SPN" SG_ 2633939966 TripFanOnTimeDueToAManualSwitch 996;
BA_ "SigType" SG_ 2633939966 TripFanOnTimeDueToAManualSwitch 1;
BA_ "SPN" SG_ 2633939966 TripFanOnTimeDueToTheEngSystem 995;
BA_ "SigType" SG_ 2633939966 TripFanOnTimeDueToTheEngSystem 1;
BA_ "SPN" SG_ 2633939966 TripFanOnTime 994;
BA_ "SigType" SG_ 2633939966 TripFanOnTime 1;
BA_ "SPN" SG_ 2633939710 TripDistanceInTopGear 1000;
BA_ "SigType" SG_ 2633939710 TripDistanceInTopGear 1;
BA_ "SPN" SG_ 2633939710 TripGearDownDistance 999;
BA_ "SigType" SG_ 2633939710 TripGearDownDistance 1;
BA_ "SPN" SG_ 2633939710 TripDistanceOnVSL 998;
BA_ "SigType" SG_ 2633939710 TripDistanceOnVSL 1;
BA_ "SPN" SG_ 2564161278 AdjustLocalHourOffset 1610;
BA_ "GenSigStartValue" SG_ 2564161278 AdjustLocalHourOffset 101;
BA_ "SigType" SG_ 2564161278 AdjustLocalHourOffset 1;
BA_ "SPN" SG_ 2564161278 AdjustLocalMinuteOffset 1609;
BA_ "GenSigStartValue" SG_ 2564161278 AdjustLocalMinuteOffset 66;
BA_ "SigType" SG_ 2564161278 AdjustLocalMinuteOffset 1;
BA_ "SPN" SG_ 2564161278 AdjustYear 1608;
BA_ "SigType" SG_ 2564161278 AdjustYear 1;
BA_ "SPN" SG_ 2564161278 AdjustDay 1607;
BA_ "GenSigStartValue" SG_ 2564161278 AdjustDay 1;
BA_ "SigType" SG_ 2564161278 AdjustDay 1;
BA_ "SPN" SG_ 2564161278 AdjustMonth 1606;
BA_ "GenSigStartValue" SG_ 2564161278 AdjustMonth 1;
BA_ "SigType" SG_ 2564161278 AdjustMonth 1;
BA_ "SPN" SG_ 2564161278 AdjustHours 1605;
BA_ "SigType" SG_ 2564161278 AdjustHours 1;
BA_ "SPN" SG_ 2564161278 AdjustMinutes 1604;
BA_ "SigType" SG_ 2564161278 AdjustMinutes 1;
BA_ "SPN" SG_ 2564161278 AdjustSeconds 1603;
BA_ "SigType" SG_ 2564161278 AdjustSeconds 1;
BA_ "SPN" SG_ 2566842110 LocalHourOffset 1602;
BA_ "GenSigStartValue" SG_ 2566842110 LocalHourOffset 102;
BA_ "SigType" SG_ 2566842110 LocalHourOffset 1;
BA_ "SPN" SG_ 2566842110 LocalMinuteOffset 1601;
BA_ "GenSigStartValue" SG_ 2566842110 LocalMinuteOffset 66;
BA_ "SigType" SG_ 2566842110 LocalMinuteOffset 1;
BA_ "SPN" SG_ 2566842110 Year 964;
BA_ "SigType" SG_ 2566842110 Year 1;
BA_ "SPN" SG_ 2566842110 Day 962;
BA_ "GenSigStartValue" SG_ 2566842110 Day 1;
BA_ "SigType" SG_ 2566842110 Day 1;
BA_ "SPN" SG_ 2566842110 Month 963;
BA_ "GenSigStartValue" SG_ 2566842110 Month 1;
BA_ "SigType" SG_ 2566842110 Month 1;
BA_ "SPN" SG_ 2566842110 Hours 961;
BA_ "SigType" SG_ 2566842110 Hours 1;
BA_ "SPN" SG_ 2566842110 Minutes 960;
BA_ "SigType" SG_ 2566842110 Minutes 1;
BA_ "SPN" SG_ 2566842110 Seconds 959;
BA_ "SigType" SG_ 2566842110 Seconds 1;
BA_ "SPN" SG_ 2566821630 EngDsrdTrboWastegateActuator2Pos 5373;
BA_ "SigType" SG_ 2566821630 EngDsrdTrboWastegateActuator2Pos 1;
BA_ "SPN" SG_ 2566821630 EngTrbWstgateActuator1TempStatus 5372;
BA_ "SPN" SG_ 2566821630 EngTrbWstgtActtor1PreliminaryFMI 5371;
BA_ "SPN" SG_ 2566821630 EngDsrdTrboWastegateActuator1Pos 5370;
BA_ "SigType" SG_ 2566821630 EngDsrdTrboWastegateActuator1Pos 1;
BA_ "SPN" SG_ 2566821630 EngTrbWstgteActuatorCtrlAirPress 1192;
BA_ "SigType" SG_ 2566821630 EngTrbWstgteActuatorCtrlAirPress 1;
BA_ "SPN" SG_ 2566821630 EngTurboWastegateActuator4Pos 1191;
BA_ "SigType" SG_ 2566821630 EngTurboWastegateActuator4Pos 1;
BA_ "SPN" SG_ 2566821630 EngTurboWastegateActuator3Pos 1190;
BA_ "SigType" SG_ 2566821630 EngTurboWastegateActuator3Pos 1;
BA_ "SPN" SG_ 2566821630 EngTurboWastegateActuator2Pos 1189;
BA_ "SigType" SG_ 2566821630 EngTurboWastegateActuator2Pos 1;
BA_ "SPN" SG_ 2566821630 EngTurboWastegateActuator1Pos 1188;
BA_ "SigType" SG_ 2566821630 EngTurboWastegateActuator1Pos 1;
BA_ "SPN" SG_ 2365484286 TachographVehicleSpeed 1624;
BA_ "SigType" SG_ 2365484286 TachographVehicleSpeed 1;
BA_ "SPN" SG_ 2365484286 TachographOutputShaftSpeed 1623;
BA_ "SigType" SG_ 2365484286 TachographOutputShaftSpeed 1;
BA_ "SPN" SG_ 2365484286 DirectionIndicator 1619;
BA_ "SigType" SG_ 2365484286 DirectionIndicator 4;
BA_ "SPN" SG_ 2365484286 TachographPerformance 1620;
BA_ "SigType" SG_ 2365484286 TachographPerformance 5;
BA_ "SPN" SG_ 2365484286 HandlingInformation 1621;
BA_ "SigType" SG_ 2365484286 HandlingInformation 5;
BA_ "SPN" SG_ 2365484286 SystemEvent 1622;
BA_ "SigType" SG_ 2365484286 SystemEvent 5;
BA_ "SPN" SG_ 2365484286 DriverCardDriver2 1616;
BA_ "SigType" SG_ 2365484286 DriverCardDriver2 4;
BA_ "SPN" SG_ 2365484286 Driver2TimeRelatedStates 1618;
BA_ "SPN" SG_ 2365484286 VehicleOverspeed 1614;
BA_ "SigType" SG_ 2365484286 VehicleOverspeed 4;
BA_ "SPN" SG_ 2365484286 DriverCardDriver1 1615;
BA_ "SigType" SG_ 2365484286 DriverCardDriver1 4;
BA_ "SPN" SG_ 2365484286 Driver1TimeRelatedStates 1617;
BA_ "SPN" SG_ 2365484286 VehicleMotion 1611;
BA_ "SigType" SG_ 2365484286 VehicleMotion 4;
BA_ "SPN" SG_ 2365484286 Driver2WorkingState 1613;
BA_ "SPN" SG_ 2365484286 Driver1WorkingState 1612;
BA_ "SPN" SG_ 2566771710 EngTurbo4CompressorOutletTemp 2801;
BA_ "SigType" SG_ 2566771710 EngTurbo4CompressorOutletTemp 1;
BA_ "SPN" SG_ 2566771710 EngTurbo3CompressorOutletTemp 2800;
BA_ "SigType" SG_ 2566771710 EngTurbo3CompressorOutletTemp 1;
BA_ "SPN" SG_ 2566771710 EngTurbo2CompressorOutletTemp 2799;
BA_ "SigType" SG_ 2566771710 EngTurbo2CompressorOutletTemp 1;
BA_ "SPN" SG_ 2566771710 EngTurbo1CompressorOutletTemp 2629;
BA_ "SigType" SG_ 2566771710 EngTurbo1CompressorOutletTemp 1;
BA_ "SPN" SG_ 2566821886 EngTurbo4TurbineOutletTemp 1187;
BA_ "SigType" SG_ 2566821886 EngTurbo4TurbineOutletTemp 1;
BA_ "SPN" SG_ 2566821886 EngTurbo3TurbineOutletTemp 1186;
BA_ "SigType" SG_ 2566821886 EngTurbo3TurbineOutletTemp 1;
BA_ "SPN" SG_ 2566821886 EngTurbo2TurbineOutletTemp 1185;
BA_ "SigType" SG_ 2566821886 EngTurbo2TurbineOutletTemp 1;
BA_ "SPN" SG_ 2566821886 EngTurbo1TurbineOutletTemp 1184;
BA_ "SigType" SG_ 2566821886 EngTurbo1TurbineOutletTemp 1;
BA_ "SPN" SG_ 2566822142 EngTurbo4TurbineIntakeTemp 1183;
BA_ "SigType" SG_ 2566822142 EngTurbo4TurbineIntakeTemp 1;
BA_ "SPN" SG_ 2566822142 EngTurbo3TurbineIntakeTemp 1182;
BA_ "SigType" SG_ 2566822142 EngTurbo3TurbineIntakeTemp 1;
BA_ "SPN" SG_ 2566822142 EngTurbo2TurbineIntakeTemp 1181;
BA_ "SigType" SG_ 2566822142 EngTurbo2TurbineIntakeTemp 1;
BA_ "SPN" SG_ 2566822142 EngTurbo1TurbineIntakeTemp 1180;
BA_ "SigType" SG_ 2566822142 EngTurbo1TurbineIntakeTemp 1;
BA_ "SPN" SG_ 2566822398 EngTurbo4CompressorIntakePress 1179;
BA_ "SigType" SG_ 2566822398 EngTurbo4CompressorIntakePress 1;
BA_ "SPN" SG_ 2566822398 EngTurbo3CompressorIntakePress 1178;
BA_ "SigType" SG_ 2566822398 EngTurbo3CompressorIntakePress 1;
BA_ "SPN" SG_ 2566822398 EngTurbo2CompressorIntakePress 1177;
BA_ "SigType" SG_ 2566822398 EngTurbo2CompressorIntakePress 1;
BA_ "SPN" SG_ 2566822398 EngTurbo1CompressorIntakePress 1176;
BA_ "SigType" SG_ 2566822398 EngTurbo1CompressorIntakePress 1;
BA_ "SPN" SG_ 2566822654 EngTurbo4CompressorIntakeTemp 1175;
BA_ "SigType" SG_ 2566822654 EngTurbo4CompressorIntakeTemp 1;
BA_ "SPN" SG_ 2566822654 EngTurbo3CompressorIntakeTemp 1174;
BA_ "SigType" SG_ 2566822654 EngTurbo3CompressorIntakeTemp 1;
BA_ "SPN" SG_ 2566822654 EngTurbo2CompressorIntakeTemp 1173;
BA_ "SigType" SG_ 2566822654 EngTurbo2CompressorIntakeTemp 1;
BA_ "SPN" SG_ 2566822654 EngTurbo1CompressorIntakeTemp 1172;
BA_ "SigType" SG_ 2566822654 EngTurbo1CompressorIntakeTemp 1;
BA_ "SPN" SG_ 2633931774 EngTurbo4Speed 1171;
BA_ "SigType" SG_ 2633931774 EngTurbo4Speed 1;
BA_ "SPN" SG_ 2633931774 EngTurbo3Speed 1170;
BA_ "SigType" SG_ 2633931774 EngTurbo3Speed 1;
BA_ "SPN" SG_ 2633931774 EngTurbo2Speed 1169;
BA_ "SigType" SG_ 2633931774 EngTurbo2Speed 1;
BA_ "SPN" SG_ 2633931774 EngTurboLubeOilPress2 1168;
BA_ "SigType" SG_ 2633931774 EngTurboLubeOilPress2 1;
BA_ "SPN" SG_ 2566802430 CommunicationsFailureIdleTrqLmt 7827;
BA_ "GenSigStartValue" SG_ 2566802430 CommunicationsFailureIdleTrqLmt 125;
BA_ "SigType" SG_ 2566802430 CommunicationsFailureIdleTrqLmt 1;
BA_ "SPN" SG_ 2566802430 ReferenceTrq 7778;
BA_ "SigType" SG_ 2566802430 ReferenceTrq 1;
BA_ "SPN" SG_ 2566802430 TransTorqueLimit 1845;
BA_ "SigType" SG_ 2566802430 TransTorqueLimit 1;
BA_ "SPN" SG_ 2566841086 TransGearRatio 581;
BA_ "SigType" SG_ 2566841086 TransGearRatio 1;
BA_ "SPN" SG_ 2566841086 NumberOfForwardGearRatios 957;
BA_ "SigType" SG_ 2566841086 NumberOfForwardGearRatios 1;
BA_ "SPN" SG_ 2566841086 NumberOfReverseGearRatios 958;
BA_ "SigType" SG_ 2566841086 NumberOfReverseGearRatios 1;
BA_ "SPN" SG_ 2348941054 AutoNeutralReq 7695;
BA_ "SigType" SG_ 2348941054 AutoNeutralReq 5;
BA_ "SPN" SG_ 2348941054 TransMode8 4249;
BA_ "SigType" SG_ 2348941054 TransMode8 5;
BA_ "SPN" SG_ 2348941054 TransMode7 4248;
BA_ "SigType" SG_ 2348941054 TransMode7 5;
BA_ "SPN" SG_ 2348941054 TransMode6 4247;
BA_ "SigType" SG_ 2348941054 TransMode6 5;
BA_ "SPN" SG_ 2348941054 TransMode5 4246;
BA_ "SigType" SG_ 2348941054 TransMode5 5;
BA_ "SPN" SG_ 2348941054 TrnsShftSlectorDisplayModeSwitch 2985;
BA_ "SigType" SG_ 2348941054 TrnsShftSlectorDisplayModeSwitch 4;
BA_ "SPN" SG_ 2348941054 TransRequestedLaunchGear 4255;
BA_ "SPN" SG_ 2348941054 TransMode4 1855;
BA_ "SigType" SG_ 2348941054 TransMode4 5;
BA_ "SPN" SG_ 2348941054 TransMode3 1854;
BA_ "SigType" SG_ 2348941054 TransMode3 5;
BA_ "SPN" SG_ 2348941054 TransMode2 1853;
BA_ "SigType" SG_ 2348941054 TransMode2 5;
BA_ "SPN" SG_ 2348941054 TransMode1 1852;
BA_ "SigType" SG_ 2348941054 TransMode1 5;
BA_ "SPN" SG_ 2348941054 TransLoadReductionInhibitRq 5762;
BA_ "SigType" SG_ 2348941054 TransLoadReductionInhibitRq 5;
BA_ "SPN" SG_ 2348941054 DisengageDiffLockRqCentralRear 691;
BA_ "SigType" SG_ 2348941054 DisengageDiffLockRqCentralRear 5;
BA_ "SPN" SG_ 2348941054 DisengageDiffLockRqCentralFront 690;
BA_ "SigType" SG_ 2348941054 DisengageDiffLockRqCentralFront 5;
BA_ "SPN" SG_ 2348941054 DisengageDiffLockRqCentral 689;
BA_ "SigType" SG_ 2348941054 DisengageDiffLockRqCentral 5;
BA_ "SPN" SG_ 2348941054 DisengageDiffLockRqRearAxle2 688;
BA_ "SigType" SG_ 2348941054 DisengageDiffLockRqRearAxle2 5;
BA_ "SPN" SG_ 2348941054 DisengageDiffLockRqRearAxle1 687;
BA_ "SigType" SG_ 2348941054 DisengageDiffLockRqRearAxle1 5;
BA_ "SPN" SG_ 2348941054 DisengageDiffLockRqFrontAxle2 686;
BA_ "SigType" SG_ 2348941054 DisengageDiffLockRqFrontAxle2 5;
BA_ "SPN" SG_ 2348941054 DisengageDiffLockRqFrontAxle1 685;
BA_ "SigType" SG_ 2348941054 DisengageDiffLockRqFrontAxle1 5;
BA_ "SPN" SG_ 2348941054 TransRequestedGear 525;
BA_ "GenSigStartValue" SG_ 2348941054 TransRequestedGear 61;
BA_ "SigType" SG_ 2348941054 TransRequestedGear 1;
BA_ "SPN" SG_ 2348941054 RequestedPercentClutchSlip 684;
BA_ "SigType" SG_ 2348941054 RequestedPercentClutchSlip 1;
BA_ "SPN" SG_ 2348941054 TransReverseGearShiftInhibitRq 4242;
BA_ "SigType" SG_ 2348941054 TransReverseGearShiftInhibitRq 5;
BA_ "SPN" SG_ 2348941054 DisengageDrivelineRq 683;
BA_ "SigType" SG_ 2348941054 DisengageDrivelineRq 5;
BA_ "SPN" SG_ 2348941054 TrnsTrqeConverterLockupDisableRq 682;
BA_ "SigType" SG_ 2348941054 TrnsTrqeConverterLockupDisableRq 5;
BA_ "SPN" SG_ 2348941054 TransGearShiftInhibitRq 681;
BA_ "SigType" SG_ 2348941054 TransGearShiftInhibitRq 5;
BA_ "SPN" SG_ 2566839806 EngTurboOilLevelSwitch 1665;
BA_ "SigType" SG_ 2566839806 EngTurboOilLevelSwitch 4;
BA_ "SPN" SG_ 2566839806 EngTurbo1Speed 103;
BA_ "SigType" SG_ 2566839806 EngTurbo1Speed 1;
BA_ "SPN" SG_ 2566839806 EngTurboLubeOilPress1 104;
BA_ "SigType" SG_ 2566839806 EngTurboLubeOilPress1 1;
BA_ "SPN" SG_ 2566839806 EngTurboDiffSpeed 5980;
BA_ "SigType" SG_ 2566839806 EngTurboDiffSpeed 1;
BA_ "SPN" SG_ 2633911806 EngTotalAverageFuelEconomy 1835;
BA_ "SigType" SG_ 2633911806 EngTotalAverageFuelEconomy 1;
BA_ "SPN" SG_ 2633911806 EngTotalAverageFuelRate 1834;
BA_ "SigType" SG_ 2633911806 EngTotalAverageFuelRate 1;
BA_ "SPN" SG_ 2566775550 PwertrainCircuitAirSupplyPressRq 6306;
BA_ "SigType" SG_ 2566775550 PwertrainCircuitAirSupplyPressRq 1;
BA_ "SPN" SG_ 2566775550 AirSuspensionSupplyPressRq 2608;
BA_ "SigType" SG_ 2566775550 AirSuspensionSupplyPressRq 1;
BA_ "SPN" SG_ 2566775550 AuxEquipmentSupplyPressRq 2607;
BA_ "SigType" SG_ 2566775550 AuxEquipmentSupplyPressRq 1;
BA_ "SPN" SG_ 2566775550 ServiceBrakeAirPressRqCircuit2 2606;
BA_ "SigType" SG_ 2566775550 ServiceBrakeAirPressRqCircuit2 1;
BA_ "SPN" SG_ 2566775550 ServiceBrakeAirPressRqCircuit1 2605;
BA_ "SigType" SG_ 2566775550 ServiceBrakeAirPressRqCircuit1 1;
BA_ "SPN" SG_ 2566775550 ParkingAnd_orTrailerAirPressRq 2604;
BA_ "SigType" SG_ 2566775550 ParkingAnd_orTrailerAirPressRq 1;
BA_ "SPN" SG_ 2566775550 PneumaticSupplyPressRq 2603;
BA_ "SigType" SG_ 2566775550 PneumaticSupplyPressRq 1;
BA_ "SPN" SG_ 2566819838 EngExtlShutdownAirSupplyPress 1320;
BA_ "SigType" SG_ 2566819838 EngExtlShutdownAirSupplyPress 1;
BA_ "SPN" SG_ 2566839038 NmbrOfSftwreIdentificationFields 965;
BA_ "SigType" SG_ 2566839038 NmbrOfSftwreIdentificationFields 1;
BA_ "SPN" SG_ 2566839038 SoftwareIdentification 234;
BA_ "SigType" SG_ 2566839038 SoftwareIdentification 8;
BA_ "SPN" SG_ 2566841598 EngOilPressSw 8159;
BA_ "SigType" SG_ 2566841598 EngOilPressSw 4;
BA_ "SPN" SG_ 2566841598 ClntLvlEngPrtctionShutdownStatus 5566;
BA_ "SigType" SG_ 2566841598 ClntLvlEngPrtctionShutdownStatus 5;
BA_ "SPN" SG_ 2566841598 PTOShutdownHasShutdownEng 5404;
BA_ "SigType" SG_ 2566841598 PTOShutdownHasShutdownEng 5;
BA_ "SPN" SG_ 2566841598 EngAirShutoffStatus 3667;
BA_ "SigType" SG_ 2566841598 EngAirShutoffStatus 5;
BA_ "SPN" SG_ 2566841598 EngOverspeedTest 2812;
BA_ "SigType" SG_ 2566841598 EngOverspeedTest 4;
BA_ "SPN" SG_ 2566841598 EngAirShutoffCmdStatus 2813;
BA_ "SigType" SG_ 2566841598 EngAirShutoffCmdStatus 5;
BA_ "SPN" SG_ 2566841598 EngAlarmOutputCmdStatus 2814;
BA_ "SigType" SG_ 2566841598 EngAlarmOutputCmdStatus 5;
BA_ "SPN" SG_ 2566841598 EngAlarmAcknowledge 2815;
BA_ "SigType" SG_ 2566841598 EngAlarmAcknowledge 4;
BA_ "SPN" SG_ 2566841598 EngProtectionSystemConfig 1111;
BA_ "SigType" SG_ 2566841598 EngProtectionSystemConfig 5;
BA_ "SPN" SG_ 2566841598 EngProtectionSystemTimerState 1107;
BA_ "SigType" SG_ 2566841598 EngProtectionSystemTimerState 5;
BA_ "SPN" SG_ 2566841598 EngProtectionSystemTimerOverride 1108;
BA_ "SigType" SG_ 2566841598 EngProtectionSystemTimerOverride 5;
BA_ "SPN" SG_ 2566841598 EngPrtctnSystmApprachingShutdown 1109;
BA_ "SigType" SG_ 2566841598 EngPrtctnSystmApprachingShutdown 5;
BA_ "SPN" SG_ 2566841598 EngPrtectionSystemHasShutdownEng 1110;
BA_ "SigType" SG_ 2566841598 EngPrtectionSystemHasShutdownEng 5;
BA_ "SPN" SG_ 2566841598 EngWaitToStartLamp 1081;
BA_ "SigType" SG_ 2566841598 EngWaitToStartLamp 5;
BA_ "SPN" SG_ 2566841598 RefrigerantHighPressSwitch 605;
BA_ "SigType" SG_ 2566841598 RefrigerantHighPressSwitch 4;
BA_ "SPN" SG_ 2566841598 RefrigerantLowPressSwitch 875;
BA_ "SigType" SG_ 2566841598 RefrigerantLowPressSwitch 4;
BA_ "SPN" SG_ 2566841598 A_CHighPressFanSwitch 985;
BA_ "SigType" SG_ 2566841598 A_CHighPressFanSwitch 4;
BA_ "SPN" SG_ 2566841598 EngIdleShutdownTimerFunction 591;
BA_ "SigType" SG_ 2566841598 EngIdleShutdownTimerFunction 4;
BA_ "SPN" SG_ 2566841598 EngIdleShutdownTimerState 590;
BA_ "SigType" SG_ 2566841598 EngIdleShutdownTimerState 5;
BA_ "SPN" SG_ 2566841598 EngIdleShutdownTimerOverride 592;
BA_ "SigType" SG_ 2566841598 EngIdleShutdownTimerOverride 5;
BA_ "SPN" SG_ 2566841598 EngIdleShutdownDriverAlertMode 594;
BA_ "SigType" SG_ 2566841598 EngIdleShutdownDriverAlertMode 5;
BA_ "SPN" SG_ 2566841598 EngIdleShutdownHasShutdownEng 593;
BA_ "SigType" SG_ 2566841598 EngIdleShutdownHasShutdownEng 5;
VAL_ 2566807294 TyrePressThresholdDetect 7 "Not available" 6 "Error indicator" 5 "Not defined" 4 "Extreme under pressure" 3 "Under pressure" 2 "No warning pressure" 1 "Over pressure" 0 "Extreme over pressure" ;
VAL_ 2566807294 TyreModulePowerSupply 1 "Sufficient power supply" 0 "Insufficient power supply" ;
VAL_ 2566807294 TyreWheelIdentification2 15 "Axle position 15" 14 "Axle position 14" 13 "Axle position 13" 12 "Axle position 12" 11 "Axle position 11" 10 "Axle position 10" 9 "Axle position 9" 8 "Axle position 8" 7 "Axle position 7" 6 "Axle position 6" 5 "Axle position 5" 4 "Axle position 4" 3 "Axle position 3" 2 "Axle position 2" 1 "Axle position 1" 0 "Axle position not identified" ;
VAL_ 2566807294 TyreWheelIdentification1 15 "Wheel position 15" 14 "Wheel position 14" 13 "Wheel position 13" 12 "Wheel position 12" 11 "Wheel position 11" 10 "Wheel position 10" 9 "Wheel position 9" 8 "Wheel position 8" 7 "Wheel position 7" 6 "Wheel position 6" 5 "Wheel position 5" 4 "Wheel position 4" 3 "Wheel position 3" 2 "Wheel position 2" 1 "Wheel position 1" 0 "Wheel position not identified" ;
VAL_ 2566764798 MisfireMonitoringComplete 1 "EnabledForCycle" 0 "DisabledForRestOfCycle" ;
VAL_ 2566764798 MisfireMonitoringEnabled 1 "EnabledForCycle" 0 "DisabledForRestOfCycle" ;
VAL_ 2566764798 FuelSystemMonitoringEnabled 1 "NotCompleteCycle" 0 "CompleteCycleOrNotSupported" ;
VAL_ 2566764798 ComprehensiveComptMonComplete 1 "NotCompleteCycle" 0 "CompleteCycleOrNotSupported" ;
VAL_ 2566764798 ComprehensiveCompMonEnabled 1 "NotCompleteCycle" 0 "CompleteCycleOrNotSupported" ;
VAL_ 2566764798 SecondAirSystemMonComplete 1 "EnabledForCycle" 0 "DisabledForRestOfCycle" ;
VAL_ 2566764798 SecondAirSystemMonEnabled 1 "EnabledForCycle" 0 "DisabledForRestOfCycle" ;
VAL_ 2566764798 OxygenSensorMonComplete 1 "EnabledForCycle" 0 "DisabledForRestOfCycle" ;
VAL_ 2566764798 OxygenSensorMonEnabled 1 "NotCompleteCycle" 0 "CompleteCycleOrNotSupported" ;
VAL_ 2566764798 OxygenSensorHeaterMonComplete 1 "EnabledForCycle" 0 "DisabledForRestOfCycle" ;
VAL_ 2566764798 OxygenSensorHeaterMonEnabled 1 "NotCompleteCycle" 0 "CompleteCycleOrNotSupported" ;
VAL_ 2566764798 HeatedCatalystMonComplete 1 "EnabledForCycle" 0 "DisabledForRestOfCycle" ;
VAL_ 2566764798 HeatedCatalystMonEnabled 1 "EnabledForCycle" 0 "DisabledForRestOfCycle" ;
VAL_ 2566764798 EvaporativeSystemMonComplete 1 "NotCompleteCycle" 0 "CompleteCycleOrNotSupported" ;
VAL_ 2566764798 EvaporativeSystemMonEnabled 1 "NotCompleteCycle" 0 "CompleteCycleOrNotSupported" ;
VAL_ 2566764798 EGRSystemMonitoringComplete 1 "NotCompleteCycle" 0 "CompleteCycleOrNotSupported" ;
VAL_ 2566764798 EGRSystemMonitoringEnabled 1 "EnabledForCycle" 0 "DisabledForRestOfCycle" ;
VAL_ 2566764798 ColdStartAidSystemMonComplete 1 "EnabledForCycle" 0 "DisabledForRestOfCycle" ;
VAL_ 2566764798 ColdStartAidSystemMonEnabled 1 "EnabledForCycle" 0 "DisabledForRestOfCycle" ;
VAL_ 2566764798 CatalystMonComplete 1 "NotCompleteCycle" 0 "CompleteCycleOrNotSupported" ;
VAL_ 2566764798 CatalystMonEnabled 1 "NotCompleteCycle" 0 "CompleteCycleOrNotSupported" ;
VAL_ 2566764798 ACSystemRefrigerantMonComplete 1 "NotCompleteCycle" 0 "CompleteCycleOrNotSupported" ;
VAL_ 2566764798 ACSystemRefrigerantMonEnabled 1 "NotCompleteCycle" 0 "CompleteCycleOrNotSupported" ;
VAL_ 2566764798 FuelSystemMonitoringComplete 1 "NotCompleteCycle" 0 "CompleteCycleOrNotSupported" ;
VAL_ 2564095742 SecurityEntityType 3 "Data is Certificate" 2 "Data is Session Key" 1 "Data is Long Key" 0 "Data is Long Seed" ;
VAL_ 2349137662 XBRCtrlMode 3 "Not defined" 2 "Acceleration control with maximum mode" 1 "Acceleration control with addition mode" 0 "Override disabled" ;
VAL_ 2349137662 XBRPriority 3 "Low priority" 2 "Medium priority" 1 "High priority" 0 "Highest priority" ;
VAL_ 2349137662 XBREBIMode 3 "Not defined" 2 "Endurance Brake Integration allowed" 1 "Only Endurance Brakes allowed" 0 "No Endurance Brake Integration allowed" ;
VAL_ 2566848510 AutoStartReqInhInd 3 "Take no action" 2 "Active, flashing)" 1 "Active, on continuously)" 0 "Inactive" ;
VAL_ 2566848510 WaterInChargeADAfterChargeACInd 3 "Not available" 2 "Error" 1 "Yes" 0 "No" ;
VAL_ 2566848510 EngOverloadedInd 0 "No" 3 "Not available" 2 "Error" 1 "Yes" ;
VAL_ 2566848510 EmssnCtrlSystmOprtrIndcmntSvrity 7 "Not Available / Not Supported" 6 "Temporary Override of Inducement" 5 "Inducement Level 5 .." 4 "Inducement Level 4 .." 3 "Inducement Level 3 .." 2 "Inducement Level 2 .." 1 "Inducement Level 1.." 0 "Driver Warning" ;
VAL_ 2566848510 DrvrWarningSystemIndicatorStatus 7 "not available" 6 "reserved for SAE assignment" 5 "reserved for SAE assignment" 4 "On, fast blink" 3 "reserved for SAE assignment" 2 "reserved for SAE assignment" 1 "On, solid" 0 "Off" ;
VAL_ 2566848510 OperatorShiftPrompt 3 "don't care/take no action" 2 "downshift indicator active" 1 "upshift indicator active" 0 "indicator(s) inactive" ;
VAL_ 2566848510 WaterInFuelIndicator 3 "Not available" 2 "Error" 1 "Yes" 0 "No" ;
VAL_ 2566848510 WaterInFuelIndicator2 3 "Not available" 2 "Error" 1 "Yes" 0 "No" ;
VAL_ 2566843134 AxleLocation 48 "Axle3_Position0" 32 "Axle2_Position0" 16 "Axle1_Position0" 0 "Axle0_Position0" ;
VAL_ 2566809854 WinchOilPressSwitch 3 "Not Available" 2 "Error" 1 "OK" 0 "NOT OK- Oil pressure is too low" ;
VAL_ 2566809854 HydOilFilterRestrictionSwitch 3 "Not Available" 2 "Error" 1 "Restriction exists on oil filter" 0 "No restriction" ;
VAL_ 2565868030 SteerWheelAngleSensorType 3 "Not Available" 2 "Reserved" 1 "Absolute measuring principle" 0 "Relative measuring principle" ;
VAL_ 2566803454 TrailerVDCActive 3 "Not availble or not installed" 2 "Reserved" 1 "VDC active" 0 "VDC passive" ;
VAL_ 2566803454 YCBrakeCtrlActive 3 "Don't care/Take no action" 2 "Reserved" 1 "YC brake control active" 0 "YC brake control passive but installed" ;
VAL_ 2566803454 YCEngCtrlActive 3 "Don't care/Take no action" 2 "Reserved" 1 "YC engine control active" 0 "YC engine control passive but installed" ;
VAL_ 2566803454 ROPBrakeCtrlActive 3 "Don't care/Take no action" 2 "Reserved" 1 "ROP brake control active" 0 "ROP brake control passive but installed" ;
VAL_ 2566803454 ROPEngCtrlActive 3 "Don't care/Take no action" 2 "Reserved" 1 "ROP engine control active" 0 "ROP engine control passive but installed" ;
VAL_ 2566803454 VDCBrakeLightRq 3 "Don't care/Take no action" 2 "Reserved" 1 "Turn brake light on" 0 "Turn brake light not on" ;
VAL_ 2566803454 VDCFullyOperational 3 "Don't care/Take no action" 2 "Reserved" 1 "Fully operational" 0 "Not fully operational" ;
VAL_ 2566803454 VDCInformationSignal 3 "Don't care/Take no action" 2 "Reserved" 1 "On" 0 "Off" ;
VAL_ 2348875518 EngRequestedTorqueHighResolution 7 "+0.875%" 1 "+0.125%" 0 "+0.000%" ;
VAL_ 2348875518 TSC1CtrlPurpose 31 "P32 = Temporary Power Train Control" 5 "P6 = Transient-Optimized Torque Limit" 4 "P5 = Engine Protection" 3 "P4 = Road Speed Governor" 2 "P3 = PTO Governor" 1 "P2 = Cruise Control" 0 "P1 = Accelerator Pedal/Operator Selection" ;
VAL_ 2348875518 TSC1TransRate 4 "100 ms transmission rate" 3 "250 ms transmission rate" 2 "500 ms transmission rate" 1 "750 ms transmission rate" 0 "1000 ms transmission rate" 7 "Use standard TSC1 transmission rates of 10 ms to engine" 6 "20 ms transmission rate" 5 "50 ms transmission rate" ;
VAL_ 2348875518 OverrideCtrlModePriority 3 "Low priority" 2 "Medium priority" 1 "High priority" 0 "Highest priority" ;
VAL_ 2348875518 EngRequestedSpeedCtrlConditions 3 "Stability Optimized for driveline engaged and/or in lockup condition 2" 2 "Stability Optimized for driveline engaged and/or in lockup condition 1" 1 "Stability Optimized for driveline disengaged and non-lockup conditions" 0 "Transient Optimized for driveline disengaged and non-lockup conditions" ;
VAL_ 2348875518 EngOverrideCtrlMode 3 "Speed/torque limit control" 2 "Torque control" 1 "Speed control" 0 "Override disabled" ;
VAL_ 2566766846 TransitRunStatus 3 "Not available" 2 "Error condition" 0 "Off" ;
VAL_ 2566766846 VehicleUseStatus 3 "Not available" 2 "Error condition" 1 "Unauthorized use" 0 "Normal use" ;
VAL_ 2566766846 SilentAlarmStatus 3 "Not available" 2 "Error condition" 1 "On" 0 "Off" ;
VAL_ 2566766846 TypeOfPassengerCount 255 "not available" 254 "error indicator" 4 "exiting passenger, second passenger stream)" 3 "boarding passenger, second passenger stream)" 2 "exiting passenger" 1 "boarding passenger" 0 "absolute passenger count" ;
VAL_ 2566765310 FareboxAlarmIdentifier 5 "Cashbox restored" 4 "Cashbox removed" 3 "Probe completed" 2 "Probe started" 1 "Voltage restored" 0 "Voltage dropout" 25 "Maintenance access out of service" 24 "Maintenance access in service" 23 "Paper currency jam cleared" 22 "Paper currency jam" 21 "Pass/transfer jam cleared" 20 "Pass/transfer jam" 19 "Farebox reset to automatic mode" 18 "Farebox set in manual bypass" 17 "Coin de-jam operated" 16 "Card/pass box full" 15 "Card/pass box less than 75% full" 14 "Card/pass box 75% full" 13 "Currency box full" 12 "Currency box less than 75% full" 11 "Currency box 75% full" 10 "Coinbox full" 9 "Coinbox 75% full" 8 "Insufficient fare accepted" 7 "Cashbox opened in service" 6 "Cashbox door timeout" ;
VAL_ 2566765310 FareboxEmergencyStatus 3 "Not available" 2 "Error Condition" 1 "Emergency condition" 0 "Non-emergency condition" ;
VAL_ 2566765566 TransferType 5 "Out" 4 "In" 3 "West" 2 "East" 1 "South" 0 "North" ;
VAL_ 2566765566 TypeOfService 1 "Express service" 0 "Local service" ;
VAL_ 2566765566 PaymentDetails 5 "Card" 4 "Pass" 3 "Ticket" 2 "Token" 1 "Cash" 0 "Not an upgrade" ;
VAL_ 2566765566 TypeOfFare 6 "Pass B" 5 "Pass A" 4 "Ticket B" 3 "Ticket A" 2 "Token B" 1 "Token A" 0 "Cash/No detail" ;
VAL_ 2566765566 TransactionType 7 "Free" 6 "Transfer" 5 "Permit" 4 "Card" 3 "Pass" 2 "Ticket" 1 "Token" 0 "Cash" ;
VAL_ 2566765822 TripDirection 5 "Out" 4 "In" 3 "West" 2 "East" 1 "South" 0 "North" ;
VAL_ 2566765822 TripStatus 7 "Undefined" 6 "Layover end" 5 "Layover start" 4 "Undefined" 3 "Undefined" 2 "Trip end" 1 "Trip start" 0 "Undefined" ;
VAL_ 2566765822 FareboxServiceStatus 3 "Not available" 2 "Error Condition" 1 "Farebox in service" 0 "Farebox out of service" ;
VAL_ 2566766078 StrobeActivationCtrlStatus 3 "Not available" 2 "Error condition" 1 "Activate strobe" 0 "Deactivate strobe" ;
VAL_ 2566766078 TransitDoorEnable 3 "Not available" 2 "Error condition" 1 "Transit door status will override strobe activation" 0 "Ignore transit door status" ;
VAL_ 2566766078 PriorityOfRespSentByEmitter 15 "Not available" 14 "Error condition" 11 "Priority set by hardware to high priority" 10 "Priority set by hardware to probe priority" 9 "Priority set by hardware to low priority" 3 "High priority" 2 "Probe priority" 1 "Low priority" 0 "Reserved" ;
VAL_ 2566766078 IntrsctnPrmptionRequest_Response 3 "Not available" 2 "Error condition" 1 "Message is a response from the emitter" 0 "Message is a request directed to the emitter" ;
VAL_ 2566766078 TransitRouteIDUsage 3 "Not available" 2 "Error condition" 1 "Transit route ID used for interleaved data" 0 "Transit route ID not used for interleaved data" ;
VAL_ 2566766078 RangeCodeEnable 3 "Not available" 2 "Error condition" 1 "Range code used for interleaved data" 0 "Range code not used for interleaved data" ;
VAL_ 2561605374 TireLocation 51 "Axle3_Position3" 50 "Axle3_Position2" 49 "Axle3_Position1" 35 "Axle2_Position3" 34 "Axle2_Position2" 33 "Axle2_Position1" 19 "Axle1_Position3" 18 "Axle1_Position2" 17 "Axle1_Position1" 1 "Axle0_Position1" 48 "Axle3_Position0" 32 "Axle2_Position0" 16 "Axle1_Position0" 0 "Axle0_Position0" ;
VAL_ 2566765054 TireLocation 51 "Axle3_Position3" 50 "Axle3_Position2" 49 "Axle3_Position1" 35 "Axle2_Position3" 34 "Axle2_Position2" 33 "Axle2_Position1" 19 "Axle1_Position3" 18 "Axle1_Position2" 17 "Axle1_Position1" 1 "Axle0_Position1" 48 "Axle3_Position0" 32 "Axle2_Position0" 16 "Axle1_Position0" 0 "Axle0_Position0" ;
VAL_ 2633922814 PCUTrilerTagOrPushSolenoidStatus 3 "Not available" 2 "Error" 1 "On" 0 "Off" ;
VAL_ 2633922814 PCUSupplySolenoidStatus 3 "Not available" 2 "Error" 1 "On" 0 "Off" ;
VAL_ 2633922814 PCUCtrlSolenoidStatus 3 "Not available" 2 "Error" 1 "On" 0 "Off" ;
VAL_ 2633922814 PCUDeflateSolenoidStatus 3 "Not available" 2 "Error" 1 "On" 0 "Off" ;
VAL_ 2633922814 TirePressSupplySwitchStatus 3 "Not available" 2 "Error" 1 "On" 0 "Off" ;
VAL_ 2633922814 PCUSteerSolenoidStatus 3 "Not available" 2 "Error" 1 "On" 0 "Off" ;
VAL_ 2633922814 PCUDriveSolenoidStatus 3 "Not available" 2 "Error" 1 "On" 0 "Off" ;
VAL_ 2633922814 DriveChannelMode 15 "Not available" 14 "Error Condition" 6 "Pressure Check" 5 "Deflate Wait" 4 "Inflate Wait" 3 "Confirm" 2 "Deflate" 1 "Inflate" 0 "Maintain" ;
VAL_ 2633922814 Trailer_tagChannelMode 15 "Not available" 14 "Error Condition" 6 "Pressure Check" 5 "Deflate Wait" 4 "Inflate Wait" 3 "Confirm" 2 "Deflate" 1 "Inflate" 0 "Maintain" ;
VAL_ 2633922814 SteerChannelMode 1 "Inflate" 0 "Maintain" 15 "Not available" 14 "Error Condition" 6 "Pressure Check" 5 "Deflate Wait" 4 "Inflate Wait" 3 "Confirm" 2 "Deflate" ;
VAL_ 2566845694 ExTirePressSupport 3 "Not Available/Not Supported" 2 "Error" 1 "Using Extended Tire Pressure" 0 "Not Using Extended Tire Pressure" ;
VAL_ 2566845694 TirePressThresholdDetection_13 7 "NotAvailable" 6 "ErrorIndicator" 5 "NotDefined" 4 "ExtrmUndrPrssTrPrssrIsAtALvlWhr" 3 "UndrPrssTrPrssrIsLwrThnThPrssrD" 2 "NWrnngPrssTrPrssrIsWthnThThrshl" 1 "OvrPrssTrPrssrIsHghrThnThPrssrD" 0 "ExtrmOvrPrssTrPrssrIsAtALvlWhrT" ;
VAL_ 2566845694 TirePressThresholdDetection_12 7 "NotAvailable" 6 "ErrorIndicator" 5 "NotDefined" 4 "ExtrmUndrPrssTrPrssrIsAtALvlWhr" 3 "UndrPrssTrPrssrIsLwrThnThPrssrD" 2 "NWrnngPrssTrPrssrIsWthnThThrshl" 1 "OvrPrssTrPrssrIsHghrThnThPrssrD" 0 "ExtrmOvrPrssTrPrssrIsAtALvlWhrT" ;
VAL_ 2566845694 TirePressThresholdDetection_11 7 "NotAvailable" 6 "ErrorIndicator" 5 "NotDefined" 4 "ExtrmUndrPrssTrPrssrIsAtALvlWhr" 3 "UndrPrssTrPrssrIsLwrThnThPrssrD" 2 "NWrnngPrssTrPrssrIsWthnThThrshl" 1 "OvrPrssTrPrssrIsHghrThnThPrssrD" 0 "ExtrmOvrPrssTrPrssrIsAtALvlWhrT" ;
VAL_ 2566845694 TirePressThresholdDetection_10 7 "NotAvailable" 6 "ErrorIndicator" 5 "NotDefined" 4 "ExtrmUndrPrssTrPrssrIsAtALvlWhr" 3 "UndrPrssTrPrssrIsLwrThnThPrssrD" 2 "NWrnngPrssTrPrssrIsWthnThThrshl" 1 "OvrPrssTrPrssrIsHghrThnThPrssrD" 0 "ExtrmOvrPrssTrPrssrIsAtALvlWhrT" ;
VAL_ 2566845694 TirePressThresholdDetection_01 7 "NotAvailable" 6 "ErrorIndicator" 5 "NotDefined" 4 "ExtrmUndrPrssTrPrssrIsAtALvlWhr" 3 "UndrPrssTrPrssrIsLwrThnThPrssrD" 2 "NWrnngPrssTrPrssrIsWthnThThrshl" 1 "OvrPrssTrPrssrIsHghrThnThPrssrD" 0 "ExtrmOvrPrssTrPrssrIsAtALvlWhrT" ;
VAL_ 2566845694 CTIWheelSensorStatus_33 3 "NotSupported" 2 "NotDefined" 1 "On" 0 "Off_IsolatedFromCTIPressCtrl" ;
VAL_ 2566845694 CTIWheelSensorStatus_32 3 "NotSupported" 2 "NotDefined" 1 "On" 0 "Off_IsolatedFromCTIPressCtrl" ;
VAL_ 2566845694 CTIWheelSensorStatus_31 3 "NotSupported" 2 "NotDefined" 1 "On" 0 "Off_IsolatedFromCTIPressCtrl" ;
VAL_ 2566845694 CTIWheelSensorStatus_30 3 "NotSupported" 2 "NotDefined" 1 "On" 0 "Off_IsolatedFromCTIPressCtrl" ;
VAL_ 2566845694 CTIWheelSensorStatus_23 3 "NotSupported" 2 "NotDefined" 1 "On" 0 "Off_IsolatedFromCTIPressCtrl" ;
VAL_ 2566845694 CTIWheelSensorStatus_22 3 "NotSupported" 2 "NotDefined" 1 "On" 0 "Off_IsolatedFromCTIPressCtrl" ;
VAL_ 2566845694 CTIWheelSensorStatus_21 3 "NotSupported" 2 "NotDefined" 1 "On" 0 "Off_IsolatedFromCTIPressCtrl" ;
VAL_ 2566845694 CTIWheelSensorStatus_20 3 "NotSupported" 2 "NotDefined" 1 "On" 0 "Off_IsolatedFromCTIPressCtrl" ;
VAL_ 2566845694 CTIWheelSensorStatus_13 3 "NotSupported" 2 "NotDefined" 1 "On" 0 "Off_IsolatedFromCTIPressCtrl" ;
VAL_ 2566845694 CTIWheelSensorStatus_12 3 "NotSupported" 2 "NotDefined" 1 "On" 0 "Off_IsolatedFromCTIPressCtrl" ;
VAL_ 2566845694 CTIWheelSensorStatus_11 3 "NotSupported" 2 "NotDefined" 1 "On" 0 "Off_IsolatedFromCTIPressCtrl" ;
VAL_ 2566845694 CTIWheelSensorStatus_10 3 "NotSupported" 2 "NotDefined" 1 "On" 0 "Off_IsolatedFromCTIPressCtrl" ;
VAL_ 2566845694 CTIWheelSensorStatus_01 3 "NotSupported" 2 "NotDefined" 1 "On" 0 "Off_IsolatedFromCTIPressCtrl" ;
VAL_ 2566845694 CTIWheelEndElectricalFault_33 3 "NotSupported" 2 "Error" 1 "NotDefined" 0 "Ok" ;
VAL_ 2566845694 CTIWheelEndElectricalFault_32 3 "NotSupported" 2 "Error" 1 "NotDefined" 0 "Ok" ;
VAL_ 2566845694 CTIWheelEndElectricalFault_31 3 "NotSupported" 2 "Error" 1 "NotDefined" 0 "Ok" ;
VAL_ 2566845694 CTIWheelEndElectricalFault_30 3 "NotSupported" 2 "Error" 1 "NotDefined" 0 "Ok" ;
VAL_ 2566845694 CTIWheelEndElectricalFault_23 3 "NotSupported" 2 "Error" 1 "NotDefined" 0 "Ok" ;
VAL_ 2566845694 CTIWheelEndElectricalFault_22 3 "NotSupported" 2 "Error" 1 "NotDefined" 0 "Ok" ;
VAL_ 2566845694 CTIWheelEndElectricalFault_21 3 "NotSupported" 2 "Error" 1 "NotDefined" 0 "Ok" ;
VAL_ 2566845694 CTIWheelEndElectricalFault_20 3 "NotSupported" 2 "Error" 1 "NotDefined" 0 "Ok" ;
VAL_ 2566845694 CTIWheelEndElectricalFault_13 3 "NotSupported" 2 "Error" 1 "NotDefined" 0 "Ok" ;
VAL_ 2566845694 CTIWheelEndElectricalFault_12 3 "NotSupported" 2 "Error" 1 "NotDefined" 0 "Ok" ;
VAL_ 2566845694 CTIWheelEndElectricalFault_11 3 "NotSupported" 2 "Error" 1 "NotDefined" 0 "Ok" ;
VAL_ 2566845694 CTIWheelEndElectricalFault_10 3 "NotSupported" 2 "Error" 1 "NotDefined" 0 "Ok" ;
VAL_ 2566845694 CTIWheelEndElectricalFault_01 3 "NotSupported" 2 "Error" 1 "NotDefined" 0 "Ok" ;
VAL_ 2566845694 CTITireStatus_33 3 "NotSupported" 2 "Error" 1 "TireLeakDetected" 0 "Ok" ;
VAL_ 2566845694 CTITireStatus_32 3 "NotSupported" 2 "Error" 1 "TireLeakDetected" 0 "Ok" ;
VAL_ 2566845694 CTITireStatus_31 3 "NotSupported" 2 "Error" 1 "TireLeakDetected" 0 "Ok" ;
VAL_ 2566845694 CTITireStatus_30 3 "NotSupported" 2 "Error" 1 "TireLeakDetected" 0 "Ok" ;
VAL_ 2566845694 CTITireStatus_23 3 "NotSupported" 2 "Error" 1 "TireLeakDetected" 0 "Ok" ;
VAL_ 2566845694 CTITireStatus_22 3 "NotSupported" 2 "Error" 1 "TireLeakDetected" 0 "Ok" ;
VAL_ 2566845694 CTITireStatus_21 3 "NotSupported" 2 "Error" 1 "TireLeakDetected" 0 "Ok" ;
VAL_ 2566845694 CTITireStatus_20 3 "NotSupported" 2 "Error" 1 "TireLeakDetected" 0 "Ok" ;
VAL_ 2566845694 CTITireStatus_13 3 "NotSupported" 2 "Error" 1 "TireLeakDetected" 0 "Ok" ;
VAL_ 2566845694 CTITireStatus_12 3 "NotSupported" 2 "Error" 1 "TireLeakDetected" 0 "Ok" ;
VAL_ 2566845694 CTITireStatus_11 3 "NotSupported" 2 "Error" 1 "TireLeakDetected" 0 "Ok" ;
VAL_ 2566845694 CTITireStatus_10 3 "NotSupported" 2 "Error" 1 "TireLeakDetected" 0 "Ok" ;
VAL_ 2566845694 CTITireStatus_01 3 "NotSupported" 2 "Error" 1 "TireLeakDetected" 0 "Ok" ;
VAL_ 2566845694 TirePressThresholdDetection_33 7 "NotAvailable" 6 "ErrorIndicator" 5 "NotDefined" 4 "ExtrmUndrPrssTrPrssrIsAtALvlWhr" 3 "UndrPrssTrPrssrIsLwrThnThPrssrD" 2 "NWrnngPrssTrPrssrIsWthnThThrshl" 1 "OvrPrssTrPrssrIsHghrThnThPrssrD" 0 "ExtrmOvrPrssTrPrssrIsAtALvlWhrT" ;
VAL_ 2566845694 TirePressThresholdDetection_32 7 "NotAvailable" 6 "ErrorIndicator" 5 "NotDefined" 4 "ExtrmUndrPrssTrPrssrIsAtALvlWhr" 3 "UndrPrssTrPrssrIsLwrThnThPrssrD" 2 "NWrnngPrssTrPrssrIsWthnThThrshl" 1 "OvrPrssTrPrssrIsHghrThnThPrssrD" 0 "ExtrmOvrPrssTrPrssrIsAtALvlWhrT" ;
VAL_ 2566845694 TirePressThresholdDetection_31 7 "NotAvailable" 6 "ErrorIndicator" 5 "NotDefined" 4 "ExtrmUndrPrssTrPrssrIsAtALvlWhr" 3 "UndrPrssTrPrssrIsLwrThnThPrssrD" 2 "NWrnngPrssTrPrssrIsWthnThThrshl" 1 "OvrPrssTrPrssrIsHghrThnThPrssrD" 0 "ExtrmOvrPrssTrPrssrIsAtALvlWhrT" ;
VAL_ 2566845694 TirePressThresholdDetection_30 7 "NotAvailable" 6 "ErrorIndicator" 5 "NotDefined" 4 "ExtrmUndrPrssTrPrssrIsAtALvlWhr" 3 "UndrPrssTrPrssrIsLwrThnThPrssrD" 2 "NWrnngPrssTrPrssrIsWthnThThrshl" 1 "OvrPrssTrPrssrIsHghrThnThPrssrD" 0 "ExtrmOvrPrssTrPrssrIsAtALvlWhrT" ;
VAL_ 2566845694 TirePressThresholdDetection_23 7 "NotAvailable" 6 "ErrorIndicator" 5 "NotDefined" 4 "ExtrmUndrPrssTrPrssrIsAtALvlWhr" 3 "UndrPrssTrPrssrIsLwrThnThPrssrD" 2 "NWrnngPrssTrPrssrIsWthnThThrshl" 1 "OvrPrssTrPrssrIsHghrThnThPrssrD" 0 "ExtrmOvrPrssTrPrssrIsAtALvlWhrT" ;
VAL_ 2566845694 TirePressThresholdDetection_22 7 "NotAvailable" 6 "ErrorIndicator" 5 "NotDefined" 4 "ExtrmUndrPrssTrPrssrIsAtALvlWhr" 3 "UndrPrssTrPrssrIsLwrThnThPrssrD" 2 "NWrnngPrssTrPrssrIsWthnThThrshl" 1 "OvrPrssTrPrssrIsHghrThnThPrssrD" 0 "ExtrmOvrPrssTrPrssrIsAtALvlWhrT" ;
VAL_ 2566845694 TirePressThresholdDetection_21 7 "NotAvailable" 6 "ErrorIndicator" 5 "NotDefined" 4 "ExtrmUndrPrssTrPrssrIsAtALvlWhr" 3 "UndrPrssTrPrssrIsLwrThnThPrssrD" 2 "NWrnngPrssTrPrssrIsWthnThThrshl" 1 "OvrPrssTrPrssrIsHghrThnThPrssrD" 0 "ExtrmOvrPrssTrPrssrIsAtALvlWhrT" ;
VAL_ 2566845694 TirePressThresholdDetection_20 7 "NotAvailable" 6 "ErrorIndicator" 5 "NotDefined" 4 "ExtrmUndrPrssTrPrssrIsAtALvlWhr" 3 "UndrPrssTrPrssrIsLwrThnThPrssrD" 2 "NWrnngPrssTrPrssrIsWthnThThrshl" 1 "OvrPrssTrPrssrIsHghrThnThPrssrD" 0 "ExtrmOvrPrssTrPrssrIsAtALvlWhrT" ;
VAL_ 2566845694 TirePressThresholdDetection_00 7 "NotAvailable" 6 "ErrorIndicator" 5 "NotDefined" 4 "ExtrmUndrPrssTrPrssrIsAtALvlWhr" 3 "UndrPrssTrPrssrIsLwrThnThPrssrD" 2 "NWrnngPrssTrPrssrIsWthnThThrshl" 1 "OvrPrssTrPrssrIsHghrThnThPrssrD" 0 "ExtrmOvrPrssTrPrssrIsAtALvlWhrT" ;
VAL_ 2566845694 CTIWheelSensorStatus_00 3 "NotSupported" 2 "NotDefined" 1 "On" 0 "Off_IsolatedFromCTIPressCtrl" ;
VAL_ 2566845694 CTIWheelEndElectricalFault_00 3 "NotSupported" 2 "Error" 1 "NotDefined" 0 "Ok" ;
VAL_ 2566845694 CTITireStatus_00 3 "NotSupported" 2 "Error" 1 "TireLeakDetected" 0 "Ok" ;
VAL_ 2566821630 EngTrbWstgateActuator1TempStatus 7 "Not available" 6 "Error" 5 "Not Defined" 4 "Low Most severe" 3 "Low Least severe" 2 "In Range" 1 "High Least severe" 0 "High Most severe" ;
VAL_ 2365484286 DirectionIndicator 3 "Not available" 2 "Error" 1 "Reverse" 0 "Forward" ;
VAL_ 2365484286 TachographPerformance 3 "Not available" 2 "Error" 1 "Performance analysis" 0 "Normal performance" ;
VAL_ 2365484286 HandlingInformation 3 "Not available" 2 "Error" 1 "Handling information" 0 "No handling information" ;
VAL_ 2365484286 SystemEvent 3 "Not available" 2 "Error" 1 "Tachograph event" 0 "No tachograph event" ;
VAL_ 2365484286 DriverCardDriver2 3 "Not available" 2 "Error" 1 "Driver card present" 0 "Driver card not present" ;
VAL_ 2365484286 Driver2TimeRelatedStates 15 "Not available" 14 "Error" 13 "Other" 6 "Limit #6" 5 "Limit #5" 4 "Limit #4" 3 "Limit #3" 2 "Limit #2" 1 "Limit #1" 0 "Normal/No limits reached" ;
VAL_ 2365484286 VehicleOverspeed 3 "Not available" 2 "Error" 1 "Overspeed" 0 "No overspeed" ;
VAL_ 2365484286 DriverCardDriver1 3 "Not available" 2 "Error" 1 "Driver card present" 0 "Driver card not present" ;
VAL_ 2365484286 Driver1TimeRelatedStates 15 "Not available" 14 "Error" 13 "Other" 6 "Limit #6" 5 "Limit #5" 4 "Limit #4" 3 "Limit #3" 2 "Limit #2" 1 "Limit #1" 0 "Normal/No limits reached" ;
VAL_ 2365484286 VehicleMotion 3 "Not available" 2 "Error" 1 "Vehicle motion detected" 0 "Vehicle motion not detected" ;
VAL_ 2365484286 Driver2WorkingState 7 "Not available" 6 "Error" 3 "Drive" 2 "Work" 1 "Driver available" 0 "Rest" ;
VAL_ 2365484286 Driver1WorkingState 7 "Not available" 6 "Error" 3 "Drive" 2 "Work" 1 "Driver available" 0 "Rest" ;
VAL_ 2348941054 AutoNeutralReq 3 "Don뭪 Care / Take No Action" 2 "Reserved" 1 "Request to shift to Auto-Neutral state" 0 "No request to shift to Auto-Neutral state" ;
VAL_ 2348941054 TransMode8 3 "Take no action" 2 "Reserved" 1 "Enable" 0 "Disable" ;
VAL_ 2348941054 TransMode7 3 "Take no action" 2 "Reserved" 1 "Enable" 0 "Disable" ;
VAL_ 2348941054 TransMode6 3 "Take no action" 2 "Reserved" 1 "Enable" 0 "Disable" ;
VAL_ 2348941054 TransMode5 3 "Take no action" 2 "Reserved" 1 "Enable" 0 "Disable" ;
VAL_ 2348941054 TrnsShftSlectorDisplayModeSwitch 3 "Not available" 2 "Error" 1 "On" 0 "Off" ;
VAL_ 2348941054 TransRequestedLaunchGear 15 "Not Available" 14 "Error" 13 "Allow transmission to select the optimum launch gear" 12 "Launch the vehicle in Reverse 4" 11 "Launch the vehicle in Reverse 3" 10 "Launch the vehicle in Reverse 2" 9 "Launch the vehicle in Reverse 1" 8 "Launch the vehicle in 8th gear" 7 "Launch the vehicle in 7th gear" 6 "Launch the vehicle in 6th gear" 5 "Launch the vehicle in 5th gear" 4 "Launch the vehicle in 4th gear" 3 "Launch the vehicle in 3rd gear" 2 "Launch the vehicle in 2nd gear" 1 "Launch the vehicle in 1st gear" 0 "No specific launch gear requested" ;
VAL_ 2348941054 TransMode4 3 "Take no action" 2 "Reserved" 1 "Enable" 0 "Disable" ;
VAL_ 2348941054 TransMode3 3 "Take no action" 2 "Reserved" 1 "Enable" 0 "Disable" ;
VAL_ 2348941054 TransMode2 3 "Take no action" 2 "Reserved" 1 "Enable" 0 "Disable" ;
VAL_ 2348941054 TransMode1 3 "Take no action" 2 "Reserved" 1 "Enable" 0 "Disable" ;
VAL_ 2348941054 TransLoadReductionInhibitRq 3 "Don't care/take no action" 2 "Reserved" 1 "Inhibit or abort transmission load reduction functions" 0 "Allow or resume transmission load reduction functions" ;
VAL_ 2348941054 DisengageDiffLockRqCentralRear 3 "Take no action" 2 "Reserved" 1 "Disengage differential lock" 0 "Engage differential lock" ;
VAL_ 2348941054 DisengageDiffLockRqCentralFront 3 "Take no action" 2 "Reserved" 1 "Disengage differential lock" 0 "Engage differential lock" ;
VAL_ 2348941054 DisengageDiffLockRqCentral 3 "Take no action" 2 "Reserved" 1 "Disengage differential lock" 0 "Engage differential lock" ;
VAL_ 2348941054 DisengageDiffLockRqRearAxle2 3 "Take no action" 2 "Reserved" 1 "Disengage differential lock" 0 "Engage differential lock" ;
VAL_ 2348941054 DisengageDiffLockRqRearAxle1 3 "Take no action" 2 "Reserved" 1 "Disengage differential lock" 0 "Engage differential lock" ;
VAL_ 2348941054 DisengageDiffLockRqFrontAxle2 3 "Take no action" 2 "Reserved" 1 "Disengage differential lock" 0 "Engage differential lock" ;
VAL_ 2348941054 DisengageDiffLockRqFrontAxle1 3 "Take no action" 2 "Reserved" 1 "Disengage differential lock" 0 "Engage differential lock" ;
VAL_ 2348941054 TransRequestedGear 223 "Reverse Selector Position" 224 "Position unknown and/or no buttons pressed" 225 "Press of momentary button to reselect current position" 226 "Between 멢everse� and 멠ark� shift selector positions" 227 "Between 멞eutral� and 멢everse� shift selector positions" 228 "Between 멏rive� and 멞eutral� shift selector positions" 229 "Between D-1 and 멏rive� shift selector positions" 230 "Between D-2 and D-1 shift selector positions" 231 "Between D-3 and D-2 shift selector positions" 232 "Between D-4 and D-3 shift selector positions" 233 "Between D-5 and D-4 shift selector positions" 234 "Between D-6 and D-5 shift selector positions" 235 "Between D-7 and D-6 shift selector positions" 236 "Between two forward shift selector positions" 237 "Between two reverse shift selector positions" 238 "Between two shift selector positions" 239 "D-7: 7th forward selector position referenced from 멏rive�" 240 "D-6: 6th forward selector position referenced from 멏rive�" 241 "D-5: 5th forward selector position referenced from 멏rive�" 242 "D-4: 4th forward selector position referenced from 멏rive�" 243 "D-3: 3rd forward selector position referenced from 멏rive�" 244 "D-2: 2nd forward selector position referenced from 멏rive�" 245 "D-1: 1st forward selector position referenced from 멏rive�" 246 "Downshift 2 gears from current position" 247 "Downshift 1 gear from current position" 248 "Upshift 2 gears from current position" 249 "Upshift 1 gear from current position" 250 "Forward 멛ow� position" 251 "멠ark� position" 252 "Forward Drive Position" 253 "Hold current gear" ;
VAL_ 2348941054 TransReverseGearShiftInhibitRq 3 "Take no action" 2 "Reserved" 1 "Inhibit shifts into Reverse gear" 0 "Allow shifts into Reverse gear" ;
VAL_ 2348941054 DisengageDrivelineRq 3 "Take no action" 2 "Reserved" 1 "Disengage driveline" 0 "Allow driveline engagement" ;
VAL_ 2348941054 TrnsTrqeConverterLockupDisableRq 3 "Take no action" 2 "Request torque converter lockup" 1 "Disable torque converter lockup" 0 "Allow torque converter lockup" ;
VAL_ 2348941054 TransGearShiftInhibitRq 3 "Take no action " 2 "Reserved" 1 "Gear shifts are inhibited " 0 "Gear shifts are allowed " ;
VAL_ 2566839806 EngTurboOilLevelSwitch 3 "Not available" 2 "Error" 1 "Oil present at turbocharger" 0 "No oil present at turbocharger" ;
VAL_ 2566841598 EngOilPressSw 3 "Not Available" 2 "Error" 1 "Not OK" 0 "OK" ;
VAL_ 2566841598 ClntLvlEngPrtctionShutdownStatus 3 "Not Available" 2 "Reserved" 1 "Enabled" 0 "Disabled" ;
VAL_ 2566841598 PTOShutdownHasShutdownEng 3 "Not available" 2 "Error" 1 "Yes" 0 "No" ;
VAL_ 2566841598 EngAirShutoffStatus 2 "Error" 1 "Air flow restricted" 0 "Air flow allowed to engine" 3 "Not Available" ;
VAL_ 2566841598 EngOverspeedTest 3 "Not Available" 2 "Reserved" 1 "Engine Overspeed Test Active" 0 "Engine Overspeed Test Not Active" ;
VAL_ 2566841598 EngAirShutoffCmdStatus 3 "Not Available" 2 "Reserved" 1 "Air Shutoff Enabled" 0 "Air Shutoff Disabled" ;
VAL_ 2566841598 EngAlarmOutputCmdStatus 3 "Not Available" 2 "Reserved" 1 "Engine Alarm Output Command Active" 0 "Engine Alarm Output Command Not Active" ;
VAL_ 2566841598 EngAlarmAcknowledge 3 "Not Available" 2 "Error" 1 "Engine Alarm Acknowledge Active" 0 "Engine Alarm Acknowledge  Not Active" ;
VAL_ 2566841598 EngProtectionSystemConfig 3 "Not available" 2 "Error" 1 "Enabled in calibration" 0 "Disabled in calibration" ;
VAL_ 2566841598 EngProtectionSystemTimerState 3 "Not available" 2 "Error" 1 "Active" 0 "Inactive" ;
VAL_ 2566841598 EngProtectionSystemTimerOverride 3 "Not available" 2 "Error" 1 "Active" 0 "Inactive" ;
VAL_ 2566841598 EngPrtctnSystmApprachingShutdown 3 "Not available" 2 "Error" 1 "Approaching" 0 "Not approaching" ;
VAL_ 2566841598 EngPrtectionSystemHasShutdownEng 3 "Not available" 2 "Error" 1 "Yes" 0 "No" ;
VAL_ 2566841598 EngWaitToStartLamp 3 "Not available" 2 "Error" 1 "On" 0 "Off" ;
VAL_ 2566841598 RefrigerantHighPressSwitch 3 "Not available" 2 "Error" 1 "Pressure too high" 0 "Pressure normal" ;
VAL_ 2566841598 RefrigerantLowPressSwitch 3 "Not available" 2 "Error" 1 "Pressure too low" 0 "Pressure normal" ;
VAL_ 2566841598 A_CHighPressFanSwitch 3 "Not available" 2 "Error" 1 "Pressure high" 0 "Pressure normal" ;
VAL_ 2566841598 EngIdleShutdownTimerFunction 3 "Not available" 2 "Error" 1 "Enabled in calibration" 0 "Disabled in calibration" ;
VAL_ 2566841598 EngIdleShutdownTimerState 3 "Not available" 2 "Error" 1 "Active" 0 "Inactive" ;
VAL_ 2566841598 EngIdleShutdownTimerOverride 3 "Not available" 2 "Error" 1 "Active" 0 "Inactive" ;
VAL_ 2566841598 EngIdleShutdownDriverAlertMode 3 "Not available" 2 "Error" 1 "Active" 0 "Inactive" ;
VAL_ 2566841598 EngIdleShutdownHasShutdownEng 3 "Not available" 2 "Error" 1 "Yes" 0 "No" ;
